VERSION ""

NS_ :

BS_:

BU_: VCM TCM OBDScanT2 ECM

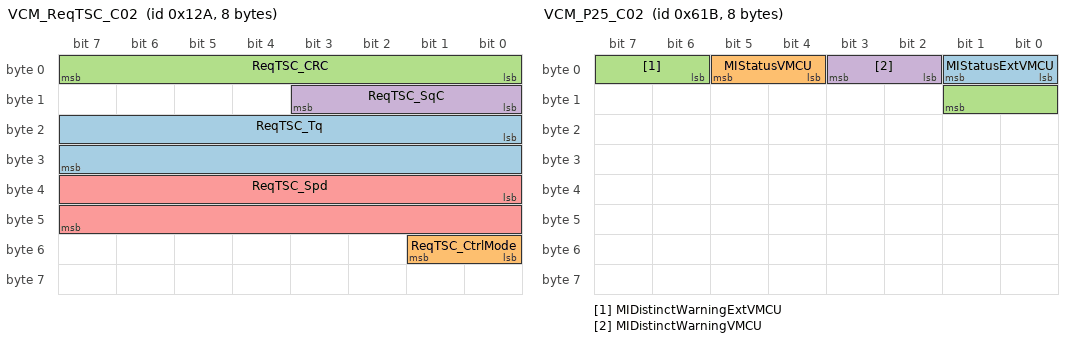
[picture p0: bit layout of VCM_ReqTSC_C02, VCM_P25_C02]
BO_ 298 VCM_ReqTSC_C02: 8 VCM
 SG_ ReqTSC_Tq : 16|16@1+ (1,-32128) [-32128|33407] "Nm"  TCM,ECM
 SG_ ReqTSC_CtrlMode : 48|2@1+ (1,0) [0|0] ""  ECM,TCM
 SG_ ReqTSC_CRC : 0|8@1+ (1,0) [0|255] ""  ECM,TCM
 SG_ ReqTSC_SqC : 8|4@1+ (1,0) [0|14] "NotApplicable"  TCM,ECM
 SG_ ReqTSC_Spd : 32|16@1+ (0.5,-16024) [-16024|16743.5] "rpm"  ECM,TCM

BO_ 568 VCM_P26_C02: 20 VCM
 SG_ EngSystPwrDwn_Rqst : 44|2@1+ (1,0) [0|0] ""  ECM
 SG_ TrnsmSystPwrDwn_SqC : 56|4@1+ (1,0) [0|14] "NotApplicable"  TCM
 SG_ EngSystPwrDwn_CRC : 32|8@1+ (1,0) [0|255] ""  ECM
 SG_ EngCrnk_Rqst : 28|2@1+ (1,0) [0|0] ""  ECM
 SG_ SecuredNeutralPosition_ISig_2 : 79|2@1+ (1,0) [0|0] ""  ECM
 SG_ TransmLowRangeSenseSwitch_ISig_2 : 73|2@1+ (1,0) [0|0] ""  ECM
 SG_ UpDownShiftRqst_CRC : 104|8@1+ (1,0) [0|255] ""  TCM
 SG_ TrnsmSystPwrDwn_Rqst : 60|2@1+ (1,0) [0|0] ""  TCM
 SG_ GearLeverPosition2_SqC : 128|4@1+ (1,0) [0|14] "NotApplicable"  TCM
 SG_ FrontAxleInBumperRange_ISig_2 : 64|2@1+ (1,0) [0|0] ""  TCM
 SG_ RollerBenchModeRequest_ISig_2 : 66|2@1+ (1,0) [0|0] ""  ECM
 SG_ EcnmyPwrSwt_Sts : 12|2@1+ (1,0) [0|0] ""  TCM
 SG_ RearAxleInBumperRange_ISig_2 : 68|2@1+ (1,0) [0|0] ""  TCM
 SG_ EngCrnk_SqC : 24|4@1+ (1,0) [0|14] "NotApplicable"  ECM
 SG_ EcnmyPwrSwt_CRC : 0|8@1+ (1,0) [0|255] ""  TCM
 SG_ EngCrnk_CRC : 16|8@1+ (1,0) [0|255] ""  ECM
 SG_ TractionControlDriverRqst_ISig_2 : 70|3@1+ (1,0) [0|0] ""  ECM
 SG_ EcnmyPwrSwt_SqC : 8|4@1+ (1,0) [0|14] "NotApplicable"  TCM
 SG_ DriveModeSwitchStat_CRC : 88|8@1+ (1,0) [0|255] ""  TCM
 SG_ TransmissionNeutralSwitch : 77|2@1+ (1,0) [0|0] ""  ECM
 SG_ ReverseGearEngaged_ISig_2 : 75|2@1+ (1,0) [0|0] ""  ECM
 SG_ GearLeverPosition2_Rqst : 132|4@1+ (1,0) [0|0] ""  TCM
 SG_ EngSystPwrDwn_SqC : 40|4@1+ (1,0) [0|14] "NotApplicable"  ECM
 SG_ UpDownShiftRqst_Rqst : 116|4@1+ (1,0) [0|0] ""  TCM
 SG_ LevelControlInformation_ISig_2 : 81|4@1+ (1,0) [0|0] ""  TCM
 SG_ TrnsmSystPwrDwn_CRC : 48|8@1+ (1,0) [0|255] ""  TCM
 SG_ DriveModeSwitchStat_SqC : 96|4@1+ (1,0) [0|14] "NotApplicable"  TCM
 SG_ GearLeverPosition2_CRC : 120|8@1+ (1,0) [0|255] ""  TCM
 SG_ DriveModeSwitchStat_Rqst : 100|2@1+ (1,0) [0|0] ""  TCM
 SG_ UpDownShiftRqst_SqC : 112|4@1+ (1,0) [0|14] "NotApplicable"  TCM

BO_ 1563 VCM_P25_C02: 8 VCM
 SG_ MIStatusExtVMCU : 0|2@1+ (1,0) [0|0] ""  ECM
 SG_ MIStatusVMCU : 4|2@1+ (1,0) [0|0] ""  ECM
 SG_ MIDistinctWarningExtVMCU : 6|4@1+ (1,0) [0|0] ""  ECM
 SG_ MIDistinctWarningVMCU : 2|2@1+ (1,0) [0|0] ""  ECM

BO_ 1310 VCM_P24_C02_FCM: 8 TCM
 SG_ VCM_P24_C02_FCS : 0|64@1+ (1,0) [0|0] ""  VCM

BO_ 1309 VCM_P24_C02: 284 VCM
 SG_ HillDataPkgTGW : 0|2272@1+ (1,0) [0|0] ""  TCM

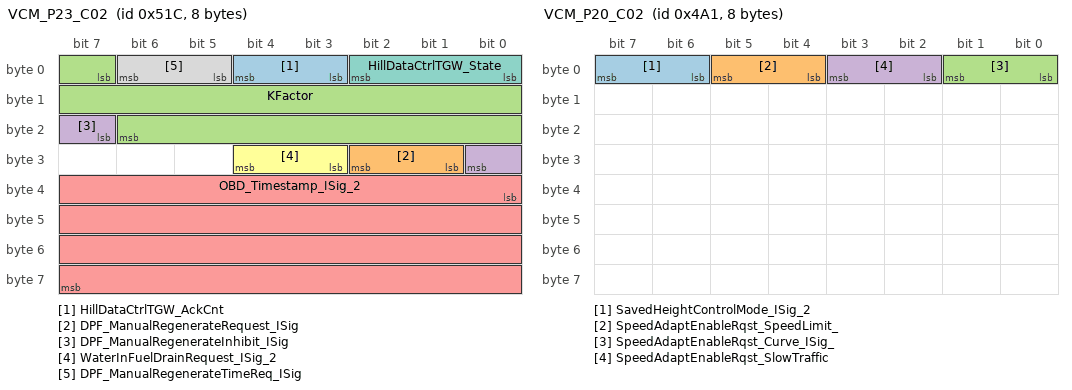
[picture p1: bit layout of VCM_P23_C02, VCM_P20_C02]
BO_ 1308 VCM_P23_C02: 8 VCM
 SG_ HillDataCtrlTGW_AckCnt : 3|2@1+ (1,0) [0|3] ""  TCM
 SG_ DPF_ManualRegenerateRequest_ISig : 25|2@1+ (1,0) [0|0] ""  ECM
 SG_ KFactor : 7|16@1+ (1,0) [0|65535] "NotApplicable"  TCM,ECM
 SG_ DPF_ManualRegenerateInhibit_ISig : 23|2@1+ (1,0) [0|0] ""  ECM
 SG_ OBD_Timestamp_ISig_2 : 32|32@1+ (1,0) [0|4294967295] "s"  ECM
 SG_ WaterInFuelDrainRequest_ISig_2 : 27|2@1+ (1,0) [0|0] ""  ECM
 SG_ HillDataCtrlTGW_State : 0|3@1+ (1,0) [0|0] ""  TCM
 SG_ DPF_ManualRegenerateTimeReq_ISig : 5|2@1+ (1,0) [0|0] ""  ECM

BO_ 1185 VCM_P20_C02: 8 VCM
 SG_ SavedHeightControlMode_ISig_2 : 6|2@1+ (1,0) [0|0] ""  TCM
 SG_ SpeedAdaptEnableRqst_SpeedLimit_ : 4|2@1+ (1,0) [0|0] ""  TCM
 SG_ SpeedAdaptEnableRqst_Curve_ISig_ : 0|2@1+ (1,0) [0|0] ""  TCM
 SG_ SpeedAdaptEnableRqst_SlowTraffic : 2|2@1+ (1,0) [0|0] ""  TCM

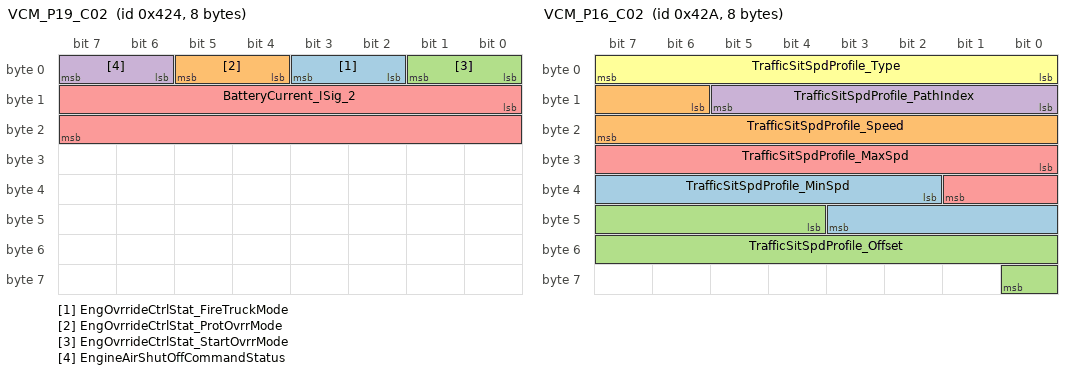
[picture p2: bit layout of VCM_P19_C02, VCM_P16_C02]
BO_ 1060 VCM_P19_C02: 8 VCM
 SG_ EngOvrrideCtrlStat_FireTruckMode : 2|2@1+ (1,0) [0|0] ""  ECM
 SG_ EngOvrrideCtrlStat_ProtOvrrMode : 4|2@1+ (1,0) [0|0] ""  ECM
 SG_ EngOvrrideCtrlStat_StartOvrrMode : 0|2@1+ (1,0) [0|0] ""  ECM
 SG_ EngineAirShutOffCommandStatus : 6|2@1+ (1,0) [0|0] ""  ECM
 SG_ BatteryCurrent_ISig_2 : 8|16@1+ (0.05,-1600) [-1600|1676.75] "A"  ECM

BO_ 932 VCM_P18_C02: 32 VCM
 SG_ VehGcvw : 64|8@1+ (1000,0) [0|255000] "kg"  TCM,ECM
 SG_ ReqdDrvgDir_CRC : 48|8@1+ (1,0) [0|255] ""  TCM
 SG_ SelfStartAssist_stat_ISig_2 : 96|2@1+ (1,0) [0|0] ""  ECM
 SG_ EcoRollEnableRequest_ISig_2 : 88|2@1+ (1,0) [0|0] ""  TCM
 SG_ SelectedEcoCruiseLevel : 101|3@1+ (1,0) [0|0] ""  ECM,TCM
 SG_ CCTrgtSpd_CRC : 216|8@1+ (1,0) [0|255] ""  ECM,TCM
 SG_ ReqdVehLongCtrlM_CRC : 152|8@1+ (1,0) [0|255] ""  TCM,ECM
 SG_ ReqdVehLongCtrlM_SqC : 160|4@1+ (1,0) [0|14] "NotApplicable"  ECM,TCM
 SG_ ACCiRollInhibit : 90|2@1+ (1,0) [0|0] ""  TCM
 SG_ ReqdDrvgMode : 92|4@1+ (1,0) [0|0] ""  TCM
 SG_ CCBTrgtSpd_CRC : 184|8@1+ (1,0) [0|255] ""  ECM,TCM
 SG_ ParkBrake_OBDState : 2|2@1+ (1,0) [0|0] ""  ECM
 SG_ AltParallelOperation : 4|2@1+ (1,0) [0|0] ""  ECM
 SG_ AltLR_cut_offSpeed : 16|5@1+ (1,0) [0|0] ""  ECM
 SG_ CCTrgtSpd_Rqst : 232|16@1+ (0.00390625,0) [0|255.99609375] "Km_per_h"  ECM,TCM
 SG_ MaintOilQuality : 106|3@1+ (1,0) [0|0] ""  ECM
 SG_ AirDryerCoolingFanSpeed_rqst : 136|16@1+ (1,0) [0|65535] "rpm"  ECM
 SG_ VIN_rqst_ISig_2 : 74|1@1+ (1,0) [0|0] ""  ECM,TCM
 SG_ ReqdEcoRoll : 72|2@1+ (1,0) [0|0] ""  TCM
 SG_ CCBTrgtSpd_Rqst : 200|16@1+ (0.00390625,0) [0|255.99609375] "Km_per_h"  TCM,ECM
 SG_ AltVoltageSetValue : 32|8@1+ (0.1,22) [22|47.5] "V"  ECM
 SG_ ACCiSeeDistanceGap : 80|8@1+ (1,-127) [-127|128] "m"  TCM
 SG_ ReqdVehLongCtrlM_Mode : 164|3@1+ (1,0) [0|0] ""  TCM,ECM
 SG_ CCBTrgtSpd_SqC : 192|4@1+ (1,0) [0|14] "NotApplicable"  ECM,TCM
 SG_ ACCoolingFanSpeedRequest : 120|16@1+ (1,0) [0|65535] "rpm"  ECM
 SG_ SpeedAdaptationLevelRqst_ISig_2 : 109|3@1+ (1,0) [0|0] ""  TCM
 SG_ ReqdGear : 75|5@1+ (1,-12) [-12|19] "NotApplicable"  TCM
 SG_ AltExitationCurrentLimit : 40|8@1+ (0.1,0) [0|25.5] "A"  ECM
 SG_ ReqdSGoMode_SqC : 176|4@1+ (1,0) [0|14] "NotApplicable"  ECM,TCM
 SG_ ReqdSGoMode_CRC : 168|8@1+ (1,0) [0|255] ""  ECM,TCM
 SG_ RSLAssistStatus : 98|3@1+ (1,0) [0|0] ""  TCM
 SG_ CCTrgtSpd_SqC : 224|4@1+ (1,0) [0|14] "NotApplicable"  ECM,TCM
 SG_ AcCoolantPumpEngagementRequest_I : 112|8@1+ (0.4,0) [0|102] "Percent"  ECM
 SG_ CruiseControlStates : 6|3@1+ (1,0) [0|0] ""  ECM,TCM
 SG_ AltDataSelectionWordRx : 12|4@1+ (1,0) [0|0] ""  ECM
 SG_ ClutchSwitch_ISig_2 : 0|2@1+ (1,0) [0|0] ""  ECM
 SG_ ReqdSGoMode_Mode : 180|4@1+ (1,0) [0|0] ""  ECM,TCM
 SG_ MaintOilReset : 104|2@1+ (1,0) [0|0] ""  ECM
 SG_ AltLR_RampTime : 21|5@1+ (1,0) [0|0] ""  ECM
 SG_ ReqdDrvgDir_Direction : 60|3@1+ (1,0) [0|0] ""  TCM
 SG_ CACCStatus_ISig_2 : 9|3@1+ (1,0) [0|0] ""  TCM
 SG_ ReqdDrvgDir_SqC : 56|4@1+ (1,0) [0|14] "NotApplicable"  TCM

BO_ 1066 VCM_P16_C02: 8 VCM
 SG_ TrafficSitSpdProfile_MinSpd : 34|10@1+ (0.25,0) [0|255.75] "Km_per_h"  TCM
 SG_ TrafficSitSpdProfile_Speed : 14|10@1+ (0.25,0) [0|255.75] "Km_per_h"  TCM
 SG_ TrafficSitSpdProfile_Offset : 44|13@1+ (1,0) [0|8191] "m"  TCM
 SG_ TrafficSitSpdProfile_PathIndex : 8|6@1+ (1,0) [0|0] ""  TCM
 SG_ TrafficSitSpdProfile_MaxSpd : 24|10@1+ (0.25,0) [0|255.75] "Km_per_h"  TCM
 SG_ TrafficSitSpdProfile_Type : 0|8@1+ (1,0) [0|0] ""  TCM

BO_ 300 VCM_P15_C02: 16 VCM
 SG_ XRSLBTrgtSpd_CRC : 0|8@1+ (1,0) [0|255] ""  TCM,ECM
 SG_ AcceleratorPedalPositionVendor : 88|8@1+ (0.4,0) [0|102] "Percent"  TCM
 SG_ AccPedal_Pos : 80|8@1+ (0.4,0) [0|102] "Percent"  ECM,TCM
 SG_ XRSLTrgtSpd_CRC : 32|8@1+ (1,0) [0|255] ""  ECM
 SG_ AccPedal_Qlty : 76|2@1+ (1,0) [0|0] ""  TCM,ECM
 SG_ XRSLBTrgtSpd_SqC : 8|4@1+ (1,0) [0|14] "NotApplicable"  TCM,ECM
 SG_ XRSLTrgtSpd_SqC : 40|4@1+ (1,0) [0|14] "NotApplicable"  ECM
 SG_ AccPedal_SqC : 72|4@1+ (1,0) [0|14] "NotApplicable"  ECM,TCM
 SG_ XRSLTrgtSpd_Rqst : 48|16@1+ (0.00390625,0) [0|255.99609375] "Km_per_h"  ECM
 SG_ XRSLBTrgtSpd_Rqst : 16|16@1+ (0.00390625,0) [0|255.99609375] "Km_per_h"  ECM,TCM
 SG_ AccPedal_CRC : 64|8@1+ (1,0) [0|255] ""  TCM,ECM

BO_ 1246 VCM_P10_C02: 16 VCM
 SG_ TagAxleLoad_ISig_2 : 0|16@1+ (0.5,0) [0|32767.5] "kg"  TCM
 SG_ SecondaryDriveAxleLoad_ISig_2 : 48|16@1+ (0.5,0) [0|32767.5] "kg"  ECM,TCM
 SG_ StarterMotorReset_rqst : 64|2@1+ (1,0) [0|0] ""  ECM
 SG_ PwtCCUnderSpeedRequest : 72|16@1+ (0.00390625,0) [0|255.99609375] "Km_per_h"  TCM
 SG_ FrontAxle1Load_ISig_2 : 88|16@1+ (0.5,0) [0|32767.5] "kg"  TCM
 SG_ FrontAxle2Load_ISig_2 : 104|16@1+ (0.5,0) [0|32767.5] "kg"  TCM
 SG_ PusherAxleLoad_ISig_2 : 16|16@1+ (0.5,0) [0|32767.5] "kg"  TCM
 SG_ DriveAxleLoad_ISig_2 : 32|16@1+ (0.5,0) [0|32767.5] "kg"  TCM

BO_ 746 VCM_P07_C02: 32 VCM
 SG_ Pto1ConsentRequest : 24|2@1+ (1,0) [0|0] ""  TCM
 SG_ CCBSetSpeed : 48|16@1+ (0.00390625,0) [0|255.99609375] "Km_per_h"  TCM
 SG_ SecondThrottle : 34|2@1+ (1,0) [0|0] ""  ECM
 SG_ CCBTargetSpeedRequest : 80|16@1+ (0.00390625,0) [0|255.99609375] "Km_per_h"  TCM,ECM
 SG_ TransferCaseOrSplitboxPTOMode_IS : 26|2@1+ (1,0) [0|0] ""  TCM
 SG_ PtosStatus_ISig_2 : 36|2@1+ (1,0) [0|0] ""  ECM
 SG_ ConstructionSwitch_stat : 4|2@1+ (1,0) [0|0] ""  TCM
 SG_ RegenInhibitVehicleHeight_ISig_2 : 16|2@1+ (1,0) [0|0] ""  ECM
 SG_ PtoRequest : 18|2@1+ (1,0) [0|0] ""  ECM
 SG_ Pto2Status_ISig_2 : 22|2@1+ (1,0) [0|0] ""  TCM
 SG_ TrailerConnected_ISig_2 : 38|2@1+ (1,0) [0|0] ""  ECM,TCM
 SG_ WarmUp_Request : 42|2@1+ (1,0) [0|0] ""  ECM
 SG_ ParkBrakeReleasePossible_stat_IS : 14|2@1+ (1,0) [0|0] ""  TCM
 SG_ AC_CompressorClutchCmd_ISig_2 : 0|2@1+ (1,0) [0|0] ""  ECM
 SG_ CCSetSpeed_ISig_2 : 64|16@1+ (0.00390625,0) [0|255.99609375] "Km_per_h"  TCM
 SG_ ESCReqEMS_CtrlTrimReq : 160|3@1+ (1,0) [0|0] ""  ECM,TCM
 SG_ ESCReqEMS_CtrlTrimValue : 152|8@1+ (10,0) [0|2550] ""  ECM,TCM
 SG_ Pto1Status_ISig_2 : 20|2@1+ (1,0) [0|0] ""  TCM
 SG_ ESCReqEMS_CtrlTrimStat : 163|3@1+ (1,0) [0|0] ""  ECM,TCM
 SG_ XRSLTargetSpeedRequest : 96|16@1+ (0.00390625,0) [0|255.99609375] "Km_per_h"  ECM
 SG_ CtaGcAlternativeGearStarter : 6|2@1+ (1,0) [0|0] ""  TCM
 SG_ XRSLBTargetSpeedRequest : 128|16@1+ (0.00390625,0) [0|255.99609375] "Km_per_h"  TCM,ECM
 SG_ Pto2ConsentRequest : 32|2@1+ (1,0) [0|0] ""  TCM
 SG_ EngPtoConsumesTorque : 12|2@1+ (1,0) [0|0] ""  TCM
 SG_ ESCReqEMS_CtrlTrimMode : 166|4@1+ (1,0) [0|0] ""  TCM,ECM
 SG_ TrailerABSStatus_ISig_2 : 40|2@1+ (1,0) [0|0] ""  ECM,TCM
 SG_ CtaGcInhibitGearEngaged : 8|2@1+ (1,0) [0|0] ""  TCM
 SG_ RearEndPositionStatus_ISig_2 : 28|3@1+ (1,0) [0|0] ""  TCM
 SG_ StoreIdleValue_ISig_2 : 146|2@1+ (1,0) [0|0] ""  ECM
 SG_ CtaGcReverseInhibit : 10|2@1+ (1,0) [0|0] ""  TCM
 SG_ CCTargetSpeedRequest : 112|16@1+ (0.00390625,0) [0|255.99609375] "Km_per_h"  TCM,ECM
 SG_ AirCompressorStatus_ISig_2 : 2|2@1+ (1,0) [0|0] ""  ECM

BO_ 391 VCM_P02_C02: 48 VCM
 SG_ ReqdLongDist_AllwdBndUppr : 224|16@1+ (0.01,0) [0|655.35] "m"  TCM
 SG_ ParkingBrake_stat_ISig_2 : 62|2@1+ (1,0) [0|0] ""  TCM,ECM
 SG_ ReqdLongSpd_CRC : 80|8@1+ (1,0) [0|255] ""  TCM,ECM
 SG_ RequestedUpshiftDownshiftSteps : 5|3@1+ (1,0) [0|0] ""  TCM
 SG_ LiftAxle1PositionStatus_ISig_2 : 23|3@1+ (1,0) [0|0] ""  TCM
 SG_ EngineSystemPowerDownRequest : 38|2@1+ (1,0) [0|0] ""  ECM
 SG_ LimpHomeSwitch_stat : 14|2@1+ (1,0) [0|0] ""  TCM
 SG_ ReqdLongSpd_SqC : 88|4@1+ (1,0) [0|14] "NotApplicable"  TCM,ECM
 SG_ ReqdLongDist_Distance : 192|16@1+ (0.01,0) [0|655.35] "m"  TCM
 SG_ EconomyPowerSwitch_stat : 16|2@1+ (1,0) [0|0] ""  TCM
 SG_ AcceleratorPedalPositionBackup : 72|8@1+ (0.4,0) [0|102] "Percent"  TCM,ECM
 SG_ UpShiftRequest : 8|2@1+ (1,0) [0|0] ""  ECM,TCM
 SG_ ACCForwardVehicleDistance : 40|8@1+ (1,0) [0|255] "m"  TCM
 SG_ EngineStopRequest : 36|2@1+ (1,0) [0|0] ""  ECM
 SG_ EngineOperationCtrl : 29|3@1+ (1,0) [0|0] ""  TCM,ECM
 SG_ DownShiftRequest : 10|2@1+ (1,0) [0|0] ""  ECM,TCM
 SG_ CM_DisengageDrivelineRequest : 21|2@1+ (1,0) [0|0] ""  TCM
 SG_ ReqdLongAccel_SqC : 152|4@1+ (1,0) [0|14] "NotApplicable"  TCM,ECM
 SG_ ReqdLongAccel_CRC : 144|8@1+ (1,0) [0|255] ""  ECM,TCM
 SG_ TransmSystemPowerDown_rqst : 32|2@1+ (1,0) [0|0] ""  TCM
 SG_ ReqdLongDist_CRC : 176|8@1+ (1,0) [0|255] ""  TCM
 SG_ ACC_Status_ISig_2 : 18|3@1+ (1,0) [0|0] ""  TCM
 SG_ ReqdLongSpd_AllwdBndUppr : 128|16@1+ (0.00390625,0) [0|255.99609375] "Km_per_h"  ECM,TCM
 SG_ XARDACU_AccelDemand : 240|16@1+ (0.00048828125,-15.687) [-15.687|16.31251171875] "m_per_s_squared"  ECM,TCM
 SG_ SteeringValvePositionSetPoint : 64|8@1+ (1,0) [0|255] "Percent"  ECM
 SG_ ParkBrakeActuationStatus_ISig_2 : 26|3@1+ (1,0) [0|0] ""  TCM
 SG_ GearLeverPosition_ISig_2 : 0|4@1+ (1,0) [0|0] ""  ECM,TCM
 SG_ EngineCrankRequest : 34|2@1+ (1,0) [0|0] ""  ECM
 SG_ RequestForHighestGearRatio : 12|2@1+ (1,0) [0|0] ""  TCM
 SG_ XARDACU_ControlMode : 258|2@1+ (1,0) [0|0] ""  ECM,TCM
 SG_ EnginePreheat_rqst : 58|2@1+ (1,0) [0|0] ""  ECM
 SG_ ReqdLongAccel_CtrlMode : 156|2@1+ (1,0) [0|0] ""  TCM,ECM
 SG_ ReqdLongDist_AllwdBndLowr : 208|16@1+ (0.01,0) [0|655.35] "m"  TCM
 SG_ ReqdLongSpd_Spd : 96|16@1+ (0.00390625,0) [0|255.99609375] "Km_per_h"  TCM,ECM
 SG_ ReqdLongSpd_AllwdBndLowr : 112|16@1+ (0.00390625,0) [0|255.99609375] "Km_per_h"  TCM,ECM
 SG_ ACCForwardVehicleSpeed : 48|8@1+ (1,0) [0|255] "Km_per_h"  TCM
 SG_ ReqdLongDist_SqC : 184|4@1+ (1,0) [0|14] "NotApplicable"  TCM
 SG_ ReqdLongAccel_Accel : 160|16@1+ (0.00048828125,-15.687) [-15.687|16.31251171875] "m_per_s_squared"  ECM,TCM

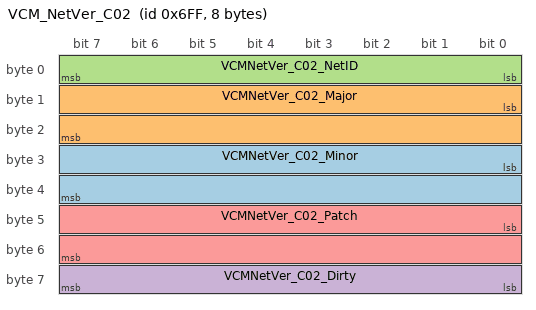
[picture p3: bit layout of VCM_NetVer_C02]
BO_ 1791 VCM_NetVer_C02: 8 VCM
 SG_ VCMNetVer_C02_Minor : 24|16@1+ (1,0) [0|65535] "Not Applicable" Vector__XXX
 SG_ VCMNetVer_C02_Major : 8|16@1+ (1,0) [0|65535] "Not Applicable" Vector__XXX
 SG_ VCMNetVer_C02_NetID : 0|8@1+ (1,0) [0|255] "NotApplicable" Vector__XXX
 SG_ VCMNetVer_C02_Dirty : 56|8@1+ (1,0) [0|255] "NotApplicable" Vector__XXX
 SG_ VCMNetVer_C02_Patch : 40|16@1+ (1,0) [0|65535] "Not Applicable" Vector__XXX

CM_ "COM_MATRIX_T3_2.3.0";
CM_ BU_ VCM "Vehicle Control Module";
CM_ BU_ TCM "Transmission Control Module";
CM_ BU_ ECM "Engine Control Module";
CM_ SG_ 746 ESCReqEMS_CtrlTrimValue "254 Error ; 255 Not available";
CM_ SG_ 391 XARDACU_AccelDemand "65024 - 65279 Error ; 65280 - 65535 Not available";
BA_DEF_ BO_  "GenMsgStartDelayTime" INT 0 0;
BA_DEF_ BO_  "GenMsgDelayTime" INT 0 0;
BA_DEF_ BO_  "GenMsgCycleTime" INT 0 0;
BA_DEF_ BO_  "GenMsgSendType" ENUM  "Cyclic","NotUsed","NotUsed","NotUsed","NotUsed","NotUsed","NotUsed","IfActive","NoMsgSendType","NotUsed";
BA_DEF_ SG_  "GenSigStartValue" INT 0 0;
BA_DEF_ SG_  "GenSigCycleTimeActive" INT 0 0;
BA_DEF_ SG_  "GenSigCycleTime" INT 0 0;
BA_DEF_ SG_  "GenSigSendType" ENUM  "Cyclic","OnWrite","OnWriteWithRepetition","OnChange","OnChangeWithRepetition","IfActive","IfActiveWithRepetition","NoSigSendType","NotUsed","NotUsed","NotUsed","NotUsed","NotUsed";
BA_DEF_  "Baudrate" INT 0 1000000;
BA_DEF_  "NmType" STRING ;
BA_DEF_  "Manufacturer" STRING ;
BA_DEF_  "VersionYear" INT 0 99;
BA_DEF_  "VersionNumber" INT 0 99;
BA_DEF_  "VersionMonth" INT 1 12;
BA_DEF_  "VersionDay" INT 1 31;
BA_DEF_ BO_  "VFrameFormat" ENUM  "StandardCAN","ExtendedCAN","reserved","J1939PG","reserved","reserved","reserved","reserved","reserved","reserved","reserved","reserved","reserved","reserved","StandardCAN_FD","ExtendedCAN_FD";
BA_DEF_ BU_  "TpOwnSystemEcuNumber" HEX 0 255;
BA_DEF_ SG_  "SigType" ENUM  "Default","Range","RangeSigned","ASCII","Discrete","Control","ReferencePGN","DTC","StringDelimiter","StringLength","StringLengthControl";
BA_DEF_ SG_  "SeToolVersion_SIGNAL" STRING ;
BA_DEF_ SG_  "SeToolUniqueID_SIGNAL" STRING ;
BA_DEF_ SG_  "SeToolOwnerSigGroup_SIGNAL" STRING ;
BA_DEF_ SG_  "SeToolOwnerSigGroupID_SIGNAL" STRING ;
BA_DEF_ SG_  "SeToolName_SIGNAL" STRING ;
BA_DEF_ SG_  "SeToolItemID_SIGNAL" STRING ;
BA_DEF_ SG_  "SeToolAncestorID_SIGNAL" STRING ;
BA_DEF_ SG_  "Platform_VMCU1_Sig" ENUM  "No","Yes";
BA_DEF_ BU_  "NmStationAddress" INT 0 255;
BA_DEF_  "NmAsrWaitBusSleepTime" INT 0 65535;
BA_DEF_  "NmAsrTimeoutTime" INT 0 65535;
BA_DEF_  "NmAsrRepeatMessageTime" INT 0 65535;
BA_DEF_ BU_  "NmAsrNodeIdentifier" HEX 0 253;
BA_DEF_ BU_  "NmAsrNode" ENUM  "No","Yes";
BA_DEF_  "NmAsrMessageCount" INT 1 256;
BA_DEF_ BO_  "NmAsrMessage" ENUM  "No","Yes";
BA_DEF_  "NmAsrCanMsgCycleTime" INT 0 65535;
BA_DEF_  "NmAsrBaseAddress" HEX 0 536870911;
BA_DEF_ SG_  "MmAnSignal" ENUM  "No","Yes";
BA_DEF_ BU_  "IsOBDrelevant" ENUM  "No","Yes";
BA_DEF_ SG_  "GenSigMaxLatency" INT 0 65535;
BA_DEF_ SG_  "GenSigILSupport" ENUM  "Yes","No";
BA_DEF_ BO_  "GenMsgILSupport" ENUM  "No","Yes";
BA_DEF_ SG_  "E2EProfile" STRING ;
BA_DEF_  "E2EP05WindowSize" INT 0 65535;
BA_DEF_  "E2EP05ProfileName" STRING ;
BA_DEF_  "E2EP05MinOkStateValid" INT 0 65535;
BA_DEF_  "E2EP05MinOkStateInvalid" INT 0 65535;
BA_DEF_  "E2EP05MinOkStateInit" INT 0 65535;
BA_DEF_  "E2EP05MaxErrorStateValid" INT 0 65535;
BA_DEF_  "E2EP05MaxErrorStateInvalid" INT 0 65535;
BA_DEF_  "E2EP05MaxErrorStateInit" INT 0 65535;
BA_DEF_  "E2EP05MaxDeltaCounter" INT 0 65535;
BA_DEF_  "E2EP01WindowSize" INT 0 65535;
BA_DEF_  "E2EP01SyncCounterInit" INT 0 65535;
BA_DEF_  "E2EP01ProfileName" STRING ;
BA_DEF_  "E2EP01MinOkStateValid" INT 0 65535;
BA_DEF_  "E2EP01MinOkStateInvalid" INT 0 65535;
BA_DEF_  "E2EP01MinOkStateInit" INT 0 65535;
BA_DEF_  "E2EP01MaxNoNewOrRepeatedData" INT 0 65535;
BA_DEF_  "E2EP01MaxErrorStateValid" INT 0 65535;
BA_DEF_  "E2EP01MaxErrorStateInvalid" INT 0 65535;
BA_DEF_  "E2EP01MaxErrorStateInit" INT 0 65535;
BA_DEF_  "E2EP01MaxDeltaCounter" INT 0 65535;
BA_DEF_  "E2EP01DataIdMode" ENUM  "all16Bit","alternating8Bit","lower12Bit","lower8Bit";
BA_DEF_  "E2EP01CounterOffset" INT 0 65535;
BA_DEF_ SG_  "E2EDataLength" INT 0 65535;
BA_DEF_ SG_  "E2EDataId" INT 0 65535;
BA_DEF_ BU_  "DiagnosticClientAddress" HEX 0 255;
BA_DEF_ BO_  "DiagUUDTResponse" ENUM  "No","Yes";
BA_DEF_ BO_  "DiagState" ENUM  "No","Yes";
BA_DEF_ BU_  "DiagRole" ENUM  "None","OBDTester","ExternalTester","InternalTester";
BA_DEF_ BO_  "DiagResponse" ENUM  "No","Yes";
BA_DEF_ BO_  "DiagRequest" ENUM  "No","Yes";
BA_DEF_ BO_  "DiagConnection" HEX 0 65535;
BA_DEF_  "DBName" STRING ;
BA_DEF_ BO_  "CanTpFcFrameId" HEX 0 2147483647;
BA_DEF_ BO_  "CanTpBs" INT 0 255;
BA_DEF_ BO_  "CANFD_BRS" ENUM  "0","1";
BA_DEF_  "BusType" STRING ;
BA_DEF_  "BaudrateCANFD" INT 0 5000000;
BA_DEF_ SG_  "SystemSignalLongSymbol" STRING ;
BA_DEF_REL_ BU_SG_REL_  "GenSigTimeoutTime" INT 0 65535;
BA_DEF_REL_ BU_SG_REL_  "GenSigFirstTimeoutTime" INT 0 65535;
BA_DEF_DEF_  "GenMsgStartDelayTime" 0;
BA_DEF_DEF_  "GenMsgDelayTime" 0;
BA_DEF_DEF_  "GenMsgCycleTime" 0;
BA_DEF_DEF_  "GenMsgSendType" "Cyclic";
BA_DEF_DEF_  "GenSigStartValue" 0;
BA_DEF_DEF_  "GenSigCycleTimeActive" 0;
BA_DEF_DEF_  "GenSigCycleTime" 0;
BA_DEF_DEF_  "GenSigSendType" "Cyclic";
BA_DEF_DEF_  "Baudrate" 500000;
BA_DEF_DEF_  "NmType" "";
BA_DEF_DEF_  "Manufacturer" "VOLVO_AB";
BA_DEF_DEF_  "VersionYear" 0;
BA_DEF_DEF_  "VersionNumber" 0;
BA_DEF_DEF_  "VersionMonth" 1;
BA_DEF_DEF_  "VersionDay" 1;
BA_DEF_DEF_  "VFrameFormat" "ExtendedCAN";
BA_DEF_DEF_  "TpOwnSystemEcuNumber" 0;
BA_DEF_DEF_  "SigType" "Default";
BA_DEF_DEF_  "SeToolVersion_SIGNAL" "";
BA_DEF_DEF_  "SeToolUniqueID_SIGNAL" "";
BA_DEF_DEF_  "SeToolOwnerSigGroup_SIGNAL" "";
BA_DEF_DEF_  "SeToolOwnerSigGroupID_SIGNAL" "";
BA_DEF_DEF_  "SeToolName_SIGNAL" "";
BA_DEF_DEF_  "SeToolItemID_SIGNAL" "";
BA_DEF_DEF_  "SeToolAncestorID_SIGNAL" "";
BA_DEF_DEF_  "Platform_VMCU1_Sig" "No";
BA_DEF_DEF_  "NmStationAddress" 254;
BA_DEF_DEF_  "NmAsrWaitBusSleepTime" 750;
BA_DEF_DEF_  "NmAsrTimeoutTime" 5000;
BA_DEF_DEF_  "NmAsrRepeatMessageTime" 300;
BA_DEF_DEF_  "NmAsrNodeIdentifier" 0;
BA_DEF_DEF_  "NmAsrNode" "Yes";
BA_DEF_DEF_  "NmAsrMessageCount" 256;
BA_DEF_DEF_  "NmAsrMessage" "No";
BA_DEF_DEF_  "NmAsrCanMsgCycleTime" 200;
BA_DEF_DEF_  "NmAsrBaseAddress" 486506496;
BA_DEF_DEF_  "MmAnSignal" "No";
BA_DEF_DEF_  "IsOBDrelevant" "No";
BA_DEF_DEF_  "GenSigMaxLatency" 0;
BA_DEF_DEF_  "GenSigILSupport" "Yes";
BA_DEF_DEF_  "GenMsgILSupport" "Yes";
BA_DEF_DEF_  "E2EProfile" "none";
BA_DEF_DEF_  "E2EP05WindowSize" 5;
BA_DEF_DEF_  "E2EP05ProfileName" "PROFILE_05";
BA_DEF_DEF_  "E2EP05MinOkStateValid" 1;
BA_DEF_DEF_  "E2EP05MinOkStateInvalid" 3;
BA_DEF_DEF_  "E2EP05MinOkStateInit" 1;
BA_DEF_DEF_  "E2EP05MaxErrorStateValid" 3;
BA_DEF_DEF_  "E2EP05MaxErrorStateInvalid" 1;
BA_DEF_DEF_  "E2EP05MaxErrorStateInit" 2;
BA_DEF_DEF_  "E2EP05MaxDeltaCounter" 3;
BA_DEF_DEF_  "E2EP01WindowSize" 5;
BA_DEF_DEF_  "E2EP01SyncCounterInit" 1;
BA_DEF_DEF_  "E2EP01ProfileName" "PROFILE_01";
BA_DEF_DEF_  "E2EP01MinOkStateValid" 1;
BA_DEF_DEF_  "E2EP01MinOkStateInvalid" 3;
BA_DEF_DEF_  "E2EP01MinOkStateInit" 1;
BA_DEF_DEF_  "E2EP01MaxNoNewOrRepeatedData" 5;
BA_DEF_DEF_  "E2EP01MaxErrorStateValid" 3;
BA_DEF_DEF_  "E2EP01MaxErrorStateInvalid" 1;
BA_DEF_DEF_  "E2EP01MaxErrorStateInit" 2;
BA_DEF_DEF_  "E2EP01MaxDeltaCounter" 3;
BA_DEF_DEF_  "E2EP01DataIdMode" "all16Bit";
BA_DEF_DEF_  "E2EP01CounterOffset" 8;
BA_DEF_DEF_  "E2EDataLength" 0;
BA_DEF_DEF_  "E2EDataId" 0;
BA_DEF_DEF_  "DiagnosticClientAddress" 0;
BA_DEF_DEF_  "DiagUUDTResponse" "No";
BA_DEF_DEF_  "DiagState" "No";
BA_DEF_DEF_  "DiagRole" "None";
BA_DEF_DEF_  "DiagResponse" "No";
BA_DEF_DEF_  "DiagRequest" "No";
BA_DEF_DEF_  "DiagConnection" 0;
BA_DEF_DEF_  "DBName" "";
BA_DEF_DEF_  "CanTpFcFrameId" 2147483647;
BA_DEF_DEF_  "CanTpBs" 255;
BA_DEF_DEF_  "CANFD_BRS" "0";
BA_DEF_DEF_  "BusType" "";
BA_DEF_DEF_  "BaudrateCANFD" 0;
BA_DEF_DEF_REL_ "GenSigTimeoutTime" 0;
BA_DEF_DEF_REL_ "GenSigFirstTimeoutTime" 0;
BA_DEF_DEF_  "SystemSignalLongSymbol" "";
BA_ "NmType" "NmAsr";
BA_ "BusType" "CAN FD";
BA_ "BaudrateCANFD" 1000000;
BA_ "VersionDay" 27;
BA_ "VersionMonth" 2;
BA_ "VersionNumber" 1;
BA_ "VersionYear" 23;
BA_ "DBName" "CAN02";
BA_ "DiagRole" BU_ VCM 3;
BA_ "DiagnosticClientAddress" BU_ VCM 244;
BA_ "IsOBDrelevant" BU_ VCM 1;
BA_ "TpOwnSystemEcuNumber" BU_ VCM 36;
BA_ "NmAsrNodeIdentifier" BU_ VCM 36;
BA_ "TpOwnSystemEcuNumber" BU_ TCM 24;
BA_ "NmAsrNodeIdentifier" BU_ TCM 24;
BA_ "NmAsrNode" BU_ OBDScanT2 0;
BA_ "IsOBDrelevant" BU_ ECM 1;
BA_ "TpOwnSystemEcuNumber" BU_ ECM 16;
BA_ "NmAsrNodeIdentifier" BU_ ECM 16;
BA_ "CANFD_BRS" BO_ 298 1;
BA_ "GenMsgCycleTime" BO_ 298 10;
BA_ "VFrameFormat" BO_ 298 14;
BA_ "CANFD_BRS" BO_ 568 1;
BA_ "GenMsgCycleTime" BO_ 568 20;
BA_ "GenMsgStartDelayTime" BO_ 568 15;
BA_ "VFrameFormat" BO_ 568 14;
BA_ "CANFD_BRS" BO_ 1563 1;
BA_ "GenMsgCycleTime" BO_ 1563 1000;
BA_ "GenMsgStartDelayTime" BO_ 1563 50;
BA_ "VFrameFormat" BO_ 1563 14;
BA_ "CANFD_BRS" BO_ 1310 1;
BA_ "GenMsgILSupport" BO_ 1310 0;
BA_ "GenMsgSendType" BO_ 1310 8;
BA_ "VFrameFormat" BO_ 1310 14;
BA_ "CANFD_BRS" BO_ 1309 1;
BA_ "CanTpFcFrameId" BO_ 1309 1310;
BA_ "GenMsgSendType" BO_ 1309 8;
BA_ "GenMsgDelayTime" BO_ 1309 500;
BA_ "GenMsgStartDelayTime" BO_ 1309 50;
BA_ "VFrameFormat" BO_ 1309 14;
BA_ "CANFD_BRS" BO_ 1308 1;
BA_ "GenMsgCycleTime" BO_ 1308 500;
BA_ "GenMsgStartDelayTime" BO_ 1308 205;
BA_ "VFrameFormat" BO_ 1308 14;
BA_ "CANFD_BRS" BO_ 1185 1;
BA_ "GenMsgCycleTime" BO_ 1185 200;
BA_ "GenMsgStartDelayTime" BO_ 1185 25;
BA_ "VFrameFormat" BO_ 1185 14;
BA_ "CANFD_BRS" BO_ 1060 1;
BA_ "GenMsgCycleTime" BO_ 1060 150;
BA_ "GenMsgStartDelayTime" BO_ 1060 50;
BA_ "VFrameFormat" BO_ 1060 14;
BA_ "CANFD_BRS" BO_ 932 1;
BA_ "GenMsgCycleTime" BO_ 932 100;
BA_ "GenMsgStartDelayTime" BO_ 932 50;
BA_ "VFrameFormat" BO_ 932 14;
BA_ "CANFD_BRS" BO_ 1066 1;
BA_ "GenMsgSendType" BO_ 1066 8;
BA_ "GenMsgDelayTime" BO_ 1066 20;
BA_ "VFrameFormat" BO_ 1066 14;
BA_ "CANFD_BRS" BO_ 300 1;
BA_ "GenMsgCycleTime" BO_ 300 10;
BA_ "VFrameFormat" BO_ 300 14;
BA_ "CANFD_BRS" BO_ 1246 1;
BA_ "GenMsgCycleTime" BO_ 1246 250;
BA_ "GenMsgStartDelayTime" BO_ 1246 105;
BA_ "VFrameFormat" BO_ 1246 14;
BA_ "CANFD_BRS" BO_ 746 1;
BA_ "GenMsgCycleTime" BO_ 746 50;
BA_ "GenMsgStartDelayTime" BO_ 746 25;
BA_ "VFrameFormat" BO_ 746 14;
BA_ "CANFD_BRS" BO_ 391 1;
BA_ "GenMsgCycleTime" BO_ 391 20;
BA_ "GenMsgStartDelayTime" BO_ 391 5;
BA_ "VFrameFormat" BO_ 391 14;
BA_ "VFrameFormat" BO_ 1791 0;
BA_ "GenMsgCycleTime" BO_ 1791 1000;
BA_ "GenSigCycleTime" SG_ 298 ReqTSC_Tq 100;
BA_ "GenSigCycleTimeActive" SG_ 298 ReqTSC_Tq 100;
BA_ "GenSigStartValue" SG_ 298 ReqTSC_Tq 65535;
BA_ "GenSigCycleTime" SG_ 298 ReqTSC_CtrlMode 100;
BA_ "GenSigCycleTimeActive" SG_ 298 ReqTSC_CtrlMode 100;
BA_ "GenSigCycleTime" SG_ 298 ReqTSC_CRC 100;
BA_ "GenSigCycleTimeActive" SG_ 298 ReqTSC_CRC 100;
BA_ "GenSigStartValue" SG_ 298 ReqTSC_CRC 255;
BA_ "E2EDataId" SG_ 298 ReqTSC_CRC 156;
BA_ "E2EDataLength" SG_ 298 ReqTSC_CRC 48;
BA_ "E2EProfile" SG_ 298 ReqTSC_CRC "P01";
BA_ "GenSigCycleTime" SG_ 298 ReqTSC_SqC 100;
BA_ "GenSigCycleTimeActive" SG_ 298 ReqTSC_SqC 100;
BA_ "GenSigStartValue" SG_ 298 ReqTSC_SqC 14;
BA_ "GenSigCycleTime" SG_ 298 ReqTSC_Spd 100;
BA_ "GenSigCycleTimeActive" SG_ 298 ReqTSC_Spd 100;
BA_ "GenSigStartValue" SG_ 298 ReqTSC_Spd 65535;
BA_ "GenSigCycleTime" SG_ 568 EngSystPwrDwn_Rqst 100;
BA_ "GenSigCycleTimeActive" SG_ 568 EngSystPwrDwn_Rqst 100;
BA_ "GenSigStartValue" SG_ 568 EngSystPwrDwn_Rqst 3;
BA_ "GenSigMaxLatency" SG_ 568 EngSystPwrDwn_Rqst 20;
BA_ "GenSigCycleTime" SG_ 568 TrnsmSystPwrDwn_SqC 100;
BA_ "GenSigCycleTimeActive" SG_ 568 TrnsmSystPwrDwn_SqC 100;
BA_ "GenSigStartValue" SG_ 568 TrnsmSystPwrDwn_SqC 14;
BA_ "GenSigMaxLatency" SG_ 568 TrnsmSystPwrDwn_SqC 20;
BA_ "GenSigCycleTime" SG_ 568 EngSystPwrDwn_CRC 100;
BA_ "GenSigCycleTimeActive" SG_ 568 EngSystPwrDwn_CRC 100;
BA_ "GenSigStartValue" SG_ 568 EngSystPwrDwn_CRC 255;
BA_ "GenSigMaxLatency" SG_ 568 EngSystPwrDwn_CRC 20;
BA_ "E2EDataId" SG_ 568 EngSystPwrDwn_CRC 173;
BA_ "E2EDataLength" SG_ 568 EngSystPwrDwn_CRC 16;
BA_ "E2EProfile" SG_ 568 EngSystPwrDwn_CRC "P01";
BA_ "GenSigCycleTime" SG_ 568 EngCrnk_Rqst 100;
BA_ "GenSigCycleTimeActive" SG_ 568 EngCrnk_Rqst 100;
BA_ "GenSigStartValue" SG_ 568 EngCrnk_Rqst 3;
BA_ "GenSigMaxLatency" SG_ 568 EngCrnk_Rqst 20;
BA_ "GenSigCycleTime" SG_ 568 SecuredNeutralPosition_ISig_2 100;
BA_ "GenSigCycleTimeActive" SG_ 568 SecuredNeutralPosition_ISig_2 100;
BA_ "GenSigStartValue" SG_ 568 SecuredNeutralPosition_ISig_2 3;
BA_ "GenSigMaxLatency" SG_ 568 SecuredNeutralPosition_ISig_2 20;
BA_ "GenSigCycleTime" SG_ 568 TransmLowRangeSenseSwitch_ISig_2 100;
BA_ "GenSigCycleTimeActive" SG_ 568 TransmLowRangeSenseSwitch_ISig_2 100;
BA_ "GenSigStartValue" SG_ 568 TransmLowRangeSenseSwitch_ISig_2 3;
BA_ "GenSigMaxLatency" SG_ 568 TransmLowRangeSenseSwitch_ISig_2 20;
BA_ "GenSigCycleTime" SG_ 568 UpDownShiftRqst_CRC 100;
BA_ "GenSigCycleTimeActive" SG_ 568 UpDownShiftRqst_CRC 100;
BA_ "E2EDataId" SG_ 568 UpDownShiftRqst_CRC 14;
BA_ "E2EDataLength" SG_ 568 UpDownShiftRqst_CRC 16;
BA_ "E2EProfile" SG_ 568 UpDownShiftRqst_CRC "P01";
BA_ "GenSigCycleTime" SG_ 568 TrnsmSystPwrDwn_Rqst 100;
BA_ "GenSigCycleTimeActive" SG_ 568 TrnsmSystPwrDwn_Rqst 100;
BA_ "GenSigStartValue" SG_ 568 TrnsmSystPwrDwn_Rqst 3;
BA_ "GenSigMaxLatency" SG_ 568 TrnsmSystPwrDwn_Rqst 20;
BA_ "GenSigCycleTime" SG_ 568 GearLeverPosition2_SqC 100;
BA_ "GenSigCycleTimeActive" SG_ 568 GearLeverPosition2_SqC 100;
BA_ "GenSigCycleTime" SG_ 568 FrontAxleInBumperRange_ISig_2 100;
BA_ "GenSigCycleTimeActive" SG_ 568 FrontAxleInBumperRange_ISig_2 100;
BA_ "GenSigStartValue" SG_ 568 FrontAxleInBumperRange_ISig_2 3;
BA_ "GenSigMaxLatency" SG_ 568 FrontAxleInBumperRange_ISig_2 50;
BA_ "GenSigCycleTime" SG_ 568 RollerBenchModeRequest_ISig_2 100;
BA_ "GenSigCycleTimeActive" SG_ 568 RollerBenchModeRequest_ISig_2 100;
BA_ "GenSigStartValue" SG_ 568 RollerBenchModeRequest_ISig_2 3;
BA_ "GenSigMaxLatency" SG_ 568 RollerBenchModeRequest_ISig_2 50;
BA_ "GenSigCycleTime" SG_ 568 EcnmyPwrSwt_Sts 100;
BA_ "GenSigCycleTimeActive" SG_ 568 EcnmyPwrSwt_Sts 100;
BA_ "GenSigStartValue" SG_ 568 EcnmyPwrSwt_Sts 3;
BA_ "GenSigMaxLatency" SG_ 568 EcnmyPwrSwt_Sts 20;
BA_ "GenSigCycleTime" SG_ 568 RearAxleInBumperRange_ISig_2 100;
BA_ "GenSigCycleTimeActive" SG_ 568 RearAxleInBumperRange_ISig_2 100;
BA_ "GenSigStartValue" SG_ 568 RearAxleInBumperRange_ISig_2 3;
BA_ "GenSigMaxLatency" SG_ 568 RearAxleInBumperRange_ISig_2 50;
BA_ "GenSigCycleTime" SG_ 568 EngCrnk_SqC 100;
BA_ "GenSigCycleTimeActive" SG_ 568 EngCrnk_SqC 100;
BA_ "GenSigStartValue" SG_ 568 EngCrnk_SqC 14;
BA_ "GenSigMaxLatency" SG_ 568 EngCrnk_SqC 20;
BA_ "GenSigCycleTime" SG_ 568 EcnmyPwrSwt_CRC 100;
BA_ "GenSigCycleTimeActive" SG_ 568 EcnmyPwrSwt_CRC 100;
BA_ "GenSigStartValue" SG_ 568 EcnmyPwrSwt_CRC 255;
BA_ "GenSigMaxLatency" SG_ 568 EcnmyPwrSwt_CRC 20;
BA_ "E2EDataId" SG_ 568 EcnmyPwrSwt_CRC 171;
BA_ "E2EDataLength" SG_ 568 EcnmyPwrSwt_CRC 16;
BA_ "E2EProfile" SG_ 568 EcnmyPwrSwt_CRC "P01";
BA_ "GenSigCycleTime" SG_ 568 EngCrnk_CRC 100;
BA_ "GenSigCycleTimeActive" SG_ 568 EngCrnk_CRC 100;
BA_ "GenSigStartValue" SG_ 568 EngCrnk_CRC 255;
BA_ "GenSigMaxLatency" SG_ 568 EngCrnk_CRC 20;
BA_ "E2EDataId" SG_ 568 EngCrnk_CRC 174;
BA_ "E2EDataLength" SG_ 568 EngCrnk_CRC 16;
BA_ "E2EProfile" SG_ 568 EngCrnk_CRC "P01";
BA_ "GenSigCycleTime" SG_ 568 TractionControlDriverRqst_ISig_2 100;
BA_ "GenSigCycleTimeActive" SG_ 568 TractionControlDriverRqst_ISig_2 100;
BA_ "GenSigStartValue" SG_ 568 TractionControlDriverRqst_ISig_2 7;
BA_ "GenSigMaxLatency" SG_ 568 TractionControlDriverRqst_ISig_2 50;
BA_ "GenSigCycleTime" SG_ 568 EcnmyPwrSwt_SqC 100;
BA_ "GenSigCycleTimeActive" SG_ 568 EcnmyPwrSwt_SqC 100;
BA_ "GenSigStartValue" SG_ 568 EcnmyPwrSwt_SqC 14;
BA_ "GenSigMaxLatency" SG_ 568 EcnmyPwrSwt_SqC 20;
BA_ "GenSigCycleTime" SG_ 568 DriveModeSwitchStat_CRC 100;
BA_ "GenSigCycleTimeActive" SG_ 568 DriveModeSwitchStat_CRC 100;
BA_ "E2EDataId" SG_ 568 DriveModeSwitchStat_CRC 11;
BA_ "E2EDataLength" SG_ 568 DriveModeSwitchStat_CRC 16;
BA_ "E2EProfile" SG_ 568 DriveModeSwitchStat_CRC "P01";
BA_ "GenSigCycleTime" SG_ 568 TransmissionNeutralSwitch 100;
BA_ "GenSigCycleTimeActive" SG_ 568 TransmissionNeutralSwitch 100;
BA_ "GenSigStartValue" SG_ 568 TransmissionNeutralSwitch 3;
BA_ "GenSigMaxLatency" SG_ 568 TransmissionNeutralSwitch 20;
BA_ "GenSigCycleTime" SG_ 568 ReverseGearEngaged_ISig_2 100;
BA_ "GenSigCycleTimeActive" SG_ 568 ReverseGearEngaged_ISig_2 100;
BA_ "GenSigStartValue" SG_ 568 ReverseGearEngaged_ISig_2 3;
BA_ "GenSigMaxLatency" SG_ 568 ReverseGearEngaged_ISig_2 20;
BA_ "GenSigCycleTime" SG_ 568 GearLeverPosition2_Rqst 100;
BA_ "GenSigCycleTimeActive" SG_ 568 GearLeverPosition2_Rqst 100;
BA_ "GenSigStartValue" SG_ 568 GearLeverPosition2_Rqst 15;
BA_ "GenSigCycleTime" SG_ 568 EngSystPwrDwn_SqC 100;
BA_ "GenSigCycleTimeActive" SG_ 568 EngSystPwrDwn_SqC 100;
BA_ "GenSigStartValue" SG_ 568 EngSystPwrDwn_SqC 14;
BA_ "GenSigMaxLatency" SG_ 568 EngSystPwrDwn_SqC 20;
BA_ "GenSigCycleTime" SG_ 568 UpDownShiftRqst_Rqst 100;
BA_ "GenSigCycleTimeActive" SG_ 568 UpDownShiftRqst_Rqst 100;
BA_ "GenSigStartValue" SG_ 568 UpDownShiftRqst_Rqst 15;
BA_ "GenSigCycleTime" SG_ 568 LevelControlInformation_ISig_2 100;
BA_ "GenSigCycleTimeActive" SG_ 568 LevelControlInformation_ISig_2 100;
BA_ "GenSigStartValue" SG_ 568 LevelControlInformation_ISig_2 15;
BA_ "GenSigMaxLatency" SG_ 568 LevelControlInformation_ISig_2 20;
BA_ "GenSigCycleTime" SG_ 568 TrnsmSystPwrDwn_CRC 100;
BA_ "GenSigCycleTimeActive" SG_ 568 TrnsmSystPwrDwn_CRC 100;
BA_ "GenSigStartValue" SG_ 568 TrnsmSystPwrDwn_CRC 255;
BA_ "GenSigMaxLatency" SG_ 568 TrnsmSystPwrDwn_CRC 20;
BA_ "E2EDataId" SG_ 568 TrnsmSystPwrDwn_CRC 172;
BA_ "E2EDataLength" SG_ 568 TrnsmSystPwrDwn_CRC 16;
BA_ "E2EProfile" SG_ 568 TrnsmSystPwrDwn_CRC "P01";
BA_ "GenSigCycleTime" SG_ 568 DriveModeSwitchStat_SqC 100;
BA_ "GenSigCycleTimeActive" SG_ 568 DriveModeSwitchStat_SqC 100;
BA_ "GenSigCycleTime" SG_ 568 GearLeverPosition2_CRC 100;
BA_ "GenSigCycleTimeActive" SG_ 568 GearLeverPosition2_CRC 100;
BA_ "E2EDataId" SG_ 568 GearLeverPosition2_CRC 13;
BA_ "E2EDataLength" SG_ 568 GearLeverPosition2_CRC 16;
BA_ "E2EProfile" SG_ 568 GearLeverPosition2_CRC "P01";
BA_ "GenSigCycleTime" SG_ 568 DriveModeSwitchStat_Rqst 100;
BA_ "GenSigCycleTimeActive" SG_ 568 DriveModeSwitchStat_Rqst 100;
BA_ "GenSigStartValue" SG_ 568 DriveModeSwitchStat_Rqst 3;
BA_ "GenSigCycleTime" SG_ 568 UpDownShiftRqst_SqC 100;
BA_ "GenSigCycleTimeActive" SG_ 568 UpDownShiftRqst_SqC 100;
BA_ "GenSigCycleTime" SG_ 1563 MIStatusExtVMCU 100;
BA_ "GenSigCycleTimeActive" SG_ 1563 MIStatusExtVMCU 100;
BA_ "GenSigStartValue" SG_ 1563 MIStatusExtVMCU 3;
BA_ "GenSigMaxLatency" SG_ 1563 MIStatusExtVMCU 1000;
BA_ "GenSigCycleTime" SG_ 1563 MIStatusVMCU 100;
BA_ "GenSigCycleTimeActive" SG_ 1563 MIStatusVMCU 100;
BA_ "GenSigStartValue" SG_ 1563 MIStatusVMCU 3;
BA_ "GenSigMaxLatency" SG_ 1563 MIStatusVMCU 1000;
BA_ "GenSigCycleTime" SG_ 1563 MIDistinctWarningExtVMCU 100;
BA_ "GenSigCycleTimeActive" SG_ 1563 MIDistinctWarningExtVMCU 100;
BA_ "GenSigStartValue" SG_ 1563 MIDistinctWarningExtVMCU 15;
BA_ "GenSigMaxLatency" SG_ 1563 MIDistinctWarningExtVMCU 1000;
BA_ "GenSigCycleTime" SG_ 1563 MIDistinctWarningVMCU 100;
BA_ "GenSigCycleTimeActive" SG_ 1563 MIDistinctWarningVMCU 100;
BA_ "GenSigStartValue" SG_ 1563 MIDistinctWarningVMCU 3;
BA_ "GenSigMaxLatency" SG_ 1563 MIDistinctWarningVMCU 1000;
BA_ "GenSigSendType" SG_ 1310 VCM_P24_C02_FCS 7;
BA_ "GenSigSendType" SG_ 1309 HillDataPkgTGW 1;
BA_ "GenSigMaxLatency" SG_ 1309 HillDataPkgTGW 500;
BA_ "GenSigCycleTime" SG_ 1308 HillDataCtrlTGW_AckCnt 100;
BA_ "GenSigCycleTimeActive" SG_ 1308 HillDataCtrlTGW_AckCnt 100;
BA_ "GenSigStartValue" SG_ 1308 HillDataCtrlTGW_AckCnt 3;
BA_ "GenSigMaxLatency" SG_ 1308 HillDataCtrlTGW_AckCnt 500;
BA_ "GenSigCycleTime" SG_ 1308 DPF_ManualRegenerateRequest_ISig 100;
BA_ "GenSigCycleTimeActive" SG_ 1308 DPF_ManualRegenerateRequest_ISig 100;
BA_ "GenSigStartValue" SG_ 1308 DPF_ManualRegenerateRequest_ISig 3;
BA_ "GenSigMaxLatency" SG_ 1308 DPF_ManualRegenerateRequest_ISig 500;
BA_ "SystemSignalLongSymbol" SG_ 1308 DPF_ManualRegenerateRequest_ISig "DPF_ManualRegenerateRequest_ISig_2";
BA_ "GenSigCycleTime" SG_ 1308 KFactor 100;
BA_ "GenSigCycleTimeActive" SG_ 1308 KFactor 100;
BA_ "GenSigStartValue" SG_ 1308 KFactor 65535;
BA_ "GenSigMaxLatency" SG_ 1308 KFactor 500;
BA_ "GenSigCycleTime" SG_ 1308 DPF_ManualRegenerateInhibit_ISig 100;
BA_ "GenSigCycleTimeActive" SG_ 1308 DPF_ManualRegenerateInhibit_ISig 100;
BA_ "GenSigStartValue" SG_ 1308 DPF_ManualRegenerateInhibit_ISig 3;
BA_ "GenSigMaxLatency" SG_ 1308 DPF_ManualRegenerateInhibit_ISig 500;
BA_ "SystemSignalLongSymbol" SG_ 1308 DPF_ManualRegenerateInhibit_ISig "DPF_ManualRegenerateInhibit_ISig_2";
BA_ "GenSigCycleTime" SG_ 1308 OBD_Timestamp_ISig_2 100;
BA_ "GenSigCycleTimeActive" SG_ 1308 OBD_Timestamp_ISig_2 100;
BA_ "GenSigStartValue" SG_ 1308 OBD_Timestamp_ISig_2 4294967295;
BA_ "GenSigMaxLatency" SG_ 1308 OBD_Timestamp_ISig_2 500;
BA_ "GenSigCycleTime" SG_ 1308 WaterInFuelDrainRequest_ISig_2 100;
BA_ "GenSigCycleTimeActive" SG_ 1308 WaterInFuelDrainRequest_ISig_2 100;
BA_ "GenSigStartValue" SG_ 1308 WaterInFuelDrainRequest_ISig_2 3;
BA_ "GenSigMaxLatency" SG_ 1308 WaterInFuelDrainRequest_ISig_2 200;
BA_ "GenSigCycleTime" SG_ 1308 HillDataCtrlTGW_State 100;
BA_ "GenSigCycleTimeActive" SG_ 1308 HillDataCtrlTGW_State 100;
BA_ "GenSigStartValue" SG_ 1308 HillDataCtrlTGW_State 7;
BA_ "GenSigMaxLatency" SG_ 1308 HillDataCtrlTGW_State 500;
BA_ "GenSigCycleTime" SG_ 1308 DPF_ManualRegenerateTimeReq_ISig 100;
BA_ "GenSigCycleTimeActive" SG_ 1308 DPF_ManualRegenerateTimeReq_ISig 100;
BA_ "GenSigStartValue" SG_ 1308 DPF_ManualRegenerateTimeReq_ISig 3;
BA_ "GenSigMaxLatency" SG_ 1308 DPF_ManualRegenerateTimeReq_ISig 500;
BA_ "SystemSignalLongSymbol" SG_ 1308 DPF_ManualRegenerateTimeReq_ISig "DPF_ManualRegenerateTimeReq_ISig_2";
BA_ "GenSigCycleTime" SG_ 1185 SavedHeightControlMode_ISig_2 100;
BA_ "GenSigCycleTimeActive" SG_ 1185 SavedHeightControlMode_ISig_2 100;
BA_ "GenSigStartValue" SG_ 1185 SavedHeightControlMode_ISig_2 3;
BA_ "GenSigMaxLatency" SG_ 1185 SavedHeightControlMode_ISig_2 200;
BA_ "GenSigCycleTime" SG_ 1185 SpeedAdaptEnableRqst_SpeedLimit_ 100;
BA_ "GenSigCycleTimeActive" SG_ 1185 SpeedAdaptEnableRqst_SpeedLimit_ 100;
BA_ "GenSigStartValue" SG_ 1185 SpeedAdaptEnableRqst_SpeedLimit_ 3;
BA_ "GenSigMaxLatency" SG_ 1185 SpeedAdaptEnableRqst_SpeedLimit_ 200;
BA_ "SystemSignalLongSymbol" SG_ 1185 SpeedAdaptEnableRqst_SpeedLimit_ "SpeedAdaptEnableRqst_SpeedLimit_ISig_2";
BA_ "GenSigCycleTime" SG_ 1185 SpeedAdaptEnableRqst_Curve_ISig_ 100;
BA_ "GenSigCycleTimeActive" SG_ 1185 SpeedAdaptEnableRqst_Curve_ISig_ 100;
BA_ "GenSigStartValue" SG_ 1185 SpeedAdaptEnableRqst_Curve_ISig_ 3;
BA_ "GenSigMaxLatency" SG_ 1185 SpeedAdaptEnableRqst_Curve_ISig_ 200;
BA_ "SystemSignalLongSymbol" SG_ 1185 SpeedAdaptEnableRqst_Curve_ISig_ "SpeedAdaptEnableRqst_Curve_ISig_2";
BA_ "GenSigCycleTime" SG_ 1185 SpeedAdaptEnableRqst_SlowTraffic 100;
BA_ "GenSigCycleTimeActive" SG_ 1185 SpeedAdaptEnableRqst_SlowTraffic 100;
BA_ "GenSigStartValue" SG_ 1185 SpeedAdaptEnableRqst_SlowTraffic 3;
BA_ "GenSigMaxLatency" SG_ 1185 SpeedAdaptEnableRqst_SlowTraffic 200;
BA_ "SystemSignalLongSymbol" SG_ 1185 SpeedAdaptEnableRqst_SlowTraffic "SpeedAdaptEnableRqst_SlowTraffic_ISig_2";
BA_ "GenSigCycleTime" SG_ 1060 EngOvrrideCtrlStat_FireTruckMode 100;
BA_ "GenSigCycleTimeActive" SG_ 1060 EngOvrrideCtrlStat_FireTruckMode 100;
BA_ "GenSigStartValue" SG_ 1060 EngOvrrideCtrlStat_FireTruckMode 3;
BA_ "GenSigMaxLatency" SG_ 1060 EngOvrrideCtrlStat_FireTruckMode 150;
BA_ "GenSigCycleTime" SG_ 1060 EngOvrrideCtrlStat_ProtOvrrMode 100;
BA_ "GenSigCycleTimeActive" SG_ 1060 EngOvrrideCtrlStat_ProtOvrrMode 100;
BA_ "GenSigStartValue" SG_ 1060 EngOvrrideCtrlStat_ProtOvrrMode 3;
BA_ "GenSigMaxLatency" SG_ 1060 EngOvrrideCtrlStat_ProtOvrrMode 150;
BA_ "GenSigCycleTime" SG_ 1060 EngOvrrideCtrlStat_StartOvrrMode 100;
BA_ "GenSigCycleTimeActive" SG_ 1060 EngOvrrideCtrlStat_StartOvrrMode 100;
BA_ "GenSigStartValue" SG_ 1060 EngOvrrideCtrlStat_StartOvrrMode 3;
BA_ "GenSigMaxLatency" SG_ 1060 EngOvrrideCtrlStat_StartOvrrMode 150;
BA_ "GenSigCycleTime" SG_ 1060 EngineAirShutOffCommandStatus 100;
BA_ "GenSigCycleTimeActive" SG_ 1060 EngineAirShutOffCommandStatus 100;
BA_ "GenSigStartValue" SG_ 1060 EngineAirShutOffCommandStatus 3;
BA_ "GenSigMaxLatency" SG_ 1060 EngineAirShutOffCommandStatus 150;
BA_ "GenSigCycleTime" SG_ 1060 BatteryCurrent_ISig_2 100;
BA_ "GenSigCycleTimeActive" SG_ 1060 BatteryCurrent_ISig_2 100;
BA_ "GenSigStartValue" SG_ 1060 BatteryCurrent_ISig_2 65535;
BA_ "GenSigCycleTime" SG_ 932 VehGcvw 100;
BA_ "GenSigCycleTimeActive" SG_ 932 VehGcvw 100;
BA_ "GenSigStartValue" SG_ 932 VehGcvw 255;
BA_ "GenSigCycleTime" SG_ 932 ReqdDrvgDir_CRC 100;
BA_ "GenSigCycleTimeActive" SG_ 932 ReqdDrvgDir_CRC 100;
BA_ "GenSigStartValue" SG_ 932 ReqdDrvgDir_CRC 255;
BA_ "E2EDataId" SG_ 932 ReqdDrvgDir_CRC 152;
BA_ "E2EDataLength" SG_ 932 ReqdDrvgDir_CRC 16;
BA_ "E2EProfile" SG_ 932 ReqdDrvgDir_CRC "P01";
BA_ "GenSigCycleTime" SG_ 932 SelfStartAssist_stat_ISig_2 100;
BA_ "GenSigCycleTimeActive" SG_ 932 SelfStartAssist_stat_ISig_2 100;
BA_ "GenSigStartValue" SG_ 932 SelfStartAssist_stat_ISig_2 3;
BA_ "GenSigMaxLatency" SG_ 932 SelfStartAssist_stat_ISig_2 250;
BA_ "GenSigCycleTime" SG_ 932 EcoRollEnableRequest_ISig_2 100;
BA_ "GenSigCycleTimeActive" SG_ 932 EcoRollEnableRequest_ISig_2 100;
BA_ "GenSigStartValue" SG_ 932 EcoRollEnableRequest_ISig_2 3;
BA_ "GenSigMaxLatency" SG_ 932 EcoRollEnableRequest_ISig_2 200;
BA_ "GenSigCycleTime" SG_ 932 SelectedEcoCruiseLevel 100;
BA_ "GenSigCycleTimeActive" SG_ 932 SelectedEcoCruiseLevel 100;
BA_ "GenSigStartValue" SG_ 932 SelectedEcoCruiseLevel 7;
BA_ "GenSigMaxLatency" SG_ 932 SelectedEcoCruiseLevel 200;
BA_ "GenSigCycleTime" SG_ 932 CCTrgtSpd_CRC 100;
BA_ "GenSigCycleTimeActive" SG_ 932 CCTrgtSpd_CRC 100;
BA_ "GenSigStartValue" SG_ 932 CCTrgtSpd_CRC 255;
BA_ "GenSigMaxLatency" SG_ 932 CCTrgtSpd_CRC 100;
BA_ "E2EDataId" SG_ 932 CCTrgtSpd_CRC 167;
BA_ "E2EDataLength" SG_ 932 CCTrgtSpd_CRC 32;
BA_ "E2EProfile" SG_ 932 CCTrgtSpd_CRC "P01";
BA_ "GenSigCycleTime" SG_ 932 ReqdVehLongCtrlM_CRC 100;
BA_ "GenSigCycleTimeActive" SG_ 932 ReqdVehLongCtrlM_CRC 100;
BA_ "GenSigStartValue" SG_ 932 ReqdVehLongCtrlM_CRC 255;
BA_ "E2EDataId" SG_ 932 ReqdVehLongCtrlM_CRC 151;
BA_ "E2EDataLength" SG_ 932 ReqdVehLongCtrlM_CRC 16;
BA_ "E2EProfile" SG_ 932 ReqdVehLongCtrlM_CRC "P01";
BA_ "GenSigCycleTime" SG_ 932 ReqdVehLongCtrlM_SqC 100;
BA_ "GenSigCycleTimeActive" SG_ 932 ReqdVehLongCtrlM_SqC 100;
BA_ "GenSigStartValue" SG_ 932 ReqdVehLongCtrlM_SqC 14;
BA_ "GenSigCycleTime" SG_ 932 ACCiRollInhibit 100;
BA_ "GenSigCycleTimeActive" SG_ 932 ACCiRollInhibit 100;
BA_ "GenSigStartValue" SG_ 932 ACCiRollInhibit 3;
BA_ "GenSigMaxLatency" SG_ 932 ACCiRollInhibit 40;
BA_ "GenSigCycleTime" SG_ 932 ReqdDrvgMode 100;
BA_ "GenSigCycleTimeActive" SG_ 932 ReqdDrvgMode 100;
BA_ "GenSigStartValue" SG_ 932 ReqdDrvgMode 15;
BA_ "GenSigCycleTime" SG_ 932 CCBTrgtSpd_CRC 100;
BA_ "GenSigCycleTimeActive" SG_ 932 CCBTrgtSpd_CRC 100;
BA_ "GenSigStartValue" SG_ 932 CCBTrgtSpd_CRC 255;
BA_ "GenSigMaxLatency" SG_ 932 CCBTrgtSpd_CRC 100;
BA_ "E2EDataId" SG_ 932 CCBTrgtSpd_CRC 168;
BA_ "E2EDataLength" SG_ 932 CCBTrgtSpd_CRC 32;
BA_ "E2EProfile" SG_ 932 CCBTrgtSpd_CRC "P01";
BA_ "GenSigCycleTime" SG_ 932 ParkBrake_OBDState 100;
BA_ "GenSigCycleTimeActive" SG_ 932 ParkBrake_OBDState 100;
BA_ "GenSigStartValue" SG_ 932 ParkBrake_OBDState 3;
BA_ "GenSigMaxLatency" SG_ 932 ParkBrake_OBDState 100;
BA_ "GenSigCycleTime" SG_ 932 AltParallelOperation 100;
BA_ "GenSigCycleTimeActive" SG_ 932 AltParallelOperation 100;
BA_ "GenSigStartValue" SG_ 932 AltParallelOperation 3;
BA_ "GenSigMaxLatency" SG_ 932 AltParallelOperation 100;
BA_ "GenSigCycleTime" SG_ 932 AltLR_cut_offSpeed 100;
BA_ "GenSigCycleTimeActive" SG_ 932 AltLR_cut_offSpeed 100;
BA_ "GenSigStartValue" SG_ 932 AltLR_cut_offSpeed 31;
BA_ "GenSigMaxLatency" SG_ 932 AltLR_cut_offSpeed 100;
BA_ "GenSigCycleTime" SG_ 932 CCTrgtSpd_Rqst 100;
BA_ "GenSigCycleTimeActive" SG_ 932 CCTrgtSpd_Rqst 100;
BA_ "GenSigStartValue" SG_ 932 CCTrgtSpd_Rqst 65535;
BA_ "GenSigMaxLatency" SG_ 932 CCTrgtSpd_Rqst 100;
BA_ "GenSigCycleTime" SG_ 932 MaintOilQuality 100;
BA_ "GenSigCycleTimeActive" SG_ 932 MaintOilQuality 100;
BA_ "GenSigStartValue" SG_ 932 MaintOilQuality 7;
BA_ "GenSigMaxLatency" SG_ 932 MaintOilQuality 100;
BA_ "GenSigCycleTime" SG_ 932 AirDryerCoolingFanSpeed_rqst 100;
BA_ "GenSigCycleTimeActive" SG_ 932 AirDryerCoolingFanSpeed_rqst 100;
BA_ "GenSigStartValue" SG_ 932 AirDryerCoolingFanSpeed_rqst 65535;
BA_ "GenSigMaxLatency" SG_ 932 AirDryerCoolingFanSpeed_rqst 100;
BA_ "GenSigCycleTime" SG_ 932 VIN_rqst_ISig_2 100;
BA_ "GenSigCycleTimeActive" SG_ 932 VIN_rqst_ISig_2 100;
BA_ "GenSigMaxLatency" SG_ 932 VIN_rqst_ISig_2 100;
BA_ "GenSigCycleTime" SG_ 932 ReqdEcoRoll 100;
BA_ "GenSigCycleTimeActive" SG_ 932 ReqdEcoRoll 100;
BA_ "GenSigStartValue" SG_ 932 ReqdEcoRoll 3;
BA_ "GenSigCycleTime" SG_ 932 CCBTrgtSpd_Rqst 100;
BA_ "GenSigCycleTimeActive" SG_ 932 CCBTrgtSpd_Rqst 100;
BA_ "GenSigStartValue" SG_ 932 CCBTrgtSpd_Rqst 65535;
BA_ "GenSigMaxLatency" SG_ 932 CCBTrgtSpd_Rqst 100;
BA_ "GenSigCycleTime" SG_ 932 AltVoltageSetValue 100;
BA_ "GenSigCycleTimeActive" SG_ 932 AltVoltageSetValue 100;
BA_ "GenSigStartValue" SG_ 932 AltVoltageSetValue 255;
BA_ "GenSigMaxLatency" SG_ 932 AltVoltageSetValue 100;
BA_ "GenSigCycleTime" SG_ 932 ACCiSeeDistanceGap 100;
BA_ "GenSigCycleTimeActive" SG_ 932 ACCiSeeDistanceGap 100;
BA_ "GenSigStartValue" SG_ 932 ACCiSeeDistanceGap 255;
BA_ "GenSigMaxLatency" SG_ 932 ACCiSeeDistanceGap 100;
BA_ "GenSigCycleTime" SG_ 932 ReqdVehLongCtrlM_Mode 100;
BA_ "GenSigCycleTimeActive" SG_ 932 ReqdVehLongCtrlM_Mode 100;
BA_ "GenSigStartValue" SG_ 932 ReqdVehLongCtrlM_Mode 7;
BA_ "GenSigCycleTime" SG_ 932 CCBTrgtSpd_SqC 100;
BA_ "GenSigCycleTimeActive" SG_ 932 CCBTrgtSpd_SqC 100;
BA_ "GenSigStartValue" SG_ 932 CCBTrgtSpd_SqC 14;
BA_ "GenSigMaxLatency" SG_ 932 CCBTrgtSpd_SqC 100;
BA_ "GenSigCycleTime" SG_ 932 ACCoolingFanSpeedRequest 100;
BA_ "GenSigCycleTimeActive" SG_ 932 ACCoolingFanSpeedRequest 100;
BA_ "GenSigStartValue" SG_ 932 ACCoolingFanSpeedRequest 65535;
BA_ "GenSigMaxLatency" SG_ 932 ACCoolingFanSpeedRequest 100;
BA_ "GenSigCycleTime" SG_ 932 SpeedAdaptationLevelRqst_ISig_2 100;
BA_ "GenSigCycleTimeActive" SG_ 932 SpeedAdaptationLevelRqst_ISig_2 100;
BA_ "GenSigStartValue" SG_ 932 SpeedAdaptationLevelRqst_ISig_2 7;
BA_ "GenSigMaxLatency" SG_ 932 SpeedAdaptationLevelRqst_ISig_2 200;
BA_ "GenSigCycleTime" SG_ 932 ReqdGear 100;
BA_ "GenSigCycleTimeActive" SG_ 932 ReqdGear 100;
BA_ "GenSigStartValue" SG_ 932 ReqdGear 31;
BA_ "GenSigCycleTime" SG_ 932 AltExitationCurrentLimit 100;
BA_ "GenSigCycleTimeActive" SG_ 932 AltExitationCurrentLimit 100;
BA_ "GenSigStartValue" SG_ 932 AltExitationCurrentLimit 255;
BA_ "GenSigMaxLatency" SG_ 932 AltExitationCurrentLimit 100;
BA_ "GenSigCycleTime" SG_ 932 ReqdSGoMode_SqC 100;
BA_ "GenSigCycleTimeActive" SG_ 932 ReqdSGoMode_SqC 100;
BA_ "GenSigStartValue" SG_ 932 ReqdSGoMode_SqC 14;
BA_ "GenSigCycleTime" SG_ 932 ReqdSGoMode_CRC 100;
BA_ "GenSigCycleTimeActive" SG_ 932 ReqdSGoMode_CRC 100;
BA_ "GenSigStartValue" SG_ 932 ReqdSGoMode_CRC 255;
BA_ "E2EDataId" SG_ 932 ReqdSGoMode_CRC 155;
BA_ "E2EDataLength" SG_ 932 ReqdSGoMode_CRC 16;
BA_ "E2EProfile" SG_ 932 ReqdSGoMode_CRC "P01";
BA_ "GenSigCycleTime" SG_ 932 RSLAssistStatus 100;
BA_ "GenSigCycleTimeActive" SG_ 932 RSLAssistStatus 100;
BA_ "GenSigStartValue" SG_ 932 RSLAssistStatus 7;
BA_ "GenSigMaxLatency" SG_ 932 RSLAssistStatus 250;
BA_ "GenSigCycleTime" SG_ 932 CCTrgtSpd_SqC 100;
BA_ "GenSigCycleTimeActive" SG_ 932 CCTrgtSpd_SqC 100;
BA_ "GenSigStartValue" SG_ 932 CCTrgtSpd_SqC 14;
BA_ "GenSigMaxLatency" SG_ 932 CCTrgtSpd_SqC 100;
BA_ "GenSigCycleTime" SG_ 932 AcCoolantPumpEngagementRequest_I 100;
BA_ "GenSigCycleTimeActive" SG_ 932 AcCoolantPumpEngagementRequest_I 100;
BA_ "GenSigStartValue" SG_ 932 AcCoolantPumpEngagementRequest_I 255;
BA_ "GenSigMaxLatency" SG_ 932 AcCoolantPumpEngagementRequest_I 100;
BA_ "SystemSignalLongSymbol" SG_ 932 AcCoolantPumpEngagementRequest_I "AcCoolantPumpEngagementRequest_ISig_2";
BA_ "GenSigCycleTime" SG_ 932 CruiseControlStates 100;
BA_ "GenSigCycleTimeActive" SG_ 932 CruiseControlStates 100;
BA_ "GenSigStartValue" SG_ 932 CruiseControlStates 7;
BA_ "GenSigMaxLatency" SG_ 932 CruiseControlStates 100;
BA_ "GenSigCycleTime" SG_ 932 AltDataSelectionWordRx 100;
BA_ "GenSigCycleTimeActive" SG_ 932 AltDataSelectionWordRx 100;
BA_ "GenSigStartValue" SG_ 932 AltDataSelectionWordRx 15;
BA_ "GenSigMaxLatency" SG_ 932 AltDataSelectionWordRx 100;
BA_ "GenSigCycleTime" SG_ 932 ClutchSwitch_ISig_2 100;
BA_ "GenSigCycleTimeActive" SG_ 932 ClutchSwitch_ISig_2 100;
BA_ "GenSigStartValue" SG_ 932 ClutchSwitch_ISig_2 3;
BA_ "GenSigMaxLatency" SG_ 932 ClutchSwitch_ISig_2 100;
BA_ "GenSigCycleTime" SG_ 932 ReqdSGoMode_Mode 100;
BA_ "GenSigCycleTimeActive" SG_ 932 ReqdSGoMode_Mode 100;
BA_ "GenSigStartValue" SG_ 932 ReqdSGoMode_Mode 15;
BA_ "GenSigCycleTime" SG_ 932 MaintOilReset 100;
BA_ "GenSigCycleTimeActive" SG_ 932 MaintOilReset 100;
BA_ "GenSigStartValue" SG_ 932 MaintOilReset 3;
BA_ "GenSigMaxLatency" SG_ 932 MaintOilReset 100;
BA_ "GenSigCycleTime" SG_ 932 AltLR_RampTime 100;
BA_ "GenSigCycleTimeActive" SG_ 932 AltLR_RampTime 100;
BA_ "GenSigStartValue" SG_ 932 AltLR_RampTime 31;
BA_ "GenSigMaxLatency" SG_ 932 AltLR_RampTime 100;
BA_ "GenSigCycleTime" SG_ 932 ReqdDrvgDir_Direction 100;
BA_ "GenSigCycleTimeActive" SG_ 932 ReqdDrvgDir_Direction 100;
BA_ "GenSigStartValue" SG_ 932 ReqdDrvgDir_Direction 7;
BA_ "GenSigCycleTime" SG_ 932 CACCStatus_ISig_2 100;
BA_ "GenSigCycleTimeActive" SG_ 932 CACCStatus_ISig_2 100;
BA_ "GenSigStartValue" SG_ 932 CACCStatus_ISig_2 7;
BA_ "GenSigMaxLatency" SG_ 932 CACCStatus_ISig_2 100;
BA_ "GenSigCycleTime" SG_ 932 ReqdDrvgDir_SqC 100;
BA_ "GenSigCycleTimeActive" SG_ 932 ReqdDrvgDir_SqC 100;
BA_ "GenSigStartValue" SG_ 932 ReqdDrvgDir_SqC 14;
BA_ "GenSigSendType" SG_ 1066 TrafficSitSpdProfile_MinSpd 1;
BA_ "GenSigStartValue" SG_ 1066 TrafficSitSpdProfile_MinSpd 1023;
BA_ "GenSigSendType" SG_ 1066 TrafficSitSpdProfile_Speed 1;
BA_ "GenSigStartValue" SG_ 1066 TrafficSitSpdProfile_Speed 1023;
BA_ "GenSigSendType" SG_ 1066 TrafficSitSpdProfile_Offset 1;
BA_ "GenSigStartValue" SG_ 1066 TrafficSitSpdProfile_Offset 8191;
BA_ "GenSigSendType" SG_ 1066 TrafficSitSpdProfile_PathIndex 1;
BA_ "GenSigStartValue" SG_ 1066 TrafficSitSpdProfile_PathIndex 63;
BA_ "GenSigSendType" SG_ 1066 TrafficSitSpdProfile_MaxSpd 1;
BA_ "GenSigStartValue" SG_ 1066 TrafficSitSpdProfile_MaxSpd 1023;
BA_ "GenSigSendType" SG_ 1066 TrafficSitSpdProfile_Type 1;
BA_ "GenSigStartValue" SG_ 1066 TrafficSitSpdProfile_Type 255;
BA_ "GenSigCycleTime" SG_ 300 XRSLBTrgtSpd_CRC 100;
BA_ "GenSigCycleTimeActive" SG_ 300 XRSLBTrgtSpd_CRC 100;
BA_ "GenSigStartValue" SG_ 300 XRSLBTrgtSpd_CRC 255;
BA_ "GenSigMaxLatency" SG_ 300 XRSLBTrgtSpd_CRC 45;
BA_ "E2EDataId" SG_ 300 XRSLBTrgtSpd_CRC 170;
BA_ "E2EDataLength" SG_ 300 XRSLBTrgtSpd_CRC 32;
BA_ "E2EProfile" SG_ 300 XRSLBTrgtSpd_CRC "P01";
BA_ "GenSigCycleTime" SG_ 300 AcceleratorPedalPositionVendor 100;
BA_ "GenSigCycleTimeActive" SG_ 300 AcceleratorPedalPositionVendor 100;
BA_ "GenSigStartValue" SG_ 300 AcceleratorPedalPositionVendor 255;
BA_ "GenSigMaxLatency" SG_ 300 AcceleratorPedalPositionVendor 10;
BA_ "GenSigCycleTime" SG_ 300 AccPedal_Pos 100;
BA_ "GenSigCycleTimeActive" SG_ 300 AccPedal_Pos 100;
BA_ "GenSigStartValue" SG_ 300 AccPedal_Pos 255;
BA_ "GenSigMaxLatency" SG_ 300 AccPedal_Pos 10;
BA_ "GenSigCycleTime" SG_ 300 XRSLTrgtSpd_CRC 100;
BA_ "GenSigCycleTimeActive" SG_ 300 XRSLTrgtSpd_CRC 100;
BA_ "GenSigStartValue" SG_ 300 XRSLTrgtSpd_CRC 255;
BA_ "GenSigMaxLatency" SG_ 300 XRSLTrgtSpd_CRC 45;
BA_ "E2EDataId" SG_ 300 XRSLTrgtSpd_CRC 169;
BA_ "E2EDataLength" SG_ 300 XRSLTrgtSpd_CRC 32;
BA_ "E2EProfile" SG_ 300 XRSLTrgtSpd_CRC "P01";
BA_ "GenSigCycleTime" SG_ 300 AccPedal_Qlty 100;
BA_ "GenSigCycleTimeActive" SG_ 300 AccPedal_Qlty 100;
BA_ "GenSigStartValue" SG_ 300 AccPedal_Qlty 3;
BA_ "GenSigMaxLatency" SG_ 300 AccPedal_Qlty 10;
BA_ "GenSigCycleTime" SG_ 300 XRSLBTrgtSpd_SqC 100;
BA_ "GenSigCycleTimeActive" SG_ 300 XRSLBTrgtSpd_SqC 100;
BA_ "GenSigStartValue" SG_ 300 XRSLBTrgtSpd_SqC 14;
BA_ "GenSigMaxLatency" SG_ 300 XRSLBTrgtSpd_SqC 45;
BA_ "GenSigCycleTime" SG_ 300 XRSLTrgtSpd_SqC 100;
BA_ "GenSigCycleTimeActive" SG_ 300 XRSLTrgtSpd_SqC 100;
BA_ "GenSigStartValue" SG_ 300 XRSLTrgtSpd_SqC 14;
BA_ "GenSigMaxLatency" SG_ 300 XRSLTrgtSpd_SqC 45;
BA_ "GenSigCycleTime" SG_ 300 AccPedal_SqC 100;
BA_ "GenSigCycleTimeActive" SG_ 300 AccPedal_SqC 100;
BA_ "GenSigStartValue" SG_ 300 AccPedal_SqC 14;
BA_ "GenSigMaxLatency" SG_ 300 AccPedal_SqC 10;
BA_ "GenSigCycleTime" SG_ 300 XRSLTrgtSpd_Rqst 100;
BA_ "GenSigCycleTimeActive" SG_ 300 XRSLTrgtSpd_Rqst 100;
BA_ "GenSigStartValue" SG_ 300 XRSLTrgtSpd_Rqst 65535;
BA_ "GenSigMaxLatency" SG_ 300 XRSLTrgtSpd_Rqst 45;
BA_ "GenSigCycleTime" SG_ 300 XRSLBTrgtSpd_Rqst 100;
BA_ "GenSigCycleTimeActive" SG_ 300 XRSLBTrgtSpd_Rqst 100;
BA_ "GenSigStartValue" SG_ 300 XRSLBTrgtSpd_Rqst 65535;
BA_ "GenSigMaxLatency" SG_ 300 XRSLBTrgtSpd_Rqst 45;
BA_ "GenSigCycleTime" SG_ 300 AccPedal_CRC 100;
BA_ "GenSigCycleTimeActive" SG_ 300 AccPedal_CRC 100;
BA_ "GenSigStartValue" SG_ 300 AccPedal_CRC 255;
BA_ "GenSigMaxLatency" SG_ 300 AccPedal_CRC 10;
BA_ "E2EDataId" SG_ 300 AccPedal_CRC 166;
BA_ "E2EDataLength" SG_ 300 AccPedal_CRC 24;
BA_ "E2EProfile" SG_ 300 AccPedal_CRC "P01";
BA_ "GenSigCycleTime" SG_ 1246 TagAxleLoad_ISig_2 100;
BA_ "GenSigCycleTimeActive" SG_ 1246 TagAxleLoad_ISig_2 100;
BA_ "GenSigStartValue" SG_ 1246 TagAxleLoad_ISig_2 65535;
BA_ "GenSigMaxLatency" SG_ 1246 TagAxleLoad_ISig_2 250;
BA_ "GenSigCycleTime" SG_ 1246 SecondaryDriveAxleLoad_ISig_2 100;
BA_ "GenSigCycleTimeActive" SG_ 1246 SecondaryDriveAxleLoad_ISig_2 100;
BA_ "GenSigStartValue" SG_ 1246 SecondaryDriveAxleLoad_ISig_2 65535;
BA_ "GenSigMaxLatency" SG_ 1246 SecondaryDriveAxleLoad_ISig_2 250;
BA_ "GenSigCycleTime" SG_ 1246 StarterMotorReset_rqst 100;
BA_ "GenSigCycleTimeActive" SG_ 1246 StarterMotorReset_rqst 100;
BA_ "GenSigStartValue" SG_ 1246 StarterMotorReset_rqst 3;
BA_ "GenSigMaxLatency" SG_ 1246 StarterMotorReset_rqst 250;
BA_ "GenSigCycleTime" SG_ 1246 PwtCCUnderSpeedRequest 100;
BA_ "GenSigCycleTimeActive" SG_ 1246 PwtCCUnderSpeedRequest 100;
BA_ "GenSigStartValue" SG_ 1246 PwtCCUnderSpeedRequest 65535;
BA_ "GenSigMaxLatency" SG_ 1246 PwtCCUnderSpeedRequest 250;
BA_ "GenSigCycleTime" SG_ 1246 FrontAxle1Load_ISig_2 100;
BA_ "GenSigCycleTimeActive" SG_ 1246 FrontAxle1Load_ISig_2 100;
BA_ "GenSigStartValue" SG_ 1246 FrontAxle1Load_ISig_2 65535;
BA_ "GenSigCycleTime" SG_ 1246 FrontAxle2Load_ISig_2 100;
BA_ "GenSigCycleTimeActive" SG_ 1246 FrontAxle2Load_ISig_2 100;
BA_ "GenSigStartValue" SG_ 1246 FrontAxle2Load_ISig_2 65535;
BA_ "GenSigCycleTime" SG_ 1246 PusherAxleLoad_ISig_2 100;
BA_ "GenSigCycleTimeActive" SG_ 1246 PusherAxleLoad_ISig_2 100;
BA_ "GenSigStartValue" SG_ 1246 PusherAxleLoad_ISig_2 65535;
BA_ "GenSigMaxLatency" SG_ 1246 PusherAxleLoad_ISig_2 250;
BA_ "GenSigCycleTime" SG_ 1246 DriveAxleLoad_ISig_2 100;
BA_ "GenSigCycleTimeActive" SG_ 1246 DriveAxleLoad_ISig_2 100;
BA_ "GenSigStartValue" SG_ 1246 DriveAxleLoad_ISig_2 65535;
BA_ "GenSigMaxLatency" SG_ 1246 DriveAxleLoad_ISig_2 250;
BA_ "GenSigCycleTime" SG_ 746 Pto1ConsentRequest 100;
BA_ "GenSigCycleTimeActive" SG_ 746 Pto1ConsentRequest 100;
BA_ "GenSigStartValue" SG_ 746 Pto1ConsentRequest 3;
BA_ "GenSigMaxLatency" SG_ 746 Pto1ConsentRequest 75;
BA_ "GenSigCycleTime" SG_ 746 CCBSetSpeed 100;
BA_ "GenSigCycleTimeActive" SG_ 746 CCBSetSpeed 100;
BA_ "GenSigStartValue" SG_ 746 CCBSetSpeed 65535;
BA_ "GenSigMaxLatency" SG_ 746 CCBSetSpeed 30;
BA_ "GenSigCycleTime" SG_ 746 SecondThrottle 100;
BA_ "GenSigCycleTimeActive" SG_ 746 SecondThrottle 100;
BA_ "GenSigStartValue" SG_ 746 SecondThrottle 3;
BA_ "GenSigMaxLatency" SG_ 746 SecondThrottle 50;
BA_ "GenSigCycleTime" SG_ 746 CCBTargetSpeedRequest 100;
BA_ "GenSigCycleTimeActive" SG_ 746 CCBTargetSpeedRequest 100;
BA_ "GenSigStartValue" SG_ 746 CCBTargetSpeedRequest 65535;
BA_ "GenSigMaxLatency" SG_ 746 CCBTargetSpeedRequest 50;
BA_ "GenSigCycleTime" SG_ 746 TransferCaseOrSplitboxPTOMode_IS 100;
BA_ "GenSigCycleTimeActive" SG_ 746 TransferCaseOrSplitboxPTOMode_IS 100;
BA_ "GenSigStartValue" SG_ 746 TransferCaseOrSplitboxPTOMode_IS 3;
BA_ "GenSigMaxLatency" SG_ 746 TransferCaseOrSplitboxPTOMode_IS 75;
BA_ "SystemSignalLongSymbol" SG_ 746 TransferCaseOrSplitboxPTOMode_IS "TransferCaseOrSplitboxPTOMode_ISig_2";
BA_ "GenSigCycleTime" SG_ 746 PtosStatus_ISig_2 100;
BA_ "GenSigCycleTimeActive" SG_ 746 PtosStatus_ISig_2 100;
BA_ "GenSigStartValue" SG_ 746 PtosStatus_ISig_2 3;
BA_ "GenSigMaxLatency" SG_ 746 PtosStatus_ISig_2 75;
BA_ "GenSigCycleTime" SG_ 746 ConstructionSwitch_stat 100;
BA_ "GenSigCycleTimeActive" SG_ 746 ConstructionSwitch_stat 100;
BA_ "GenSigStartValue" SG_ 746 ConstructionSwitch_stat 3;
BA_ "GenSigMaxLatency" SG_ 746 ConstructionSwitch_stat 50;
BA_ "GenSigCycleTime" SG_ 746 RegenInhibitVehicleHeight_ISig_2 100;
BA_ "GenSigCycleTimeActive" SG_ 746 RegenInhibitVehicleHeight_ISig_2 100;
BA_ "GenSigStartValue" SG_ 746 RegenInhibitVehicleHeight_ISig_2 3;
BA_ "GenSigMaxLatency" SG_ 746 RegenInhibitVehicleHeight_ISig_2 50;
BA_ "GenSigCycleTime" SG_ 746 PtoRequest 100;
BA_ "GenSigCycleTimeActive" SG_ 746 PtoRequest 100;
BA_ "GenSigStartValue" SG_ 746 PtoRequest 3;
BA_ "GenSigMaxLatency" SG_ 746 PtoRequest 75;
BA_ "GenSigCycleTime" SG_ 746 Pto2Status_ISig_2 100;
BA_ "GenSigCycleTimeActive" SG_ 746 Pto2Status_ISig_2 100;
BA_ "GenSigStartValue" SG_ 746 Pto2Status_ISig_2 3;
BA_ "GenSigMaxLatency" SG_ 746 Pto2Status_ISig_2 75;
BA_ "GenSigCycleTime" SG_ 746 TrailerConnected_ISig_2 100;
BA_ "GenSigCycleTimeActive" SG_ 746 TrailerConnected_ISig_2 100;
BA_ "GenSigStartValue" SG_ 746 TrailerConnected_ISig_2 3;
BA_ "GenSigMaxLatency" SG_ 746 TrailerConnected_ISig_2 50;
BA_ "GenSigCycleTime" SG_ 746 WarmUp_Request 100;
BA_ "GenSigCycleTimeActive" SG_ 746 WarmUp_Request 100;
BA_ "GenSigStartValue" SG_ 746 WarmUp_Request 3;
BA_ "GenSigMaxLatency" SG_ 746 WarmUp_Request 50;
BA_ "GenSigCycleTime" SG_ 746 ParkBrakeReleasePossible_stat_IS 100;
BA_ "GenSigCycleTimeActive" SG_ 746 ParkBrakeReleasePossible_stat_IS 100;
BA_ "GenSigStartValue" SG_ 746 ParkBrakeReleasePossible_stat_IS 3;
BA_ "GenSigMaxLatency" SG_ 746 ParkBrakeReleasePossible_stat_IS 50;
BA_ "SystemSignalLongSymbol" SG_ 746 ParkBrakeReleasePossible_stat_IS "ParkBrakeReleasePossible_stat_ISig_2";
BA_ "GenSigCycleTime" SG_ 746 AC_CompressorClutchCmd_ISig_2 100;
BA_ "GenSigCycleTimeActive" SG_ 746 AC_CompressorClutchCmd_ISig_2 100;
BA_ "GenSigStartValue" SG_ 746 AC_CompressorClutchCmd_ISig_2 3;
BA_ "GenSigMaxLatency" SG_ 746 AC_CompressorClutchCmd_ISig_2 50;
BA_ "GenSigCycleTime" SG_ 746 CCSetSpeed_ISig_2 100;
BA_ "GenSigCycleTimeActive" SG_ 746 CCSetSpeed_ISig_2 100;
BA_ "GenSigStartValue" SG_ 746 CCSetSpeed_ISig_2 65535;
BA_ "GenSigMaxLatency" SG_ 746 CCSetSpeed_ISig_2 35;
BA_ "GenSigCycleTime" SG_ 746 ESCReqEMS_CtrlTrimReq 100;
BA_ "GenSigCycleTimeActive" SG_ 746 ESCReqEMS_CtrlTrimReq 100;
BA_ "GenSigStartValue" SG_ 746 ESCReqEMS_CtrlTrimReq 7;
BA_ "GenSigMaxLatency" SG_ 746 ESCReqEMS_CtrlTrimReq 50;
BA_ "SeToolAncestorID_SIGNAL" SG_ 746 ESCReqEMS_CtrlTrimReq "x0000001D042A710B";
BA_ "SeToolItemID_SIGNAL" SG_ 746 ESCReqEMS_CtrlTrimReq "x0000001D042A710B";
BA_ "SeToolName_SIGNAL" SG_ 746 ESCReqEMS_CtrlTrimReq "CtrlTrimReq";
BA_ "SeToolOwnerSigGroupID_SIGNAL" SG_ 746 ESCReqEMS_CtrlTrimReq "x0000001D043D5DDC";
BA_ "SeToolOwnerSigGroup_SIGNAL" SG_ 746 ESCReqEMS_CtrlTrimReq "ESCReqEMS";
BA_ "SeToolVersion_SIGNAL" SG_ 746 ESCReqEMS_CtrlTrimReq "1";
BA_ "GenSigCycleTime" SG_ 746 ESCReqEMS_CtrlTrimValue 100;
BA_ "GenSigCycleTimeActive" SG_ 746 ESCReqEMS_CtrlTrimValue 100;
BA_ "GenSigStartValue" SG_ 746 ESCReqEMS_CtrlTrimValue 255;
BA_ "GenSigMaxLatency" SG_ 746 ESCReqEMS_CtrlTrimValue 50;
BA_ "SeToolAncestorID_SIGNAL" SG_ 746 ESCReqEMS_CtrlTrimValue "x0000001D042A7114";
BA_ "SeToolItemID_SIGNAL" SG_ 746 ESCReqEMS_CtrlTrimValue "x0000001D042A7114";
BA_ "SeToolName_SIGNAL" SG_ 746 ESCReqEMS_CtrlTrimValue "CtrlTrimValue";
BA_ "SeToolOwnerSigGroupID_SIGNAL" SG_ 746 ESCReqEMS_CtrlTrimValue "x0000001D043D5DDC";
BA_ "SeToolOwnerSigGroup_SIGNAL" SG_ 746 ESCReqEMS_CtrlTrimValue "ESCReqEMS";
BA_ "SeToolVersion_SIGNAL" SG_ 746 ESCReqEMS_CtrlTrimValue "1";
BA_ "GenSigCycleTime" SG_ 746 Pto1Status_ISig_2 100;
BA_ "GenSigCycleTimeActive" SG_ 746 Pto1Status_ISig_2 100;
BA_ "GenSigStartValue" SG_ 746 Pto1Status_ISig_2 3;
BA_ "GenSigMaxLatency" SG_ 746 Pto1Status_ISig_2 75;
BA_ "GenSigCycleTime" SG_ 746 ESCReqEMS_CtrlTrimStat 100;
BA_ "GenSigCycleTimeActive" SG_ 746 ESCReqEMS_CtrlTrimStat 100;
BA_ "GenSigStartValue" SG_ 746 ESCReqEMS_CtrlTrimStat 7;
BA_ "GenSigMaxLatency" SG_ 746 ESCReqEMS_CtrlTrimStat 50;
BA_ "SeToolAncestorID_SIGNAL" SG_ 746 ESCReqEMS_CtrlTrimStat "x0000001D042A710D";
BA_ "SeToolItemID_SIGNAL" SG_ 746 ESCReqEMS_CtrlTrimStat "x0000001D042A710D";
BA_ "SeToolName_SIGNAL" SG_ 746 ESCReqEMS_CtrlTrimStat "CtrlTrimStat";
BA_ "SeToolOwnerSigGroupID_SIGNAL" SG_ 746 ESCReqEMS_CtrlTrimStat "x0000001D043D5DDC";
BA_ "SeToolOwnerSigGroup_SIGNAL" SG_ 746 ESCReqEMS_CtrlTrimStat "ESCReqEMS";
BA_ "SeToolVersion_SIGNAL" SG_ 746 ESCReqEMS_CtrlTrimStat "1";
BA_ "GenSigCycleTime" SG_ 746 XRSLTargetSpeedRequest 100;
BA_ "GenSigCycleTimeActive" SG_ 746 XRSLTargetSpeedRequest 100;
BA_ "GenSigStartValue" SG_ 746 XRSLTargetSpeedRequest 65535;
BA_ "GenSigMaxLatency" SG_ 746 XRSLTargetSpeedRequest 50;
BA_ "GenSigCycleTime" SG_ 746 CtaGcAlternativeGearStarter 100;
BA_ "GenSigCycleTimeActive" SG_ 746 CtaGcAlternativeGearStarter 100;
BA_ "GenSigStartValue" SG_ 746 CtaGcAlternativeGearStarter 3;
BA_ "GenSigMaxLatency" SG_ 746 CtaGcAlternativeGearStarter 50;
BA_ "GenSigCycleTime" SG_ 746 XRSLBTargetSpeedRequest 100;
BA_ "GenSigCycleTimeActive" SG_ 746 XRSLBTargetSpeedRequest 100;
BA_ "GenSigStartValue" SG_ 746 XRSLBTargetSpeedRequest 65535;
BA_ "GenSigMaxLatency" SG_ 746 XRSLBTargetSpeedRequest 150;
BA_ "GenSigCycleTime" SG_ 746 Pto2ConsentRequest 100;
BA_ "GenSigCycleTimeActive" SG_ 746 Pto2ConsentRequest 100;
BA_ "GenSigStartValue" SG_ 746 Pto2ConsentRequest 3;
BA_ "GenSigMaxLatency" SG_ 746 Pto2ConsentRequest 75;
BA_ "GenSigCycleTime" SG_ 746 EngPtoConsumesTorque 100;
BA_ "GenSigCycleTimeActive" SG_ 746 EngPtoConsumesTorque 100;
BA_ "GenSigStartValue" SG_ 746 EngPtoConsumesTorque 3;
BA_ "GenSigMaxLatency" SG_ 746 EngPtoConsumesTorque 50;
BA_ "GenSigCycleTime" SG_ 746 ESCReqEMS_CtrlTrimMode 100;
BA_ "GenSigCycleTimeActive" SG_ 746 ESCReqEMS_CtrlTrimMode 100;
BA_ "GenSigStartValue" SG_ 746 ESCReqEMS_CtrlTrimMode 15;
BA_ "GenSigMaxLatency" SG_ 746 ESCReqEMS_CtrlTrimMode 50;
BA_ "SeToolAncestorID_SIGNAL" SG_ 746 ESCReqEMS_CtrlTrimMode "x0000001D042A710F";
BA_ "SeToolItemID_SIGNAL" SG_ 746 ESCReqEMS_CtrlTrimMode "x0000001D042A710F";
BA_ "SeToolName_SIGNAL" SG_ 746 ESCReqEMS_CtrlTrimMode "CtrlTrimMode";
BA_ "SeToolOwnerSigGroupID_SIGNAL" SG_ 746 ESCReqEMS_CtrlTrimMode "x0000001D043D5DDC";
BA_ "SeToolOwnerSigGroup_SIGNAL" SG_ 746 ESCReqEMS_CtrlTrimMode "ESCReqEMS";
BA_ "SeToolVersion_SIGNAL" SG_ 746 ESCReqEMS_CtrlTrimMode "1";
BA_ "GenSigCycleTime" SG_ 746 TrailerABSStatus_ISig_2 100;
BA_ "GenSigCycleTimeActive" SG_ 746 TrailerABSStatus_ISig_2 100;
BA_ "GenSigStartValue" SG_ 746 TrailerABSStatus_ISig_2 3;
BA_ "GenSigMaxLatency" SG_ 746 TrailerABSStatus_ISig_2 50;
BA_ "GenSigCycleTime" SG_ 746 CtaGcInhibitGearEngaged 100;
BA_ "GenSigCycleTimeActive" SG_ 746 CtaGcInhibitGearEngaged 100;
BA_ "GenSigStartValue" SG_ 746 CtaGcInhibitGearEngaged 3;
BA_ "GenSigMaxLatency" SG_ 746 CtaGcInhibitGearEngaged 50;
BA_ "GenSigCycleTime" SG_ 746 RearEndPositionStatus_ISig_2 100;
BA_ "GenSigCycleTimeActive" SG_ 746 RearEndPositionStatus_ISig_2 100;
BA_ "GenSigStartValue" SG_ 746 RearEndPositionStatus_ISig_2 7;
BA_ "GenSigMaxLatency" SG_ 746 RearEndPositionStatus_ISig_2 50;
BA_ "GenSigCycleTime" SG_ 746 StoreIdleValue_ISig_2 100;
BA_ "GenSigCycleTimeActive" SG_ 746 StoreIdleValue_ISig_2 100;
BA_ "GenSigStartValue" SG_ 746 StoreIdleValue_ISig_2 3;
BA_ "GenSigCycleTime" SG_ 746 CtaGcReverseInhibit 100;
BA_ "GenSigCycleTimeActive" SG_ 746 CtaGcReverseInhibit 100;
BA_ "GenSigStartValue" SG_ 746 CtaGcReverseInhibit 3;
BA_ "GenSigMaxLatency" SG_ 746 CtaGcReverseInhibit 50;
BA_ "GenSigCycleTime" SG_ 746 CCTargetSpeedRequest 100;
BA_ "GenSigCycleTimeActive" SG_ 746 CCTargetSpeedRequest 100;
BA_ "GenSigStartValue" SG_ 746 CCTargetSpeedRequest 65535;
BA_ "GenSigMaxLatency" SG_ 746 CCTargetSpeedRequest 50;
BA_ "GenSigCycleTime" SG_ 746 AirCompressorStatus_ISig_2 100;
BA_ "GenSigCycleTimeActive" SG_ 746 AirCompressorStatus_ISig_2 100;
BA_ "GenSigStartValue" SG_ 746 AirCompressorStatus_ISig_2 3;
BA_ "GenSigMaxLatency" SG_ 746 AirCompressorStatus_ISig_2 50;
BA_ "GenSigCycleTime" SG_ 391 ReqdLongDist_AllwdBndUppr 100;
BA_ "GenSigCycleTimeActive" SG_ 391 ReqdLongDist_AllwdBndUppr 100;
BA_ "GenSigStartValue" SG_ 391 ReqdLongDist_AllwdBndUppr 65535;
BA_ "GenSigCycleTime" SG_ 391 ParkingBrake_stat_ISig_2 100;
BA_ "GenSigCycleTimeActive" SG_ 391 ParkingBrake_stat_ISig_2 100;
BA_ "GenSigStartValue" SG_ 391 ParkingBrake_stat_ISig_2 3;
BA_ "GenSigMaxLatency" SG_ 391 ParkingBrake_stat_ISig_2 25;
BA_ "GenSigCycleTime" SG_ 391 ReqdLongSpd_CRC 100;
BA_ "GenSigCycleTimeActive" SG_ 391 ReqdLongSpd_CRC 100;
BA_ "GenSigStartValue" SG_ 391 ReqdLongSpd_CRC 255;
BA_ "E2EDataId" SG_ 391 ReqdLongSpd_CRC 153;
BA_ "E2EDataLength" SG_ 391 ReqdLongSpd_CRC 64;
BA_ "E2EProfile" SG_ 391 ReqdLongSpd_CRC "P01";
BA_ "GenSigCycleTime" SG_ 391 RequestedUpshiftDownshiftSteps 100;
BA_ "GenSigCycleTimeActive" SG_ 391 RequestedUpshiftDownshiftSteps 100;
BA_ "GenSigStartValue" SG_ 391 RequestedUpshiftDownshiftSteps 7;
BA_ "GenSigMaxLatency" SG_ 391 RequestedUpshiftDownshiftSteps 20;
BA_ "GenSigCycleTime" SG_ 391 LiftAxle1PositionStatus_ISig_2 100;
BA_ "GenSigCycleTimeActive" SG_ 391 LiftAxle1PositionStatus_ISig_2 100;
BA_ "GenSigStartValue" SG_ 391 LiftAxle1PositionStatus_ISig_2 7;
BA_ "GenSigMaxLatency" SG_ 391 LiftAxle1PositionStatus_ISig_2 25;
BA_ "GenSigCycleTime" SG_ 391 EngineSystemPowerDownRequest 100;
BA_ "GenSigCycleTimeActive" SG_ 391 EngineSystemPowerDownRequest 100;
BA_ "GenSigStartValue" SG_ 391 EngineSystemPowerDownRequest 3;
BA_ "GenSigMaxLatency" SG_ 391 EngineSystemPowerDownRequest 20;
BA_ "GenSigCycleTime" SG_ 391 LimpHomeSwitch_stat 100;
BA_ "GenSigCycleTimeActive" SG_ 391 LimpHomeSwitch_stat 100;
BA_ "GenSigStartValue" SG_ 391 LimpHomeSwitch_stat 3;
BA_ "GenSigMaxLatency" SG_ 391 LimpHomeSwitch_stat 20;
BA_ "GenSigCycleTime" SG_ 391 ReqdLongSpd_SqC 100;
BA_ "GenSigCycleTimeActive" SG_ 391 ReqdLongSpd_SqC 100;
BA_ "GenSigStartValue" SG_ 391 ReqdLongSpd_SqC 14;
BA_ "GenSigCycleTime" SG_ 391 ReqdLongDist_Distance 100;
BA_ "GenSigCycleTimeActive" SG_ 391 ReqdLongDist_Distance 100;
BA_ "GenSigStartValue" SG_ 391 ReqdLongDist_Distance 65535;
BA_ "GenSigCycleTime" SG_ 391 EconomyPowerSwitch_stat 100;
BA_ "GenSigCycleTimeActive" SG_ 391 EconomyPowerSwitch_stat 100;
BA_ "GenSigStartValue" SG_ 391 EconomyPowerSwitch_stat 3;
BA_ "GenSigMaxLatency" SG_ 391 EconomyPowerSwitch_stat 20;
BA_ "GenSigCycleTime" SG_ 391 AcceleratorPedalPositionBackup 100;
BA_ "GenSigCycleTimeActive" SG_ 391 AcceleratorPedalPositionBackup 100;
BA_ "GenSigStartValue" SG_ 391 AcceleratorPedalPositionBackup 255;
BA_ "GenSigCycleTime" SG_ 391 UpShiftRequest 100;
BA_ "GenSigCycleTimeActive" SG_ 391 UpShiftRequest 100;
BA_ "GenSigStartValue" SG_ 391 UpShiftRequest 3;
BA_ "GenSigMaxLatency" SG_ 391 UpShiftRequest 20;
BA_ "GenSigCycleTime" SG_ 391 ACCForwardVehicleDistance 100;
BA_ "GenSigCycleTimeActive" SG_ 391 ACCForwardVehicleDistance 100;
BA_ "GenSigStartValue" SG_ 391 ACCForwardVehicleDistance 255;
BA_ "GenSigMaxLatency" SG_ 391 ACCForwardVehicleDistance 20;
BA_ "GenSigCycleTime" SG_ 391 EngineStopRequest 100;
BA_ "GenSigCycleTimeActive" SG_ 391 EngineStopRequest 100;
BA_ "GenSigStartValue" SG_ 391 EngineStopRequest 3;
BA_ "GenSigMaxLatency" SG_ 391 EngineStopRequest 20;
BA_ "GenSigCycleTime" SG_ 391 EngineOperationCtrl 100;
BA_ "GenSigCycleTimeActive" SG_ 391 EngineOperationCtrl 100;
BA_ "GenSigStartValue" SG_ 391 EngineOperationCtrl 7;
BA_ "GenSigCycleTime" SG_ 391 DownShiftRequest 100;
BA_ "GenSigCycleTimeActive" SG_ 391 DownShiftRequest 100;
BA_ "GenSigStartValue" SG_ 391 DownShiftRequest 3;
BA_ "GenSigMaxLatency" SG_ 391 DownShiftRequest 20;
BA_ "GenSigCycleTime" SG_ 391 CM_DisengageDrivelineRequest 100;
BA_ "GenSigCycleTimeActive" SG_ 391 CM_DisengageDrivelineRequest 100;
BA_ "GenSigStartValue" SG_ 391 CM_DisengageDrivelineRequest 3;
BA_ "GenSigMaxLatency" SG_ 391 CM_DisengageDrivelineRequest 20;
BA_ "GenSigCycleTime" SG_ 391 ReqdLongAccel_SqC 100;
BA_ "GenSigCycleTimeActive" SG_ 391 ReqdLongAccel_SqC 100;
BA_ "GenSigStartValue" SG_ 391 ReqdLongAccel_SqC 14;
BA_ "GenSigCycleTime" SG_ 391 ReqdLongAccel_CRC 100;
BA_ "GenSigCycleTimeActive" SG_ 391 ReqdLongAccel_CRC 100;
BA_ "GenSigStartValue" SG_ 391 ReqdLongAccel_CRC 255;
BA_ "E2EDataId" SG_ 391 ReqdLongAccel_CRC 150;
BA_ "E2EDataLength" SG_ 391 ReqdLongAccel_CRC 32;
BA_ "E2EProfile" SG_ 391 ReqdLongAccel_CRC "P01";
BA_ "GenSigCycleTime" SG_ 391 TransmSystemPowerDown_rqst 100;
BA_ "GenSigCycleTimeActive" SG_ 391 TransmSystemPowerDown_rqst 100;
BA_ "GenSigStartValue" SG_ 391 TransmSystemPowerDown_rqst 3;
BA_ "GenSigMaxLatency" SG_ 391 TransmSystemPowerDown_rqst 20;
BA_ "GenSigCycleTime" SG_ 391 ReqdLongDist_CRC 100;
BA_ "GenSigCycleTimeActive" SG_ 391 ReqdLongDist_CRC 100;
BA_ "GenSigStartValue" SG_ 391 ReqdLongDist_CRC 255;
BA_ "E2EDataId" SG_ 391 ReqdLongDist_CRC 154;
BA_ "E2EDataLength" SG_ 391 ReqdLongDist_CRC 64;
BA_ "E2EProfile" SG_ 391 ReqdLongDist_CRC "P01";
BA_ "GenSigCycleTime" SG_ 391 ACC_Status_ISig_2 100;
BA_ "GenSigCycleTimeActive" SG_ 391 ACC_Status_ISig_2 100;
BA_ "GenSigStartValue" SG_ 391 ACC_Status_ISig_2 7;
BA_ "GenSigMaxLatency" SG_ 391 ACC_Status_ISig_2 20;
BA_ "GenSigCycleTime" SG_ 391 ReqdLongSpd_AllwdBndUppr 100;
BA_ "GenSigCycleTimeActive" SG_ 391 ReqdLongSpd_AllwdBndUppr 100;
BA_ "GenSigStartValue" SG_ 391 ReqdLongSpd_AllwdBndUppr 65535;
BA_ "GenSigCycleTime" SG_ 391 XARDACU_AccelDemand 100;
BA_ "GenSigCycleTimeActive" SG_ 391 XARDACU_AccelDemand 100;
BA_ "GenSigStartValue" SG_ 391 XARDACU_AccelDemand 65535;
BA_ "GenSigMaxLatency" SG_ 391 XARDACU_AccelDemand 40;
BA_ "SeToolAncestorID_SIGNAL" SG_ 391 XARDACU_AccelDemand "x0000001D04254042";
BA_ "SeToolItemID_SIGNAL" SG_ 391 XARDACU_AccelDemand "x0000001D04254042";
BA_ "SeToolName_SIGNAL" SG_ 391 XARDACU_AccelDemand "AccelDemand";
BA_ "SeToolOwnerSigGroupID_SIGNAL" SG_ 391 XARDACU_AccelDemand "x0000001D043FB722";
BA_ "SeToolOwnerSigGroup_SIGNAL" SG_ 391 XARDACU_AccelDemand "XARDACU";
BA_ "SeToolVersion_SIGNAL" SG_ 391 XARDACU_AccelDemand "1";
BA_ "GenSigCycleTime" SG_ 391 SteeringValvePositionSetPoint 100;
BA_ "GenSigCycleTimeActive" SG_ 391 SteeringValvePositionSetPoint 100;
BA_ "GenSigStartValue" SG_ 391 SteeringValvePositionSetPoint 255;
BA_ "GenSigMaxLatency" SG_ 391 SteeringValvePositionSetPoint 20;
BA_ "GenSigCycleTime" SG_ 391 ParkBrakeActuationStatus_ISig_2 100;
BA_ "GenSigCycleTimeActive" SG_ 391 ParkBrakeActuationStatus_ISig_2 100;
BA_ "GenSigStartValue" SG_ 391 ParkBrakeActuationStatus_ISig_2 7;
BA_ "GenSigCycleTime" SG_ 391 GearLeverPosition_ISig_2 100;
BA_ "GenSigCycleTimeActive" SG_ 391 GearLeverPosition_ISig_2 100;
BA_ "GenSigStartValue" SG_ 391 GearLeverPosition_ISig_2 15;
BA_ "GenSigMaxLatency" SG_ 391 GearLeverPosition_ISig_2 20;
BA_ "GenSigCycleTime" SG_ 391 EngineCrankRequest 100;
BA_ "GenSigCycleTimeActive" SG_ 391 EngineCrankRequest 100;
BA_ "GenSigStartValue" SG_ 391 EngineCrankRequest 3;
BA_ "GenSigMaxLatency" SG_ 391 EngineCrankRequest 20;
BA_ "GenSigCycleTime" SG_ 391 RequestForHighestGearRatio 100;
BA_ "GenSigCycleTimeActive" SG_ 391 RequestForHighestGearRatio 100;
BA_ "GenSigStartValue" SG_ 391 RequestForHighestGearRatio 3;
BA_ "GenSigMaxLatency" SG_ 391 RequestForHighestGearRatio 20;
BA_ "GenSigCycleTime" SG_ 391 XARDACU_ControlMode 100;
BA_ "GenSigCycleTimeActive" SG_ 391 XARDACU_ControlMode 100;
BA_ "GenSigStartValue" SG_ 391 XARDACU_ControlMode 3;
BA_ "GenSigMaxLatency" SG_ 391 XARDACU_ControlMode 40;
BA_ "SeToolAncestorID_SIGNAL" SG_ 391 XARDACU_ControlMode "x0000001D0425403E";
BA_ "SeToolItemID_SIGNAL" SG_ 391 XARDACU_ControlMode "x0000001D0425403E";
BA_ "SeToolName_SIGNAL" SG_ 391 XARDACU_ControlMode "ControlMode";
BA_ "SeToolOwnerSigGroupID_SIGNAL" SG_ 391 XARDACU_ControlMode "x0000001D043FB722";
BA_ "SeToolOwnerSigGroup_SIGNAL" SG_ 391 XARDACU_ControlMode "XARDACU";
BA_ "SeToolVersion_SIGNAL" SG_ 391 XARDACU_ControlMode "1";
BA_ "GenSigCycleTime" SG_ 391 EnginePreheat_rqst 100;
BA_ "GenSigCycleTimeActive" SG_ 391 EnginePreheat_rqst 100;
BA_ "GenSigStartValue" SG_ 391 EnginePreheat_rqst 3;
BA_ "GenSigMaxLatency" SG_ 391 EnginePreheat_rqst 20;
BA_ "GenSigCycleTime" SG_ 391 ReqdLongAccel_CtrlMode 100;
BA_ "GenSigCycleTimeActive" SG_ 391 ReqdLongAccel_CtrlMode 100;
BA_ "GenSigStartValue" SG_ 391 ReqdLongAccel_CtrlMode 3;
BA_ "GenSigCycleTime" SG_ 391 ReqdLongDist_AllwdBndLowr 100;
BA_ "GenSigCycleTimeActive" SG_ 391 ReqdLongDist_AllwdBndLowr 100;
BA_ "GenSigStartValue" SG_ 391 ReqdLongDist_AllwdBndLowr 65535;
BA_ "GenSigCycleTime" SG_ 391 ReqdLongSpd_Spd 100;
BA_ "GenSigCycleTimeActive" SG_ 391 ReqdLongSpd_Spd 100;
BA_ "GenSigStartValue" SG_ 391 ReqdLongSpd_Spd 65535;
BA_ "GenSigCycleTime" SG_ 391 ReqdLongSpd_AllwdBndLowr 100;
BA_ "GenSigCycleTimeActive" SG_ 391 ReqdLongSpd_AllwdBndLowr 100;
BA_ "GenSigStartValue" SG_ 391 ReqdLongSpd_AllwdBndLowr 65535;
BA_ "GenSigCycleTime" SG_ 391 ACCForwardVehicleSpeed 100;
BA_ "GenSigCycleTimeActive" SG_ 391 ACCForwardVehicleSpeed 100;
BA_ "GenSigStartValue" SG_ 391 ACCForwardVehicleSpeed 255;
BA_ "GenSigMaxLatency" SG_ 391 ACCForwardVehicleSpeed 20;
BA_ "GenSigCycleTime" SG_ 391 ReqdLongDist_SqC 100;
BA_ "GenSigCycleTimeActive" SG_ 391 ReqdLongDist_SqC 100;
BA_ "GenSigStartValue" SG_ 391 ReqdLongDist_SqC 14;
BA_ "GenSigCycleTime" SG_ 391 ReqdLongAccel_Accel 100;
BA_ "GenSigCycleTimeActive" SG_ 391 ReqdLongAccel_Accel 100;
BA_ "GenSigStartValue" SG_ 391 ReqdLongAccel_Accel 65535;
BA_ "GenSigCycleTime" SG_ 1791 VCMNetVer_C02_Minor 100;
BA_ "GenSigCycleTimeActive" SG_ 1791 VCMNetVer_C02_Minor 100;
BA_ "GenSigStartValue" SG_ 1791 VCMNetVer_C02_Minor 3;
BA_ "GenSigCycleTime" SG_ 1791 VCMNetVer_C02_Major 100;
BA_ "GenSigCycleTimeActive" SG_ 1791 VCMNetVer_C02_Major 100;
BA_ "GenSigStartValue" SG_ 1791 VCMNetVer_C02_Major 2;
BA_ "GenSigCycleTime" SG_ 1791 VCMNetVer_C02_NetID 100;
BA_ "GenSigCycleTimeActive" SG_ 1791 VCMNetVer_C02_NetID 100;
BA_ "GenSigStartValue" SG_ 1791 VCMNetVer_C02_NetID 2;
BA_ "GenSigCycleTime" SG_ 1791 VCMNetVer_C02_Dirty 100;
BA_ "GenSigCycleTimeActive" SG_ 1791 VCMNetVer_C02_Dirty 100;
BA_ "GenSigCycleTime" SG_ 1791 VCMNetVer_C02_Patch 100;
BA_ "GenSigCycleTimeActive" SG_ 1791 VCMNetVer_C02_Patch 100;
BA_REL_ "GenSigFirstTimeoutTime" BU_SG_REL_ TCM SG_ 298 ReqTSC_Tq 3000;
BA_REL_ "GenSigTimeoutTime" BU_SG_REL_ TCM SG_ 298 ReqTSC_Tq 60;
BA_REL_ "GenSigFirstTimeoutTime" BU_SG_REL_ ECM SG_ 298 ReqTSC_Tq 3000;
BA_REL_ "GenSigTimeoutTime" BU_SG_REL_ ECM SG_ 298 ReqTSC_Tq 60;
BA_REL_ "GenSigFirstTimeoutTime" BU_SG_REL_ ECM SG_ 298 ReqTSC_CtrlMode 3000;
BA_REL_ "GenSigTimeoutTime" BU_SG_REL_ ECM SG_ 298 ReqTSC_CtrlMode 60;
BA_REL_ "GenSigFirstTimeoutTime" BU_SG_REL_ TCM SG_ 298 ReqTSC_CtrlMode 3000;
BA_REL_ "GenSigTimeoutTime" BU_SG_REL_ TCM SG_ 298 ReqTSC_CtrlMode 60;
BA_REL_ "GenSigFirstTimeoutTime" BU_SG_REL_ ECM SG_ 298 ReqTSC_CRC 3000;
BA_REL_ "GenSigTimeoutTime" BU_SG_REL_ ECM SG_ 298 ReqTSC_CRC 60;
BA_REL_ "GenSigFirstTimeoutTime" BU_SG_REL_ TCM SG_ 298 ReqTSC_CRC 3000;
BA_REL_ "GenSigTimeoutTime" BU_SG_REL_ TCM SG_ 298 ReqTSC_CRC 60;
BA_REL_ "GenSigFirstTimeoutTime" BU_SG_REL_ TCM SG_ 298 ReqTSC_SqC 3000;
BA_REL_ "GenSigTimeoutTime" BU_SG_REL_ TCM SG_ 298 ReqTSC_SqC 60;
BA_REL_ "GenSigFirstTimeoutTime" BU_SG_REL_ ECM SG_ 298 ReqTSC_SqC 3000;
BA_REL_ "GenSigTimeoutTime" BU_SG_REL_ ECM SG_ 298 ReqTSC_SqC 60;
BA_REL_ "GenSigFirstTimeoutTime" BU_SG_REL_ ECM SG_ 298 ReqTSC_Spd 3000;
BA_REL_ "GenSigTimeoutTime" BU_SG_REL_ ECM SG_ 298 ReqTSC_Spd 60;
BA_REL_ "GenSigFirstTimeoutTime" BU_SG_REL_ TCM SG_ 298 ReqTSC_Spd 3000;
BA_REL_ "GenSigTimeoutTime" BU_SG_REL_ TCM SG_ 298 ReqTSC_Spd 60;
BA_REL_ "GenSigFirstTimeoutTime" BU_SG_REL_ ECM SG_ 568 EngSystPwrDwn_Rqst 3000;
BA_REL_ "GenSigTimeoutTime" BU_SG_REL_ ECM SG_ 568 EngSystPwrDwn_Rqst 120;
BA_REL_ "GenSigFirstTimeoutTime" BU_SG_REL_ TCM SG_ 568 TrnsmSystPwrDwn_SqC 3000;
BA_REL_ "GenSigTimeoutTime" BU_SG_REL_ TCM SG_ 568 TrnsmSystPwrDwn_SqC 120;
BA_REL_ "GenSigFirstTimeoutTime" BU_SG_REL_ ECM SG_ 568 EngSystPwrDwn_CRC 3000;
BA_REL_ "GenSigTimeoutTime" BU_SG_REL_ ECM SG_ 568 EngSystPwrDwn_CRC 120;
BA_REL_ "GenSigFirstTimeoutTime" BU_SG_REL_ ECM SG_ 568 EngCrnk_Rqst 3000;
BA_REL_ "GenSigTimeoutTime" BU_SG_REL_ ECM SG_ 568 EngCrnk_Rqst 120;
BA_REL_ "GenSigFirstTimeoutTime" BU_SG_REL_ ECM SG_ 568 SecuredNeutralPosition_ISig_2 3000;
BA_REL_ "GenSigTimeoutTime" BU_SG_REL_ ECM SG_ 568 SecuredNeutralPosition_ISig_2 120;
BA_REL_ "GenSigFirstTimeoutTime" BU_SG_REL_ ECM SG_ 568 TransmLowRangeSenseSwitch_ISig_2 3000;
BA_REL_ "GenSigTimeoutTime" BU_SG_REL_ ECM SG_ 568 TransmLowRangeSenseSwitch_ISig_2 120;
BA_REL_ "GenSigFirstTimeoutTime" BU_SG_REL_ TCM SG_ 568 UpDownShiftRqst_CRC 3000;
BA_REL_ "GenSigTimeoutTime" BU_SG_REL_ TCM SG_ 568 UpDownShiftRqst_CRC 120;
BA_REL_ "GenSigFirstTimeoutTime" BU_SG_REL_ TCM SG_ 568 TrnsmSystPwrDwn_Rqst 3000;
BA_REL_ "GenSigTimeoutTime" BU_SG_REL_ TCM SG_ 568 TrnsmSystPwrDwn_Rqst 120;
BA_REL_ "GenSigFirstTimeoutTime" BU_SG_REL_ TCM SG_ 568 GearLeverPosition2_SqC 3000;
BA_REL_ "GenSigTimeoutTime" BU_SG_REL_ TCM SG_ 568 GearLeverPosition2_SqC 120;
BA_REL_ "GenSigFirstTimeoutTime" BU_SG_REL_ TCM SG_ 568 FrontAxleInBumperRange_ISig_2 3000;
BA_REL_ "GenSigTimeoutTime" BU_SG_REL_ TCM SG_ 568 FrontAxleInBumperRange_ISig_2 120;
BA_REL_ "GenSigFirstTimeoutTime" BU_SG_REL_ ECM SG_ 568 RollerBenchModeRequest_ISig_2 3000;
BA_REL_ "GenSigTimeoutTime" BU_SG_REL_ ECM SG_ 568 RollerBenchModeRequest_ISig_2 120;
BA_REL_ "GenSigFirstTimeoutTime" BU_SG_REL_ TCM SG_ 568 EcnmyPwrSwt_Sts 3000;
BA_REL_ "GenSigTimeoutTime" BU_SG_REL_ TCM SG_ 568 EcnmyPwrSwt_Sts 120;
BA_REL_ "GenSigFirstTimeoutTime" BU_SG_REL_ TCM SG_ 568 RearAxleInBumperRange_ISig_2 3000;
BA_REL_ "GenSigTimeoutTime" BU_SG_REL_ TCM SG_ 568 RearAxleInBumperRange_ISig_2 120;
BA_REL_ "GenSigFirstTimeoutTime" BU_SG_REL_ ECM SG_ 568 EngCrnk_SqC 3000;
BA_REL_ "GenSigTimeoutTime" BU_SG_REL_ ECM SG_ 568 EngCrnk_SqC 120;
BA_REL_ "GenSigFirstTimeoutTime" BU_SG_REL_ TCM SG_ 568 EcnmyPwrSwt_CRC 3000;
BA_REL_ "GenSigTimeoutTime" BU_SG_REL_ TCM SG_ 568 EcnmyPwrSwt_CRC 120;
BA_REL_ "GenSigFirstTimeoutTime" BU_SG_REL_ ECM SG_ 568 EngCrnk_CRC 3000;
BA_REL_ "GenSigTimeoutTime" BU_SG_REL_ ECM SG_ 568 EngCrnk_CRC 120;
BA_REL_ "GenSigFirstTimeoutTime" BU_SG_REL_ ECM SG_ 568 TractionControlDriverRqst_ISig_2 3000;
BA_REL_ "GenSigTimeoutTime" BU_SG_REL_ ECM SG_ 568 TractionControlDriverRqst_ISig_2 120;
BA_REL_ "GenSigFirstTimeoutTime" BU_SG_REL_ TCM SG_ 568 EcnmyPwrSwt_SqC 3000;
BA_REL_ "GenSigTimeoutTime" BU_SG_REL_ TCM SG_ 568 EcnmyPwrSwt_SqC 120;
BA_REL_ "GenSigFirstTimeoutTime" BU_SG_REL_ TCM SG_ 568 DriveModeSwitchStat_CRC 3000;
BA_REL_ "GenSigTimeoutTime" BU_SG_REL_ TCM SG_ 568 DriveModeSwitchStat_CRC 120;
BA_REL_ "GenSigFirstTimeoutTime" BU_SG_REL_ ECM SG_ 568 TransmissionNeutralSwitch 3000;
BA_REL_ "GenSigTimeoutTime" BU_SG_REL_ ECM SG_ 568 TransmissionNeutralSwitch 120;
BA_REL_ "GenSigFirstTimeoutTime" BU_SG_REL_ ECM SG_ 568 ReverseGearEngaged_ISig_2 3000;
BA_REL_ "GenSigTimeoutTime" BU_SG_REL_ ECM SG_ 568 ReverseGearEngaged_ISig_2 120;
BA_REL_ "GenSigFirstTimeoutTime" BU_SG_REL_ TCM SG_ 568 GearLeverPosition2_Rqst 3000;
BA_REL_ "GenSigTimeoutTime" BU_SG_REL_ TCM SG_ 568 GearLeverPosition2_Rqst 120;
BA_REL_ "GenSigFirstTimeoutTime" BU_SG_REL_ ECM SG_ 568 EngSystPwrDwn_SqC 3000;
BA_REL_ "GenSigTimeoutTime" BU_SG_REL_ ECM SG_ 568 EngSystPwrDwn_SqC 120;
BA_REL_ "GenSigFirstTimeoutTime" BU_SG_REL_ TCM SG_ 568 UpDownShiftRqst_Rqst 3000;
BA_REL_ "GenSigTimeoutTime" BU_SG_REL_ TCM SG_ 568 UpDownShiftRqst_Rqst 120;
BA_REL_ "GenSigFirstTimeoutTime" BU_SG_REL_ TCM SG_ 568 LevelControlInformation_ISig_2 3000;
BA_REL_ "GenSigTimeoutTime" BU_SG_REL_ TCM SG_ 568 LevelControlInformation_ISig_2 120;
BA_REL_ "GenSigFirstTimeoutTime" BU_SG_REL_ TCM SG_ 568 TrnsmSystPwrDwn_CRC 3000;
BA_REL_ "GenSigTimeoutTime" BU_SG_REL_ TCM SG_ 568 TrnsmSystPwrDwn_CRC 120;
BA_REL_ "GenSigFirstTimeoutTime" BU_SG_REL_ TCM SG_ 568 DriveModeSwitchStat_SqC 3000;
BA_REL_ "GenSigTimeoutTime" BU_SG_REL_ TCM SG_ 568 DriveModeSwitchStat_SqC 120;
BA_REL_ "GenSigFirstTimeoutTime" BU_SG_REL_ TCM SG_ 568 GearLeverPosition2_CRC 3000;
BA_REL_ "GenSigTimeoutTime" BU_SG_REL_ TCM SG_ 568 GearLeverPosition2_CRC 120;
BA_REL_ "GenSigFirstTimeoutTime" BU_SG_REL_ TCM SG_ 568 DriveModeSwitchStat_Rqst 3000;
BA_REL_ "GenSigTimeoutTime" BU_SG_REL_ TCM SG_ 568 DriveModeSwitchStat_Rqst 120;
BA_REL_ "GenSigFirstTimeoutTime" BU_SG_REL_ TCM SG_ 568 UpDownShiftRqst_SqC 3000;
BA_REL_ "GenSigTimeoutTime" BU_SG_REL_ TCM SG_ 568 UpDownShiftRqst_SqC 120;
BA_REL_ "GenSigFirstTimeoutTime" BU_SG_REL_ ECM SG_ 1563 MIStatusExtVMCU 24000;
BA_REL_ "GenSigTimeoutTime" BU_SG_REL_ ECM SG_ 1563 MIStatusExtVMCU 6000;
BA_REL_ "GenSigFirstTimeoutTime" BU_SG_REL_ ECM SG_ 1563 MIStatusVMCU 24000;
BA_REL_ "GenSigTimeoutTime" BU_SG_REL_ ECM SG_ 1563 MIStatusVMCU 6000;
BA_REL_ "GenSigFirstTimeoutTime" BU_SG_REL_ ECM SG_ 1563 MIDistinctWarningExtVMCU 24000;
BA_REL_ "GenSigTimeoutTime" BU_SG_REL_ ECM SG_ 1563 MIDistinctWarningExtVMCU 6000;
BA_REL_ "GenSigFirstTimeoutTime" BU_SG_REL_ ECM SG_ 1563 MIDistinctWarningVMCU 24000;
BA_REL_ "GenSigTimeoutTime" BU_SG_REL_ ECM SG_ 1563 MIDistinctWarningVMCU 6000;
BA_REL_ "GenSigFirstTimeoutTime" BU_SG_REL_ TCM SG_ 1309 HillDataPkgTGW 12000;
BA_REL_ "GenSigTimeoutTime" BU_SG_REL_ TCM SG_ 1309 HillDataPkgTGW 3000;
BA_REL_ "GenSigFirstTimeoutTime" BU_SG_REL_ TCM SG_ 1308 HillDataCtrlTGW_AckCnt 12000;
BA_REL_ "GenSigTimeoutTime" BU_SG_REL_ TCM SG_ 1308 HillDataCtrlTGW_AckCnt 3000;
BA_REL_ "GenSigFirstTimeoutTime" BU_SG_REL_ ECM SG_ 1308 DPF_ManualRegenerateRequest_ISig 12000;
BA_REL_ "GenSigTimeoutTime" BU_SG_REL_ ECM SG_ 1308 DPF_ManualRegenerateRequest_ISig 3000;
BA_REL_ "GenSigFirstTimeoutTime" BU_SG_REL_ TCM SG_ 1308 KFactor 12000;
BA_REL_ "GenSigTimeoutTime" BU_SG_REL_ TCM SG_ 1308 KFactor 3000;
BA_REL_ "GenSigFirstTimeoutTime" BU_SG_REL_ ECM SG_ 1308 KFactor 12000;
BA_REL_ "GenSigTimeoutTime" BU_SG_REL_ ECM SG_ 1308 KFactor 3000;
BA_REL_ "GenSigFirstTimeoutTime" BU_SG_REL_ ECM SG_ 1308 DPF_ManualRegenerateInhibit_ISig 12000;
BA_REL_ "GenSigTimeoutTime" BU_SG_REL_ ECM SG_ 1308 DPF_ManualRegenerateInhibit_ISig 3000;
BA_REL_ "GenSigFirstTimeoutTime" BU_SG_REL_ ECM SG_ 1308 OBD_Timestamp_ISig_2 12000;
BA_REL_ "GenSigTimeoutTime" BU_SG_REL_ ECM SG_ 1308 OBD_Timestamp_ISig_2 3000;
BA_REL_ "GenSigFirstTimeoutTime" BU_SG_REL_ ECM SG_ 1308 WaterInFuelDrainRequest_ISig_2 12000;
BA_REL_ "GenSigTimeoutTime" BU_SG_REL_ ECM SG_ 1308 WaterInFuelDrainRequest_ISig_2 3000;
BA_REL_ "GenSigFirstTimeoutTime" BU_SG_REL_ TCM SG_ 1308 HillDataCtrlTGW_State 12000;
BA_REL_ "GenSigTimeoutTime" BU_SG_REL_ TCM SG_ 1308 HillDataCtrlTGW_State 3000;
BA_REL_ "GenSigFirstTimeoutTime" BU_SG_REL_ ECM SG_ 1308 DPF_ManualRegenerateTimeReq_ISig 12000;
BA_REL_ "GenSigTimeoutTime" BU_SG_REL_ ECM SG_ 1308 DPF_ManualRegenerateTimeReq_ISig 3000;
BA_REL_ "GenSigFirstTimeoutTime" BU_SG_REL_ TCM SG_ 1185 SavedHeightControlMode_ISig_2 4800;
BA_REL_ "GenSigTimeoutTime" BU_SG_REL_ TCM SG_ 1185 SavedHeightControlMode_ISig_2 1200;
BA_REL_ "GenSigFirstTimeoutTime" BU_SG_REL_ TCM SG_ 1185 SpeedAdaptEnableRqst_SpeedLimit_ 4800;
BA_REL_ "GenSigTimeoutTime" BU_SG_REL_ TCM SG_ 1185 SpeedAdaptEnableRqst_SpeedLimit_ 1200;
BA_REL_ "GenSigFirstTimeoutTime" BU_SG_REL_ TCM SG_ 1185 SpeedAdaptEnableRqst_Curve_ISig_ 4800;
BA_REL_ "GenSigTimeoutTime" BU_SG_REL_ TCM SG_ 1185 SpeedAdaptEnableRqst_Curve_ISig_ 1200;
BA_REL_ "GenSigFirstTimeoutTime" BU_SG_REL_ TCM SG_ 1185 SpeedAdaptEnableRqst_SlowTraffic 4800;
BA_REL_ "GenSigTimeoutTime" BU_SG_REL_ TCM SG_ 1185 SpeedAdaptEnableRqst_SlowTraffic 1200;
BA_REL_ "GenSigFirstTimeoutTime" BU_SG_REL_ ECM SG_ 1060 EngOvrrideCtrlStat_FireTruckMode 3600;
BA_REL_ "GenSigTimeoutTime" BU_SG_REL_ ECM SG_ 1060 EngOvrrideCtrlStat_FireTruckMode 900;
BA_REL_ "GenSigFirstTimeoutTime" BU_SG_REL_ ECM SG_ 1060 EngOvrrideCtrlStat_ProtOvrrMode 3600;
BA_REL_ "GenSigTimeoutTime" BU_SG_REL_ ECM SG_ 1060 EngOvrrideCtrlStat_ProtOvrrMode 900;
BA_REL_ "GenSigFirstTimeoutTime" BU_SG_REL_ ECM SG_ 1060 EngOvrrideCtrlStat_StartOvrrMode 3600;
BA_REL_ "GenSigTimeoutTime" BU_SG_REL_ ECM SG_ 1060 EngOvrrideCtrlStat_StartOvrrMode 900;
BA_REL_ "GenSigFirstTimeoutTime" BU_SG_REL_ ECM SG_ 1060 EngineAirShutOffCommandStatus 3600;
BA_REL_ "GenSigTimeoutTime" BU_SG_REL_ ECM SG_ 1060 EngineAirShutOffCommandStatus 900;
BA_REL_ "GenSigFirstTimeoutTime" BU_SG_REL_ ECM SG_ 1060 BatteryCurrent_ISig_2 3600;
BA_REL_ "GenSigTimeoutTime" BU_SG_REL_ ECM SG_ 1060 BatteryCurrent_ISig_2 900;
BA_REL_ "GenSigFirstTimeoutTime" BU_SG_REL_ TCM SG_ 932 VehGcvw 3000;
BA_REL_ "GenSigTimeoutTime" BU_SG_REL_ TCM SG_ 932 VehGcvw 600;
BA_REL_ "GenSigFirstTimeoutTime" BU_SG_REL_ ECM SG_ 932 VehGcvw 3000;
BA_REL_ "GenSigTimeoutTime" BU_SG_REL_ ECM SG_ 932 VehGcvw 600;
BA_REL_ "GenSigFirstTimeoutTime" BU_SG_REL_ TCM SG_ 932 ReqdDrvgDir_CRC 3000;
BA_REL_ "GenSigTimeoutTime" BU_SG_REL_ TCM SG_ 932 ReqdDrvgDir_CRC 600;
BA_REL_ "GenSigFirstTimeoutTime" BU_SG_REL_ ECM SG_ 932 SelfStartAssist_stat_ISig_2 3000;
BA_REL_ "GenSigTimeoutTime" BU_SG_REL_ ECM SG_ 932 SelfStartAssist_stat_ISig_2 600;
BA_REL_ "GenSigFirstTimeoutTime" BU_SG_REL_ TCM SG_ 932 EcoRollEnableRequest_ISig_2 3000;
BA_REL_ "GenSigTimeoutTime" BU_SG_REL_ TCM SG_ 932 EcoRollEnableRequest_ISig_2 600;
BA_REL_ "GenSigFirstTimeoutTime" BU_SG_REL_ ECM SG_ 932 SelectedEcoCruiseLevel 3000;
BA_REL_ "GenSigTimeoutTime" BU_SG_REL_ ECM SG_ 932 SelectedEcoCruiseLevel 600;
BA_REL_ "GenSigFirstTimeoutTime" BU_SG_REL_ TCM SG_ 932 SelectedEcoCruiseLevel 3000;
BA_REL_ "GenSigTimeoutTime" BU_SG_REL_ TCM SG_ 932 SelectedEcoCruiseLevel 600;
BA_REL_ "GenSigFirstTimeoutTime" BU_SG_REL_ ECM SG_ 932 CCTrgtSpd_CRC 3000;
BA_REL_ "GenSigTimeoutTime" BU_SG_REL_ ECM SG_ 932 CCTrgtSpd_CRC 600;
BA_REL_ "GenSigFirstTimeoutTime" BU_SG_REL_ TCM SG_ 932 CCTrgtSpd_CRC 3000;
BA_REL_ "GenSigTimeoutTime" BU_SG_REL_ TCM SG_ 932 CCTrgtSpd_CRC 600;
BA_REL_ "GenSigFirstTimeoutTime" BU_SG_REL_ TCM SG_ 932 ReqdVehLongCtrlM_CRC 3000;
BA_REL_ "GenSigTimeoutTime" BU_SG_REL_ TCM SG_ 932 ReqdVehLongCtrlM_CRC 600;
BA_REL_ "GenSigFirstTimeoutTime" BU_SG_REL_ ECM SG_ 932 ReqdVehLongCtrlM_CRC 3000;
BA_REL_ "GenSigTimeoutTime" BU_SG_REL_ ECM SG_ 932 ReqdVehLongCtrlM_CRC 600;
BA_REL_ "GenSigFirstTimeoutTime" BU_SG_REL_ ECM SG_ 932 ReqdVehLongCtrlM_SqC 3000;
BA_REL_ "GenSigTimeoutTime" BU_SG_REL_ ECM SG_ 932 ReqdVehLongCtrlM_SqC 600;
BA_REL_ "GenSigFirstTimeoutTime" BU_SG_REL_ TCM SG_ 932 ReqdVehLongCtrlM_SqC 3000;
BA_REL_ "GenSigTimeoutTime" BU_SG_REL_ TCM SG_ 932 ReqdVehLongCtrlM_SqC 600;
BA_REL_ "GenSigFirstTimeoutTime" BU_SG_REL_ TCM SG_ 932 ACCiRollInhibit 3000;
BA_REL_ "GenSigTimeoutTime" BU_SG_REL_ TCM SG_ 932 ACCiRollInhibit 600;
BA_REL_ "GenSigFirstTimeoutTime" BU_SG_REL_ TCM SG_ 932 ReqdDrvgMode 3000;
BA_REL_ "GenSigTimeoutTime" BU_SG_REL_ TCM SG_ 932 ReqdDrvgMode 600;
BA_REL_ "GenSigFirstTimeoutTime" BU_SG_REL_ ECM SG_ 932 CCBTrgtSpd_CRC 3000;
BA_REL_ "GenSigTimeoutTime" BU_SG_REL_ ECM SG_ 932 CCBTrgtSpd_CRC 600;
BA_REL_ "GenSigFirstTimeoutTime" BU_SG_REL_ TCM SG_ 932 CCBTrgtSpd_CRC 3000;
BA_REL_ "GenSigTimeoutTime" BU_SG_REL_ TCM SG_ 932 CCBTrgtSpd_CRC 600;
BA_REL_ "GenSigFirstTimeoutTime" BU_SG_REL_ ECM SG_ 932 ParkBrake_OBDState 3000;
BA_REL_ "GenSigTimeoutTime" BU_SG_REL_ ECM SG_ 932 ParkBrake_OBDState 600;
BA_REL_ "GenSigFirstTimeoutTime" BU_SG_REL_ ECM SG_ 932 AltParallelOperation 3000;
BA_REL_ "GenSigTimeoutTime" BU_SG_REL_ ECM SG_ 932 AltParallelOperation 600;
BA_REL_ "GenSigFirstTimeoutTime" BU_SG_REL_ ECM SG_ 932 AltLR_cut_offSpeed 3000;
BA_REL_ "GenSigTimeoutTime" BU_SG_REL_ ECM SG_ 932 AltLR_cut_offSpeed 600;
BA_REL_ "GenSigFirstTimeoutTime" BU_SG_REL_ ECM SG_ 932 CCTrgtSpd_Rqst 3000;
BA_REL_ "GenSigTimeoutTime" BU_SG_REL_ ECM SG_ 932 CCTrgtSpd_Rqst 600;
BA_REL_ "GenSigFirstTimeoutTime" BU_SG_REL_ TCM SG_ 932 CCTrgtSpd_Rqst 3000;
BA_REL_ "GenSigTimeoutTime" BU_SG_REL_ TCM SG_ 932 CCTrgtSpd_Rqst 600;
BA_REL_ "GenSigFirstTimeoutTime" BU_SG_REL_ ECM SG_ 932 MaintOilQuality 3000;
BA_REL_ "GenSigTimeoutTime" BU_SG_REL_ ECM SG_ 932 MaintOilQuality 600;
BA_REL_ "GenSigFirstTimeoutTime" BU_SG_REL_ ECM SG_ 932 AirDryerCoolingFanSpeed_rqst 3000;
BA_REL_ "GenSigTimeoutTime" BU_SG_REL_ ECM SG_ 932 AirDryerCoolingFanSpeed_rqst 600;
BA_REL_ "GenSigFirstTimeoutTime" BU_SG_REL_ ECM SG_ 932 VIN_rqst_ISig_2 3000;
BA_REL_ "GenSigTimeoutTime" BU_SG_REL_ ECM SG_ 932 VIN_rqst_ISig_2 600;
BA_REL_ "GenSigFirstTimeoutTime" BU_SG_REL_ TCM SG_ 932 VIN_rqst_ISig_2 3000;
BA_REL_ "GenSigTimeoutTime" BU_SG_REL_ TCM SG_ 932 VIN_rqst_ISig_2 600;
BA_REL_ "GenSigFirstTimeoutTime" BU_SG_REL_ TCM SG_ 932 ReqdEcoRoll 3000;
BA_REL_ "GenSigTimeoutTime" BU_SG_REL_ TCM SG_ 932 ReqdEcoRoll 600;
BA_REL_ "GenSigFirstTimeoutTime" BU_SG_REL_ TCM SG_ 932 CCBTrgtSpd_Rqst 3000;
BA_REL_ "GenSigTimeoutTime" BU_SG_REL_ TCM SG_ 932 CCBTrgtSpd_Rqst 600;
BA_REL_ "GenSigFirstTimeoutTime" BU_SG_REL_ ECM SG_ 932 CCBTrgtSpd_Rqst 3000;
BA_REL_ "GenSigTimeoutTime" BU_SG_REL_ ECM SG_ 932 CCBTrgtSpd_Rqst 600;
BA_REL_ "GenSigFirstTimeoutTime" BU_SG_REL_ ECM SG_ 932 AltVoltageSetValue 3000;
BA_REL_ "GenSigTimeoutTime" BU_SG_REL_ ECM SG_ 932 AltVoltageSetValue 600;
BA_REL_ "GenSigFirstTimeoutTime" BU_SG_REL_ TCM SG_ 932 ACCiSeeDistanceGap 3000;
BA_REL_ "GenSigTimeoutTime" BU_SG_REL_ TCM SG_ 932 ACCiSeeDistanceGap 600;
BA_REL_ "GenSigFirstTimeoutTime" BU_SG_REL_ TCM SG_ 932 ReqdVehLongCtrlM_Mode 3000;
BA_REL_ "GenSigTimeoutTime" BU_SG_REL_ TCM SG_ 932 ReqdVehLongCtrlM_Mode 600;
BA_REL_ "GenSigFirstTimeoutTime" BU_SG_REL_ ECM SG_ 932 ReqdVehLongCtrlM_Mode 3000;
BA_REL_ "GenSigTimeoutTime" BU_SG_REL_ ECM SG_ 932 ReqdVehLongCtrlM_Mode 600;
BA_REL_ "GenSigFirstTimeoutTime" BU_SG_REL_ ECM SG_ 932 CCBTrgtSpd_SqC 3000;
BA_REL_ "GenSigTimeoutTime" BU_SG_REL_ ECM SG_ 932 CCBTrgtSpd_SqC 600;
BA_REL_ "GenSigFirstTimeoutTime" BU_SG_REL_ TCM SG_ 932 CCBTrgtSpd_SqC 3000;
BA_REL_ "GenSigTimeoutTime" BU_SG_REL_ TCM SG_ 932 CCBTrgtSpd_SqC 600;
BA_REL_ "GenSigFirstTimeoutTime" BU_SG_REL_ ECM SG_ 932 ACCoolingFanSpeedRequest 3000;
BA_REL_ "GenSigTimeoutTime" BU_SG_REL_ ECM SG_ 932 ACCoolingFanSpeedRequest 600;
BA_REL_ "GenSigFirstTimeoutTime" BU_SG_REL_ TCM SG_ 932 SpeedAdaptationLevelRqst_ISig_2 3000;
BA_REL_ "GenSigTimeoutTime" BU_SG_REL_ TCM SG_ 932 SpeedAdaptationLevelRqst_ISig_2 600;
BA_REL_ "GenSigFirstTimeoutTime" BU_SG_REL_ TCM SG_ 932 ReqdGear 3000;
BA_REL_ "GenSigTimeoutTime" BU_SG_REL_ TCM SG_ 932 ReqdGear 600;
BA_REL_ "GenSigFirstTimeoutTime" BU_SG_REL_ ECM SG_ 932 AltExitationCurrentLimit 3000;
BA_REL_ "GenSigTimeoutTime" BU_SG_REL_ ECM SG_ 932 AltExitationCurrentLimit 600;
BA_REL_ "GenSigFirstTimeoutTime" BU_SG_REL_ ECM SG_ 932 ReqdSGoMode_SqC 3000;
BA_REL_ "GenSigTimeoutTime" BU_SG_REL_ ECM SG_ 932 ReqdSGoMode_SqC 600;
BA_REL_ "GenSigFirstTimeoutTime" BU_SG_REL_ TCM SG_ 932 ReqdSGoMode_SqC 3000;
BA_REL_ "GenSigTimeoutTime" BU_SG_REL_ TCM SG_ 932 ReqdSGoMode_SqC 600;
BA_REL_ "GenSigFirstTimeoutTime" BU_SG_REL_ ECM SG_ 932 ReqdSGoMode_CRC 3000;
BA_REL_ "GenSigTimeoutTime" BU_SG_REL_ ECM SG_ 932 ReqdSGoMode_CRC 600;
BA_REL_ "GenSigFirstTimeoutTime" BU_SG_REL_ TCM SG_ 932 ReqdSGoMode_CRC 3000;
BA_REL_ "GenSigTimeoutTime" BU_SG_REL_ TCM SG_ 932 ReqdSGoMode_CRC 600;
BA_REL_ "GenSigFirstTimeoutTime" BU_SG_REL_ TCM SG_ 932 RSLAssistStatus 3000;
BA_REL_ "GenSigTimeoutTime" BU_SG_REL_ TCM SG_ 932 RSLAssistStatus 600;
BA_REL_ "GenSigFirstTimeoutTime" BU_SG_REL_ ECM SG_ 932 CCTrgtSpd_SqC 3000;
BA_REL_ "GenSigTimeoutTime" BU_SG_REL_ ECM SG_ 932 CCTrgtSpd_SqC 600;
BA_REL_ "GenSigFirstTimeoutTime" BU_SG_REL_ TCM SG_ 932 CCTrgtSpd_SqC 3000;
BA_REL_ "GenSigTimeoutTime" BU_SG_REL_ TCM SG_ 932 CCTrgtSpd_SqC 600;
BA_REL_ "GenSigFirstTimeoutTime" BU_SG_REL_ ECM SG_ 932 AcCoolantPumpEngagementRequest_I 3000;
BA_REL_ "GenSigTimeoutTime" BU_SG_REL_ ECM SG_ 932 AcCoolantPumpEngagementRequest_I 600;
BA_REL_ "GenSigFirstTimeoutTime" BU_SG_REL_ ECM SG_ 932 CruiseControlStates 3000;
BA_REL_ "GenSigTimeoutTime" BU_SG_REL_ ECM SG_ 932 CruiseControlStates 600;
BA_REL_ "GenSigFirstTimeoutTime" BU_SG_REL_ TCM SG_ 932 CruiseControlStates 3000;
BA_REL_ "GenSigTimeoutTime" BU_SG_REL_ TCM SG_ 932 CruiseControlStates 600;
BA_REL_ "GenSigFirstTimeoutTime" BU_SG_REL_ ECM SG_ 932 AltDataSelectionWordRx 3000;
BA_REL_ "GenSigTimeoutTime" BU_SG_REL_ ECM SG_ 932 AltDataSelectionWordRx 600;
BA_REL_ "GenSigFirstTimeoutTime" BU_SG_REL_ ECM SG_ 932 ClutchSwitch_ISig_2 3000;
BA_REL_ "GenSigTimeoutTime" BU_SG_REL_ ECM SG_ 932 ClutchSwitch_ISig_2 600;
BA_REL_ "GenSigFirstTimeoutTime" BU_SG_REL_ ECM SG_ 932 ReqdSGoMode_Mode 3000;
BA_REL_ "GenSigTimeoutTime" BU_SG_REL_ ECM SG_ 932 ReqdSGoMode_Mode 600;
BA_REL_ "GenSigFirstTimeoutTime" BU_SG_REL_ TCM SG_ 932 ReqdSGoMode_Mode 3000;
BA_REL_ "GenSigTimeoutTime" BU_SG_REL_ TCM SG_ 932 ReqdSGoMode_Mode 600;
BA_REL_ "GenSigFirstTimeoutTime" BU_SG_REL_ ECM SG_ 932 MaintOilReset 3000;
BA_REL_ "GenSigTimeoutTime" BU_SG_REL_ ECM SG_ 932 MaintOilReset 600;
BA_REL_ "GenSigFirstTimeoutTime" BU_SG_REL_ ECM SG_ 932 AltLR_RampTime 3000;
BA_REL_ "GenSigTimeoutTime" BU_SG_REL_ ECM SG_ 932 AltLR_RampTime 600;
BA_REL_ "GenSigFirstTimeoutTime" BU_SG_REL_ TCM SG_ 932 ReqdDrvgDir_Direction 3000;
BA_REL_ "GenSigTimeoutTime" BU_SG_REL_ TCM SG_ 932 ReqdDrvgDir_Direction 600;
BA_REL_ "GenSigFirstTimeoutTime" BU_SG_REL_ TCM SG_ 932 CACCStatus_ISig_2 3000;
BA_REL_ "GenSigTimeoutTime" BU_SG_REL_ TCM SG_ 932 CACCStatus_ISig_2 600;
BA_REL_ "GenSigFirstTimeoutTime" BU_SG_REL_ TCM SG_ 932 ReqdDrvgDir_SqC 3000;
BA_REL_ "GenSigTimeoutTime" BU_SG_REL_ TCM SG_ 932 ReqdDrvgDir_SqC 600;
BA_REL_ "GenSigFirstTimeoutTime" BU_SG_REL_ TCM SG_ 300 XRSLBTrgtSpd_CRC 3000;
BA_REL_ "GenSigTimeoutTime" BU_SG_REL_ TCM SG_ 300 XRSLBTrgtSpd_CRC 60;
BA_REL_ "GenSigFirstTimeoutTime" BU_SG_REL_ ECM SG_ 300 XRSLBTrgtSpd_CRC 3000;
BA_REL_ "GenSigTimeoutTime" BU_SG_REL_ ECM SG_ 300 XRSLBTrgtSpd_CRC 60;
BA_REL_ "GenSigFirstTimeoutTime" BU_SG_REL_ TCM SG_ 300 AcceleratorPedalPositionVendor 3000;
BA_REL_ "GenSigTimeoutTime" BU_SG_REL_ TCM SG_ 300 AcceleratorPedalPositionVendor 60;
BA_REL_ "GenSigFirstTimeoutTime" BU_SG_REL_ ECM SG_ 300 AccPedal_Pos 3000;
BA_REL_ "GenSigTimeoutTime" BU_SG_REL_ ECM SG_ 300 AccPedal_Pos 60;
BA_REL_ "GenSigFirstTimeoutTime" BU_SG_REL_ TCM SG_ 300 AccPedal_Pos 3000;
BA_REL_ "GenSigTimeoutTime" BU_SG_REL_ TCM SG_ 300 AccPedal_Pos 60;
BA_REL_ "GenSigFirstTimeoutTime" BU_SG_REL_ ECM SG_ 300 XRSLTrgtSpd_CRC 3000;
BA_REL_ "GenSigTimeoutTime" BU_SG_REL_ ECM SG_ 300 XRSLTrgtSpd_CRC 60;
BA_REL_ "GenSigFirstTimeoutTime" BU_SG_REL_ TCM SG_ 300 AccPedal_Qlty 3000;
BA_REL_ "GenSigTimeoutTime" BU_SG_REL_ TCM SG_ 300 AccPedal_Qlty 60;
BA_REL_ "GenSigFirstTimeoutTime" BU_SG_REL_ ECM SG_ 300 AccPedal_Qlty 3000;
BA_REL_ "GenSigTimeoutTime" BU_SG_REL_ ECM SG_ 300 AccPedal_Qlty 60;
BA_REL_ "GenSigFirstTimeoutTime" BU_SG_REL_ TCM SG_ 300 XRSLBTrgtSpd_SqC 3000;
BA_REL_ "GenSigTimeoutTime" BU_SG_REL_ TCM SG_ 300 XRSLBTrgtSpd_SqC 60;
BA_REL_ "GenSigFirstTimeoutTime" BU_SG_REL_ ECM SG_ 300 XRSLBTrgtSpd_SqC 3000;
BA_REL_ "GenSigTimeoutTime" BU_SG_REL_ ECM SG_ 300 XRSLBTrgtSpd_SqC 60;
BA_REL_ "GenSigFirstTimeoutTime" BU_SG_REL_ ECM SG_ 300 XRSLTrgtSpd_SqC 3000;
BA_REL_ "GenSigTimeoutTime" BU_SG_REL_ ECM SG_ 300 XRSLTrgtSpd_SqC 60;
BA_REL_ "GenSigFirstTimeoutTime" BU_SG_REL_ ECM SG_ 300 AccPedal_SqC 3000;
BA_REL_ "GenSigTimeoutTime" BU_SG_REL_ ECM SG_ 300 AccPedal_SqC 60;
BA_REL_ "GenSigFirstTimeoutTime" BU_SG_REL_ TCM SG_ 300 AccPedal_SqC 3000;
BA_REL_ "GenSigTimeoutTime" BU_SG_REL_ TCM SG_ 300 AccPedal_SqC 60;
BA_REL_ "GenSigFirstTimeoutTime" BU_SG_REL_ ECM SG_ 300 XRSLTrgtSpd_Rqst 3000;
BA_REL_ "GenSigTimeoutTime" BU_SG_REL_ ECM SG_ 300 XRSLTrgtSpd_Rqst 60;
BA_REL_ "GenSigFirstTimeoutTime" BU_SG_REL_ ECM SG_ 300 XRSLBTrgtSpd_Rqst 3000;
BA_REL_ "GenSigTimeoutTime" BU_SG_REL_ ECM SG_ 300 XRSLBTrgtSpd_Rqst 60;
BA_REL_ "GenSigFirstTimeoutTime" BU_SG_REL_ TCM SG_ 300 XRSLBTrgtSpd_Rqst 3000;
BA_REL_ "GenSigTimeoutTime" BU_SG_REL_ TCM SG_ 300 XRSLBTrgtSpd_Rqst 60;
BA_REL_ "GenSigFirstTimeoutTime" BU_SG_REL_ TCM SG_ 300 AccPedal_CRC 3000;
BA_REL_ "GenSigTimeoutTime" BU_SG_REL_ TCM SG_ 300 AccPedal_CRC 60;
BA_REL_ "GenSigFirstTimeoutTime" BU_SG_REL_ ECM SG_ 300 AccPedal_CRC 3000;
BA_REL_ "GenSigTimeoutTime" BU_SG_REL_ ECM SG_ 300 AccPedal_CRC 60;
BA_REL_ "GenSigFirstTimeoutTime" BU_SG_REL_ TCM SG_ 1246 TagAxleLoad_ISig_2 6000;
BA_REL_ "GenSigTimeoutTime" BU_SG_REL_ TCM SG_ 1246 TagAxleLoad_ISig_2 1500;
BA_REL_ "GenSigFirstTimeoutTime" BU_SG_REL_ ECM SG_ 1246 SecondaryDriveAxleLoad_ISig_2 6000;
BA_REL_ "GenSigTimeoutTime" BU_SG_REL_ ECM SG_ 1246 SecondaryDriveAxleLoad_ISig_2 1500;
BA_REL_ "GenSigFirstTimeoutTime" BU_SG_REL_ TCM SG_ 1246 SecondaryDriveAxleLoad_ISig_2 6000;
BA_REL_ "GenSigTimeoutTime" BU_SG_REL_ TCM SG_ 1246 SecondaryDriveAxleLoad_ISig_2 1500;
BA_REL_ "GenSigFirstTimeoutTime" BU_SG_REL_ ECM SG_ 1246 StarterMotorReset_rqst 6000;
BA_REL_ "GenSigTimeoutTime" BU_SG_REL_ ECM SG_ 1246 StarterMotorReset_rqst 1500;
BA_REL_ "GenSigFirstTimeoutTime" BU_SG_REL_ TCM SG_ 1246 PwtCCUnderSpeedRequest 6000;
BA_REL_ "GenSigTimeoutTime" BU_SG_REL_ TCM SG_ 1246 PwtCCUnderSpeedRequest 1500;
BA_REL_ "GenSigFirstTimeoutTime" BU_SG_REL_ TCM SG_ 1246 FrontAxle1Load_ISig_2 6000;
BA_REL_ "GenSigTimeoutTime" BU_SG_REL_ TCM SG_ 1246 FrontAxle1Load_ISig_2 1500;
BA_REL_ "GenSigFirstTimeoutTime" BU_SG_REL_ TCM SG_ 1246 FrontAxle2Load_ISig_2 6000;
BA_REL_ "GenSigTimeoutTime" BU_SG_REL_ TCM SG_ 1246 FrontAxle2Load_ISig_2 1500;
BA_REL_ "GenSigFirstTimeoutTime" BU_SG_REL_ TCM SG_ 1246 PusherAxleLoad_ISig_2 6000;
BA_REL_ "GenSigTimeoutTime" BU_SG_REL_ TCM SG_ 1246 PusherAxleLoad_ISig_2 1500;
BA_REL_ "GenSigFirstTimeoutTime" BU_SG_REL_ TCM SG_ 1246 DriveAxleLoad_ISig_2 6000;
BA_REL_ "GenSigTimeoutTime" BU_SG_REL_ TCM SG_ 1246 DriveAxleLoad_ISig_2 1500;
BA_REL_ "GenSigFirstTimeoutTime" BU_SG_REL_ TCM SG_ 746 Pto1ConsentRequest 3000;
BA_REL_ "GenSigTimeoutTime" BU_SG_REL_ TCM SG_ 746 Pto1ConsentRequest 300;
BA_REL_ "GenSigFirstTimeoutTime" BU_SG_REL_ TCM SG_ 746 CCBSetSpeed 3000;
BA_REL_ "GenSigTimeoutTime" BU_SG_REL_ TCM SG_ 746 CCBSetSpeed 300;
BA_REL_ "GenSigFirstTimeoutTime" BU_SG_REL_ ECM SG_ 746 SecondThrottle 3000;
BA_REL_ "GenSigTimeoutTime" BU_SG_REL_ ECM SG_ 746 SecondThrottle 300;
BA_REL_ "GenSigFirstTimeoutTime" BU_SG_REL_ TCM SG_ 746 CCBTargetSpeedRequest 3000;
BA_REL_ "GenSigTimeoutTime" BU_SG_REL_ TCM SG_ 746 CCBTargetSpeedRequest 300;
BA_REL_ "GenSigFirstTimeoutTime" BU_SG_REL_ ECM SG_ 746 CCBTargetSpeedRequest 3000;
BA_REL_ "GenSigTimeoutTime" BU_SG_REL_ ECM SG_ 746 CCBTargetSpeedRequest 300;
BA_REL_ "GenSigFirstTimeoutTime" BU_SG_REL_ TCM SG_ 746 TransferCaseOrSplitboxPTOMode_IS 3000;
BA_REL_ "GenSigTimeoutTime" BU_SG_REL_ TCM SG_ 746 TransferCaseOrSplitboxPTOMode_IS 300;
BA_REL_ "GenSigFirstTimeoutTime" BU_SG_REL_ ECM SG_ 746 PtosStatus_ISig_2 3000;
BA_REL_ "GenSigTimeoutTime" BU_SG_REL_ ECM SG_ 746 PtosStatus_ISig_2 300;
BA_REL_ "GenSigFirstTimeoutTime" BU_SG_REL_ TCM SG_ 746 ConstructionSwitch_stat 3000;
BA_REL_ "GenSigTimeoutTime" BU_SG_REL_ TCM SG_ 746 ConstructionSwitch_stat 300;
BA_REL_ "GenSigFirstTimeoutTime" BU_SG_REL_ ECM SG_ 746 RegenInhibitVehicleHeight_ISig_2 3000;
BA_REL_ "GenSigTimeoutTime" BU_SG_REL_ ECM SG_ 746 RegenInhibitVehicleHeight_ISig_2 300;
BA_REL_ "GenSigFirstTimeoutTime" BU_SG_REL_ ECM SG_ 746 PtoRequest 3000;
BA_REL_ "GenSigTimeoutTime" BU_SG_REL_ ECM SG_ 746 PtoRequest 300;
BA_REL_ "GenSigFirstTimeoutTime" BU_SG_REL_ TCM SG_ 746 Pto2Status_ISig_2 3000;
BA_REL_ "GenSigTimeoutTime" BU_SG_REL_ TCM SG_ 746 Pto2Status_ISig_2 300;
BA_REL_ "GenSigFirstTimeoutTime" BU_SG_REL_ ECM SG_ 746 TrailerConnected_ISig_2 3000;
BA_REL_ "GenSigTimeoutTime" BU_SG_REL_ ECM SG_ 746 TrailerConnected_ISig_2 300;
BA_REL_ "GenSigFirstTimeoutTime" BU_SG_REL_ TCM SG_ 746 TrailerConnected_ISig_2 3000;
BA_REL_ "GenSigTimeoutTime" BU_SG_REL_ TCM SG_ 746 TrailerConnected_ISig_2 300;
BA_REL_ "GenSigFirstTimeoutTime" BU_SG_REL_ ECM SG_ 746 WarmUp_Request 3000;
BA_REL_ "GenSigTimeoutTime" BU_SG_REL_ ECM SG_ 746 WarmUp_Request 300;
BA_REL_ "GenSigFirstTimeoutTime" BU_SG_REL_ TCM SG_ 746 ParkBrakeReleasePossible_stat_IS 3000;
BA_REL_ "GenSigTimeoutTime" BU_SG_REL_ TCM SG_ 746 ParkBrakeReleasePossible_stat_IS 300;
BA_REL_ "GenSigFirstTimeoutTime" BU_SG_REL_ ECM SG_ 746 AC_CompressorClutchCmd_ISig_2 3000;
BA_REL_ "GenSigTimeoutTime" BU_SG_REL_ ECM SG_ 746 AC_CompressorClutchCmd_ISig_2 300;
BA_REL_ "GenSigFirstTimeoutTime" BU_SG_REL_ TCM SG_ 746 CCSetSpeed_ISig_2 3000;
BA_REL_ "GenSigTimeoutTime" BU_SG_REL_ TCM SG_ 746 CCSetSpeed_ISig_2 300;
BA_REL_ "GenSigFirstTimeoutTime" BU_SG_REL_ ECM SG_ 746 ESCReqEMS_CtrlTrimReq 3000;
BA_REL_ "GenSigTimeoutTime" BU_SG_REL_ ECM SG_ 746 ESCReqEMS_CtrlTrimReq 300;
BA_REL_ "GenSigFirstTimeoutTime" BU_SG_REL_ TCM SG_ 746 ESCReqEMS_CtrlTrimReq 3000;
BA_REL_ "GenSigTimeoutTime" BU_SG_REL_ TCM SG_ 746 ESCReqEMS_CtrlTrimReq 300;
BA_REL_ "GenSigFirstTimeoutTime" BU_SG_REL_ ECM SG_ 746 ESCReqEMS_CtrlTrimValue 3000;
BA_REL_ "GenSigTimeoutTime" BU_SG_REL_ ECM SG_ 746 ESCReqEMS_CtrlTrimValue 300;
BA_REL_ "GenSigFirstTimeoutTime" BU_SG_REL_ TCM SG_ 746 ESCReqEMS_CtrlTrimValue 3000;
BA_REL_ "GenSigTimeoutTime" BU_SG_REL_ TCM SG_ 746 ESCReqEMS_CtrlTrimValue 300;
BA_REL_ "GenSigFirstTimeoutTime" BU_SG_REL_ TCM SG_ 746 Pto1Status_ISig_2 3000;
BA_REL_ "GenSigTimeoutTime" BU_SG_REL_ TCM SG_ 746 Pto1Status_ISig_2 300;
BA_REL_ "GenSigFirstTimeoutTime" BU_SG_REL_ ECM SG_ 746 ESCReqEMS_CtrlTrimStat 3000;
BA_REL_ "GenSigTimeoutTime" BU_SG_REL_ ECM SG_ 746 ESCReqEMS_CtrlTrimStat 300;
BA_REL_ "GenSigFirstTimeoutTime" BU_SG_REL_ TCM SG_ 746 ESCReqEMS_CtrlTrimStat 3000;
BA_REL_ "GenSigTimeoutTime" BU_SG_REL_ TCM SG_ 746 ESCReqEMS_CtrlTrimStat 300;
BA_REL_ "GenSigFirstTimeoutTime" BU_SG_REL_ ECM SG_ 746 XRSLTargetSpeedRequest 3000;
BA_REL_ "GenSigTimeoutTime" BU_SG_REL_ ECM SG_ 746 XRSLTargetSpeedRequest 300;
BA_REL_ "GenSigFirstTimeoutTime" BU_SG_REL_ TCM SG_ 746 CtaGcAlternativeGearStarter 3000;
BA_REL_ "GenSigTimeoutTime" BU_SG_REL_ TCM SG_ 746 CtaGcAlternativeGearStarter 300;
BA_REL_ "GenSigFirstTimeoutTime" BU_SG_REL_ TCM SG_ 746 XRSLBTargetSpeedRequest 3000;
BA_REL_ "GenSigTimeoutTime" BU_SG_REL_ TCM SG_ 746 XRSLBTargetSpeedRequest 300;
BA_REL_ "GenSigFirstTimeoutTime" BU_SG_REL_ ECM SG_ 746 XRSLBTargetSpeedRequest 3000;
BA_REL_ "GenSigTimeoutTime" BU_SG_REL_ ECM SG_ 746 XRSLBTargetSpeedRequest 300;
BA_REL_ "GenSigFirstTimeoutTime" BU_SG_REL_ TCM SG_ 746 Pto2ConsentRequest 3000;
BA_REL_ "GenSigTimeoutTime" BU_SG_REL_ TCM SG_ 746 Pto2ConsentRequest 300;
BA_REL_ "GenSigFirstTimeoutTime" BU_SG_REL_ TCM SG_ 746 EngPtoConsumesTorque 3000;
BA_REL_ "GenSigTimeoutTime" BU_SG_REL_ TCM SG_ 746 EngPtoConsumesTorque 300;
BA_REL_ "GenSigFirstTimeoutTime" BU_SG_REL_ TCM SG_ 746 ESCReqEMS_CtrlTrimMode 3000;
BA_REL_ "GenSigTimeoutTime" BU_SG_REL_ TCM SG_ 746 ESCReqEMS_CtrlTrimMode 300;
BA_REL_ "GenSigFirstTimeoutTime" BU_SG_REL_ ECM SG_ 746 ESCReqEMS_CtrlTrimMode 3000;
BA_REL_ "GenSigTimeoutTime" BU_SG_REL_ ECM SG_ 746 ESCReqEMS_CtrlTrimMode 300;
BA_REL_ "GenSigFirstTimeoutTime" BU_SG_REL_ ECM SG_ 746 TrailerABSStatus_ISig_2 3000;
BA_REL_ "GenSigTimeoutTime" BU_SG_REL_ ECM SG_ 746 TrailerABSStatus_ISig_2 300;
BA_REL_ "GenSigFirstTimeoutTime" BU_SG_REL_ TCM SG_ 746 TrailerABSStatus_ISig_2 3000;
BA_REL_ "GenSigTimeoutTime" BU_SG_REL_ TCM SG_ 746 TrailerABSStatus_ISig_2 300;
BA_REL_ "GenSigFirstTimeoutTime" BU_SG_REL_ TCM SG_ 746 CtaGcInhibitGearEngaged 3000;
BA_REL_ "GenSigTimeoutTime" BU_SG_REL_ TCM SG_ 746 CtaGcInhibitGearEngaged 300;
BA_REL_ "GenSigFirstTimeoutTime" BU_SG_REL_ TCM SG_ 746 RearEndPositionStatus_ISig_2 3000;
BA_REL_ "GenSigTimeoutTime" BU_SG_REL_ TCM SG_ 746 RearEndPositionStatus_ISig_2 300;
BA_REL_ "GenSigFirstTimeoutTime" BU_SG_REL_ ECM SG_ 746 StoreIdleValue_ISig_2 3000;
BA_REL_ "GenSigTimeoutTime" BU_SG_REL_ ECM SG_ 746 StoreIdleValue_ISig_2 300;
BA_REL_ "GenSigFirstTimeoutTime" BU_SG_REL_ TCM SG_ 746 CtaGcReverseInhibit 3000;
BA_REL_ "GenSigTimeoutTime" BU_SG_REL_ TCM SG_ 746 CtaGcReverseInhibit 300;
BA_REL_ "GenSigFirstTimeoutTime" BU_SG_REL_ TCM SG_ 746 CCTargetSpeedRequest 3000;
BA_REL_ "GenSigTimeoutTime" BU_SG_REL_ TCM SG_ 746 CCTargetSpeedRequest 300;
BA_REL_ "GenSigFirstTimeoutTime" BU_SG_REL_ ECM SG_ 746 CCTargetSpeedRequest 3000;
BA_REL_ "GenSigTimeoutTime" BU_SG_REL_ ECM SG_ 746 CCTargetSpeedRequest 300;
BA_REL_ "GenSigFirstTimeoutTime" BU_SG_REL_ ECM SG_ 746 AirCompressorStatus_ISig_2 3000;
BA_REL_ "GenSigTimeoutTime" BU_SG_REL_ ECM SG_ 746 AirCompressorStatus_ISig_2 300;
BA_REL_ "GenSigFirstTimeoutTime" BU_SG_REL_ TCM SG_ 391 ReqdLongDist_AllwdBndUppr 3000;
BA_REL_ "GenSigTimeoutTime" BU_SG_REL_ TCM SG_ 391 ReqdLongDist_AllwdBndUppr 120;
BA_REL_ "GenSigFirstTimeoutTime" BU_SG_REL_ TCM SG_ 391 ParkingBrake_stat_ISig_2 3000;
BA_REL_ "GenSigTimeoutTime" BU_SG_REL_ TCM SG_ 391 ParkingBrake_stat_ISig_2 120;
BA_REL_ "GenSigFirstTimeoutTime" BU_SG_REL_ ECM SG_ 391 ParkingBrake_stat_ISig_2 3000;
BA_REL_ "GenSigTimeoutTime" BU_SG_REL_ ECM SG_ 391 ParkingBrake_stat_ISig_2 120;
BA_REL_ "GenSigFirstTimeoutTime" BU_SG_REL_ TCM SG_ 391 ReqdLongSpd_CRC 3000;
BA_REL_ "GenSigTimeoutTime" BU_SG_REL_ TCM SG_ 391 ReqdLongSpd_CRC 120;
BA_REL_ "GenSigFirstTimeoutTime" BU_SG_REL_ ECM SG_ 391 ReqdLongSpd_CRC 3000;
BA_REL_ "GenSigTimeoutTime" BU_SG_REL_ ECM SG_ 391 ReqdLongSpd_CRC 120;
BA_REL_ "GenSigFirstTimeoutTime" BU_SG_REL_ TCM SG_ 391 RequestedUpshiftDownshiftSteps 3000;
BA_REL_ "GenSigTimeoutTime" BU_SG_REL_ TCM SG_ 391 RequestedUpshiftDownshiftSteps 120;
BA_REL_ "GenSigFirstTimeoutTime" BU_SG_REL_ TCM SG_ 391 LiftAxle1PositionStatus_ISig_2 3000;
BA_REL_ "GenSigTimeoutTime" BU_SG_REL_ TCM SG_ 391 LiftAxle1PositionStatus_ISig_2 120;
BA_REL_ "GenSigFirstTimeoutTime" BU_SG_REL_ ECM SG_ 391 EngineSystemPowerDownRequest 3000;
BA_REL_ "GenSigTimeoutTime" BU_SG_REL_ ECM SG_ 391 EngineSystemPowerDownRequest 120;
BA_REL_ "GenSigFirstTimeoutTime" BU_SG_REL_ TCM SG_ 391 LimpHomeSwitch_stat 3000;
BA_REL_ "GenSigTimeoutTime" BU_SG_REL_ TCM SG_ 391 LimpHomeSwitch_stat 120;
BA_REL_ "GenSigFirstTimeoutTime" BU_SG_REL_ TCM SG_ 391 ReqdLongSpd_SqC 3000;
BA_REL_ "GenSigTimeoutTime" BU_SG_REL_ TCM SG_ 391 ReqdLongSpd_SqC 120;
BA_REL_ "GenSigFirstTimeoutTime" BU_SG_REL_ ECM SG_ 391 ReqdLongSpd_SqC 3000;
BA_REL_ "GenSigTimeoutTime" BU_SG_REL_ ECM SG_ 391 ReqdLongSpd_SqC 120;
BA_REL_ "GenSigFirstTimeoutTime" BU_SG_REL_ TCM SG_ 391 ReqdLongDist_Distance 3000;
BA_REL_ "GenSigTimeoutTime" BU_SG_REL_ TCM SG_ 391 ReqdLongDist_Distance 120;
BA_REL_ "GenSigFirstTimeoutTime" BU_SG_REL_ TCM SG_ 391 EconomyPowerSwitch_stat 3000;
BA_REL_ "GenSigTimeoutTime" BU_SG_REL_ TCM SG_ 391 EconomyPowerSwitch_stat 120;
BA_REL_ "GenSigFirstTimeoutTime" BU_SG_REL_ TCM SG_ 391 AcceleratorPedalPositionBackup 3000;
BA_REL_ "GenSigTimeoutTime" BU_SG_REL_ TCM SG_ 391 AcceleratorPedalPositionBackup 120;
BA_REL_ "GenSigFirstTimeoutTime" BU_SG_REL_ ECM SG_ 391 AcceleratorPedalPositionBackup 3000;
BA_REL_ "GenSigTimeoutTime" BU_SG_REL_ ECM SG_ 391 AcceleratorPedalPositionBackup 120;
BA_REL_ "GenSigFirstTimeoutTime" BU_SG_REL_ ECM SG_ 391 UpShiftRequest 3000;
BA_REL_ "GenSigTimeoutTime" BU_SG_REL_ ECM SG_ 391 UpShiftRequest 120;
BA_REL_ "GenSigFirstTimeoutTime" BU_SG_REL_ TCM SG_ 391 UpShiftRequest 3000;
BA_REL_ "GenSigTimeoutTime" BU_SG_REL_ TCM SG_ 391 UpShiftRequest 120;
BA_REL_ "GenSigFirstTimeoutTime" BU_SG_REL_ TCM SG_ 391 ACCForwardVehicleDistance 3000;
BA_REL_ "GenSigTimeoutTime" BU_SG_REL_ TCM SG_ 391 ACCForwardVehicleDistance 120;
BA_REL_ "GenSigFirstTimeoutTime" BU_SG_REL_ ECM SG_ 391 EngineStopRequest 3000;
BA_REL_ "GenSigTimeoutTime" BU_SG_REL_ ECM SG_ 391 EngineStopRequest 120;
BA_REL_ "GenSigFirstTimeoutTime" BU_SG_REL_ TCM SG_ 391 EngineOperationCtrl 3000;
BA_REL_ "GenSigTimeoutTime" BU_SG_REL_ TCM SG_ 391 EngineOperationCtrl 120;
BA_REL_ "GenSigFirstTimeoutTime" BU_SG_REL_ ECM SG_ 391 EngineOperationCtrl 3000;
BA_REL_ "GenSigTimeoutTime" BU_SG_REL_ ECM SG_ 391 EngineOperationCtrl 120;
BA_REL_ "GenSigFirstTimeoutTime" BU_SG_REL_ ECM SG_ 391 DownShiftRequest 3000;
BA_REL_ "GenSigTimeoutTime" BU_SG_REL_ ECM SG_ 391 DownShiftRequest 120;
BA_REL_ "GenSigFirstTimeoutTime" BU_SG_REL_ TCM SG_ 391 DownShiftRequest 3000;
BA_REL_ "GenSigTimeoutTime" BU_SG_REL_ TCM SG_ 391 DownShiftRequest 120;
BA_REL_ "GenSigFirstTimeoutTime" BU_SG_REL_ TCM SG_ 391 CM_DisengageDrivelineRequest 3000;
BA_REL_ "GenSigTimeoutTime" BU_SG_REL_ TCM SG_ 391 CM_DisengageDrivelineRequest 120;
BA_REL_ "GenSigFirstTimeoutTime" BU_SG_REL_ TCM SG_ 391 ReqdLongAccel_SqC 3000;
BA_REL_ "GenSigTimeoutTime" BU_SG_REL_ TCM SG_ 391 ReqdLongAccel_SqC 120;
BA_REL_ "GenSigFirstTimeoutTime" BU_SG_REL_ ECM SG_ 391 ReqdLongAccel_SqC 3000;
BA_REL_ "GenSigTimeoutTime" BU_SG_REL_ ECM SG_ 391 ReqdLongAccel_SqC 120;
BA_REL_ "GenSigFirstTimeoutTime" BU_SG_REL_ ECM SG_ 391 ReqdLongAccel_CRC 3000;
BA_REL_ "GenSigTimeoutTime" BU_SG_REL_ ECM SG_ 391 ReqdLongAccel_CRC 120;
BA_REL_ "GenSigFirstTimeoutTime" BU_SG_REL_ TCM SG_ 391 ReqdLongAccel_CRC 3000;
BA_REL_ "GenSigTimeoutTime" BU_SG_REL_ TCM SG_ 391 ReqdLongAccel_CRC 120;
BA_REL_ "GenSigFirstTimeoutTime" BU_SG_REL_ TCM SG_ 391 TransmSystemPowerDown_rqst 3000;
BA_REL_ "GenSigTimeoutTime" BU_SG_REL_ TCM SG_ 391 TransmSystemPowerDown_rqst 120;
BA_REL_ "GenSigFirstTimeoutTime" BU_SG_REL_ TCM SG_ 391 ReqdLongDist_CRC 3000;
BA_REL_ "GenSigTimeoutTime" BU_SG_REL_ TCM SG_ 391 ReqdLongDist_CRC 120;
BA_REL_ "GenSigFirstTimeoutTime" BU_SG_REL_ TCM SG_ 391 ACC_Status_ISig_2 3000;
BA_REL_ "GenSigTimeoutTime" BU_SG_REL_ TCM SG_ 391 ACC_Status_ISig_2 120;
BA_REL_ "GenSigFirstTimeoutTime" BU_SG_REL_ ECM SG_ 391 ReqdLongSpd_AllwdBndUppr 3000;
BA_REL_ "GenSigTimeoutTime" BU_SG_REL_ ECM SG_ 391 ReqdLongSpd_AllwdBndUppr 120;
BA_REL_ "GenSigFirstTimeoutTime" BU_SG_REL_ TCM SG_ 391 ReqdLongSpd_AllwdBndUppr 3000;
BA_REL_ "GenSigTimeoutTime" BU_SG_REL_ TCM SG_ 391 ReqdLongSpd_AllwdBndUppr 120;
BA_REL_ "GenSigFirstTimeoutTime" BU_SG_REL_ ECM SG_ 391 XARDACU_AccelDemand 3000;
BA_REL_ "GenSigTimeoutTime" BU_SG_REL_ ECM SG_ 391 XARDACU_AccelDemand 120;
BA_REL_ "GenSigFirstTimeoutTime" BU_SG_REL_ TCM SG_ 391 XARDACU_AccelDemand 3000;
BA_REL_ "GenSigTimeoutTime" BU_SG_REL_ TCM SG_ 391 XARDACU_AccelDemand 120;
BA_REL_ "GenSigFirstTimeoutTime" BU_SG_REL_ ECM SG_ 391 SteeringValvePositionSetPoint 3000;
BA_REL_ "GenSigTimeoutTime" BU_SG_REL_ ECM SG_ 391 SteeringValvePositionSetPoint 120;
BA_REL_ "GenSigFirstTimeoutTime" BU_SG_REL_ TCM SG_ 391 ParkBrakeActuationStatus_ISig_2 3000;
BA_REL_ "GenSigTimeoutTime" BU_SG_REL_ TCM SG_ 391 ParkBrakeActuationStatus_ISig_2 120;
BA_REL_ "GenSigFirstTimeoutTime" BU_SG_REL_ ECM SG_ 391 GearLeverPosition_ISig_2 3000;
BA_REL_ "GenSigTimeoutTime" BU_SG_REL_ ECM SG_ 391 GearLeverPosition_ISig_2 500;
BA_REL_ "GenSigFirstTimeoutTime" BU_SG_REL_ TCM SG_ 391 GearLeverPosition_ISig_2 3000;
BA_REL_ "GenSigTimeoutTime" BU_SG_REL_ TCM SG_ 391 GearLeverPosition_ISig_2 120;
BA_REL_ "GenSigFirstTimeoutTime" BU_SG_REL_ ECM SG_ 391 EngineCrankRequest 3000;
BA_REL_ "GenSigTimeoutTime" BU_SG_REL_ ECM SG_ 391 EngineCrankRequest 120;
BA_REL_ "GenSigFirstTimeoutTime" BU_SG_REL_ TCM SG_ 391 RequestForHighestGearRatio 3000;
BA_REL_ "GenSigTimeoutTime" BU_SG_REL_ TCM SG_ 391 RequestForHighestGearRatio 120;
BA_REL_ "GenSigFirstTimeoutTime" BU_SG_REL_ ECM SG_ 391 XARDACU_ControlMode 3000;
BA_REL_ "GenSigTimeoutTime" BU_SG_REL_ ECM SG_ 391 XARDACU_ControlMode 120;
BA_REL_ "GenSigFirstTimeoutTime" BU_SG_REL_ TCM SG_ 391 XARDACU_ControlMode 3000;
BA_REL_ "GenSigTimeoutTime" BU_SG_REL_ TCM SG_ 391 XARDACU_ControlMode 120;
BA_REL_ "GenSigFirstTimeoutTime" BU_SG_REL_ ECM SG_ 391 EnginePreheat_rqst 3000;
BA_REL_ "GenSigTimeoutTime" BU_SG_REL_ ECM SG_ 391 EnginePreheat_rqst 120;
BA_REL_ "GenSigFirstTimeoutTime" BU_SG_REL_ TCM SG_ 391 ReqdLongAccel_CtrlMode 3000;
BA_REL_ "GenSigTimeoutTime" BU_SG_REL_ TCM SG_ 391 ReqdLongAccel_CtrlMode 120;
BA_REL_ "GenSigFirstTimeoutTime" BU_SG_REL_ ECM SG_ 391 ReqdLongAccel_CtrlMode 3000;
BA_REL_ "GenSigTimeoutTime" BU_SG_REL_ ECM SG_ 391 ReqdLongAccel_CtrlMode 120;
BA_REL_ "GenSigFirstTimeoutTime" BU_SG_REL_ TCM SG_ 391 ReqdLongDist_AllwdBndLowr 3000;
BA_REL_ "GenSigTimeoutTime" BU_SG_REL_ TCM SG_ 391 ReqdLongDist_AllwdBndLowr 120;
BA_REL_ "GenSigFirstTimeoutTime" BU_SG_REL_ TCM SG_ 391 ReqdLongSpd_Spd 3000;
BA_REL_ "GenSigTimeoutTime" BU_SG_REL_ TCM SG_ 391 ReqdLongSpd_Spd 120;
BA_REL_ "GenSigFirstTimeoutTime" BU_SG_REL_ ECM SG_ 391 ReqdLongSpd_Spd 3000;
BA_REL_ "GenSigTimeoutTime" BU_SG_REL_ ECM SG_ 391 ReqdLongSpd_Spd 120;
BA_REL_ "GenSigFirstTimeoutTime" BU_SG_REL_ TCM SG_ 391 ReqdLongSpd_AllwdBndLowr 3000;
BA_REL_ "GenSigTimeoutTime" BU_SG_REL_ TCM SG_ 391 ReqdLongSpd_AllwdBndLowr 120;
BA_REL_ "GenSigFirstTimeoutTime" BU_SG_REL_ ECM SG_ 391 ReqdLongSpd_AllwdBndLowr 3000;
BA_REL_ "GenSigTimeoutTime" BU_SG_REL_ ECM SG_ 391 ReqdLongSpd_AllwdBndLowr 120;
BA_REL_ "GenSigFirstTimeoutTime" BU_SG_REL_ TCM SG_ 391 ACCForwardVehicleSpeed 3000;
BA_REL_ "GenSigTimeoutTime" BU_SG_REL_ TCM SG_ 391 ACCForwardVehicleSpeed 120;
BA_REL_ "GenSigFirstTimeoutTime" BU_SG_REL_ TCM SG_ 391 ReqdLongDist_SqC 3000;
BA_REL_ "GenSigTimeoutTime" BU_SG_REL_ TCM SG_ 391 ReqdLongDist_SqC 120;
BA_REL_ "GenSigFirstTimeoutTime" BU_SG_REL_ ECM SG_ 391 ReqdLongAccel_Accel 3000;
BA_REL_ "GenSigTimeoutTime" BU_SG_REL_ ECM SG_ 391 ReqdLongAccel_Accel 120;
BA_REL_ "GenSigFirstTimeoutTime" BU_SG_REL_ TCM SG_ 391 ReqdLongAccel_Accel 3000;
BA_REL_ "GenSigTimeoutTime" BU_SG_REL_ TCM SG_ 391 ReqdLongAccel_Accel 120;
VAL_ 298 ReqTSC_CtrlMode 3 "TSC1EngOverrideCtrlMode_SpeedTorqueLimitControl" 2 "TSC1EngOverrideCtrlMode_TorqueControl" 1 "TSC1EngOverrideCtrlMode_SpeedControl" 0 "TSC1EngOverrideCtrlMode_OverrideDisabled" ;
VAL_ 568 EngSystPwrDwn_Rqst 3 "InactiveActive_NotAvailable" 2 "InactiveActive_Error" 1 "InactiveActive_Active" 0 "InactiveActive_Inactive" ;
VAL_ 568 EngCrnk_Rqst 3 "EngineCrankRequest_NotAvailable" 2 "EngineCrankRequest_Error" 1 "EngineCrankRequest_StartRequest" 0 "EngineCrankRequest_NoRequest" ;
VAL_ 568 SecuredNeutralPosition_ISig_2 3 "SecuredNeutralPosition_NotAvailable" 2 "SecuredNeutralPosition_Error" 1 "SecuredNeutralPosition_SecuredNeutralPosition" 0 "SecuredNeutralPosition_NotInSecuredNeutralPosition" ;
VAL_ 568 TransmLowRangeSenseSwitch_ISig_2 3 "OffOn_NotAvailable" 2 "OffOn_Error" 1 "OffOn_On" 0 "OffOn_Off" ;
VAL_ 568 TrnsmSystPwrDwn_Rqst 3 "TransmSystemPowerDown_rqst_DontCare" 2 "TransmSystemPowerDown_rqst_NotDefined" 1 "TransmSystemPowerDown_rqst_PowerDownRequestActive" 0 "TransmSystemPowerDown_rqst_PowerDownRequestInactive" ;
VAL_ 568 FrontAxleInBumperRange_ISig_2 3 "AxleInBumperRange_NotAvailable" 2 "AxleInBumperRange_ErrorIndicator" 1 "AxleInBumperRange_ActualLevelWithinBumperRange" 0 "AxleInBumperRange_ActualLevelOutOfBumperRange" ;
VAL_ 568 RollerBenchModeRequest_ISig_2 3 "OffOn_NotAvailable" 2 "OffOn_Error" 1 "OffOn_On" 0 "OffOn_Off" ;
VAL_ 568 EcnmyPwrSwt_Sts 3 "OffOn_NotAvailable" 2 "OffOn_Error" 1 "OffOn_On" 0 "OffOn_Off" ;
VAL_ 568 RearAxleInBumperRange_ISig_2 3 "AxleInBumperRange_NotAvailable" 2 "AxleInBumperRange_ErrorIndicator" 1 "AxleInBumperRange_ActualLevelWithinBumperRange" 0 "AxleInBumperRange_ActualLevelOutOfBumperRange" ;
VAL_ 568 TractionControlDriverRqst_ISig_2 7 "TractionControlDriverRqst_NotAvailable" 6 "TractionControlDriverRqst_Error" 5 "TractionControlDriverRqst_Spare_01" 4 "TractionControlDriverRqst_Spare" 3 "TractionControlDriverRqst_TractionOFFROAD" 2 "TractionControlDriverRqst_TractionOFF" 1 "TractionControlDriverRqst_TractionON" 0 "TractionControlDriverRqst_NoAction" ;
VAL_ 568 TransmissionNeutralSwitch 3 "TransmissionNeutralSwitch_NotAvailable" 2 "TransmissionNeutralSwitch_Error" 1 "TransmissionNeutralSwitch_TransmissionInNeutral" 0 "TransmissionNeutralSwitch_TransmissionNotInNeutral" ;
VAL_ 568 ReverseGearEngaged_ISig_2 3 "ReverseGearEngaged_NotAvailable" 2 "ReverseGearEngaged_Error" 1 "ReverseGearEngaged_ReverseGearEngaged" 0 "ReverseGearEngaged_ReverseGearNotEngaged" ;
VAL_ 568 GearLeverPosition2_Rqst 15 "GearLeverPosition_NotAvailable" 14 "GearLeverPosition_Error" 13 "GearLeverPosition_SpareValue_06" 12 "GearLeverPosition_SpareValue_05" 11 "GearLeverPosition_SpareValue_04" 10 "GearLeverPosition_SpareValue_03" 9 "GearLeverPosition_SpareValue_02" 8 "GearLeverPosition_SpareValue_01" 7 "GearLeverPosition_SpareValue" 6 "GearLeverPosition_SEG6" 5 "GearLeverPosition_LowGear" 4 "GearLeverPosition_Manual" 3 "GearLeverPosition_Automatic" 2 "GearLeverPosition_Neutral" 1 "GearLeverPosition_Reverse" 0 "GearLeverPosition_GearFoldedAway" ;
VAL_ 568 UpDownShiftRqst_Rqst 15 "UpDownShiftRequest_NotAvailable" 14 "UpDownShiftRequest_Error" 13 "UpDownShiftRequest_Spare7" 12 "UpDownShiftRequest_Spare6" 11 "UpDownShiftRequest_Spare5" 10 "UpDownShiftRequest_Spare4" 9 "UpDownShiftRequest_Spare3" 8 "UpDownShiftRequest_Spare2" 7 "UpDownShiftRequest_Spare1" 6 "UpDownShiftRequest_DownShiftThreeSteps" 5 "UpDownShiftRequest_DownShiftTwoSteps" 4 "UpDownShiftRequest_DownShiftOneStep" 3 "UpDownShiftRequest_UpShiftThreeSteps" 2 "UpDownShiftRequest_UpShiftTwoSteps" 1 "UpDownShiftRequest_UpShiftOneStep" 0 "UpDownShiftRequest_NoRequest" ;
VAL_ 568 LevelControlInformation_ISig_2 15 "LevelControlInformation_NotAvailable" 14 "LevelControlInformation_Error" 13 "LevelControlInformation_Reserved_06" 12 "LevelControlInformation_Reserved_05" 11 "LevelControlInformation_Reserved_04" 10 "LevelControlInformation_Reserved_03" 9 "LevelControlInformation_Reserved_02" 8 "LevelControlInformation_Reserved_01" 7 "LevelControlInformation_Reserved" 6 "LevelControlInformation_LimpHome" 5 "LevelControlInformation_FerryFunction" 4 "LevelControlInformation_KneelingHeight" 3 "LevelControlInformation_DriveHeight" 2 "LevelControlInformation_DockingHeight" 1 "LevelControlInformation_HeightAdjustment" 0 "LevelControlInformation_Prohibit" ;
VAL_ 568 DriveModeSwitchStat_Rqst 3 "OffOn_NotAvailable" 2 "OffOn_Error" 1 "OffOn_On" 0 "OffOn_Off" ;
VAL_ 1563 MIStatusExtVMCU 3 "MIStatusExt_NotAvailable" 2 "MIStatusExt_Error" 1 "MIStatusExt_Ready" 0 "MIStatusExt_NotReady5Flash" ;
VAL_ 1563 MIStatusVMCU 3 "OffOn_NotAvailable" 2 "OffOn_Error" 1 "OffOn_On" 0 "OffOn_Off" ;
VAL_ 1563 MIDistinctWarningExtVMCU 15 "MIDistinctWarningExt_NotAvailable" 14 "MIDistinctWarningExt_Error" 3 "MIDistinctWarningExt_ContinuousMISteady" 2 "MIDistinctWarningExt_ShortMI3Flash" 1 "MIDistinctWarningExt_OnDemandMI2Flash" 0 "MIDistinctWarningExt_Off1Flash" ;
VAL_ 1563 MIDistinctWarningVMCU 3 "OffOn_NotAvailable" 2 "OffOn_Error" 1 "OffOn_On" 0 "OffOn_Off" ;
VAL_ 1308 DPF_ManualRegenerateRequest_ISig 3 "Request_NotAvailable" 2 "Request_Error" 1 "Request_RequestActive" 0 "Request_NotRequested" ;
VAL_ 1308 DPF_ManualRegenerateInhibit_ISig 3 "InactiveActive_NotAvailable" 2 "InactiveActive_Error" 1 "InactiveActive_Active" 0 "InactiveActive_Inactive" ;
VAL_ 1308 WaterInFuelDrainRequest_ISig_2 3 "Request_NotAvailable" 2 "Request_Error" 1 "Request_RequestActive" 0 "Request_NotRequested" ;
VAL_ 1308 HillDataCtrlTGW_State 7 "HillDataState_NotAvailable" 6 "HillDataState_Error" 5 "HillDataState_Spare_03" 4 "HillDataState_Spare_02" 3 "HillDataState_Spare_01" 2 "HillDataState_Receive" 1 "HillDataState_Request" 0 "HillDataState_Idle" ;
VAL_ 1308 DPF_ManualRegenerateTimeReq_ISig 3 "NotRequested_NotAvailable" 2 "NotRequested_Error" 1 "NotRequested_Requested" 0 "NotRequested_NotRequested" ;
VAL_ 1185 SavedHeightControlMode_ISig_2 3 "SavedHeightControlMode_NotAvailable" 2 "SavedHeightControlMode_Error" 1 "SavedHeightControlMode_Drive" 0 "SavedHeightControlMode_Manual" ;
VAL_ 1185 SpeedAdaptEnableRqst_SpeedLimit_ 3 "Selected_NotAvailable" 2 "Selected_Error" 1 "Selected_Selected" 0 "Selected_NotSelected" ;
VAL_ 1185 SpeedAdaptEnableRqst_Curve_ISig_ 3 "Selected_NotAvailable" 2 "Selected_Error" 1 "Selected_Selected" 0 "Selected_NotSelected" ;
VAL_ 1185 SpeedAdaptEnableRqst_SlowTraffic 3 "Selected_NotAvailable" 2 "Selected_Error" 1 "Selected_Selected" 0 "Selected_NotSelected" ;
VAL_ 1060 EngOvrrideCtrlStat_FireTruckMode 3 "FireTruckMode_Spare4" 2 "FireTruckMode_Spare3" 1 "FireTruckMode_Spare2" 0 "FireTruckMode_Spare1" ;
VAL_ 1060 EngOvrrideCtrlStat_ProtOvrrMode 3 "InactiveActive_NotAvailable" 2 "InactiveActive_Error" 1 "InactiveActive_Active" 0 "InactiveActive_Inactive" ;
VAL_ 1060 EngOvrrideCtrlStat_StartOvrrMode 3 "InactiveActive_NotAvailable" 2 "InactiveActive_Error" 1 "InactiveActive_Active" 0 "InactiveActive_Inactive" ;
VAL_ 1060 EngineAirShutOffCommandStatus 3 "NotActiveActive_NotAvailable" 2 "NotActiveActive_Error" 1 "NotActiveActive_Active" 0 "NotActiveActive_NotActive" ;
VAL_ 932 SelfStartAssist_stat_ISig_2 3 "SelfStartAssist_stat_NotAvailable" 2 "SelfStartAssist_stat_Requested_Initiated" 1 "SelfStartAssist_stat_Ready" 0 "SelfStartAssist_stat_NotRequested" ;
VAL_ 932 EcoRollEnableRequest_ISig_2 3 "InactiveActive_NotAvailable" 2 "InactiveActive_Error" 1 "InactiveActive_Active" 0 "InactiveActive_Inactive" ;
VAL_ 932 SelectedEcoCruiseLevel 7 "SelectedEcoCruiseLevel_NotAvailable" 6 "SelectedEcoCruiseLevel_Error" 5 "SelectedEcoCruiseLevel_Spare01" 4 "SelectedEcoCruiseLevel_Spare" 3 "SelectedEcoCruiseLevel_Level3" 2 "SelectedEcoCruiseLevel_Level2" 1 "SelectedEcoCruiseLevel_Level1" 0 "SelectedEcoCruiseLevel_Off" ;
VAL_ 932 ACCiRollInhibit 3 "Inhibit_NotAvailable" 2 "Inhibit_Error" 1 "Inhibit_InhibitActive" 0 "Inhibit_NoInhibit" ;
VAL_ 932 ReqdDrvgMode 15 "ReqdDrvgMode_NotAvailable" 14 "ReqdDrvgMode_Error" 13 "ReqdDrvgMode_Spare7" 12 "ReqdDrvgMode_Spare6" 11 "ReqdDrvgMode_Spare5" 10 "ReqdDrvgMode_Spare4" 9 "ReqdDrvgMode_Spare3" 8 "ReqdDrvgMode_Spare2" 7 "ReqdDrvgMode_Spare1" 6 "ReqdDrvgMode_KickDown" 5 "ReqdDrvgMode_HeavyDuty" 4 "ReqdDrvgMode_OffRoad" 3 "ReqdDrvgMode_Performance" 2 "ReqdDrvgMode_Balanced" 1 "ReqdDrvgMode_EconomyExtra" 0 "ReqdDrvgMode_None" ;
VAL_ 932 ParkBrake_OBDState 3 "ParkBrakeState_NotAvailable" 2 "ParkBrakeState_Error" 1 "ParkBrakeState_Parked" 0 "ParkBrakeState_Released" ;
VAL_ 932 AltParallelOperation 3 "DisableEnable_NotAvailable" 2 "DisableEnable_Error" 1 "DisableEnable_Enable" 0 "DisableEnable_Disable" ;
VAL_ 932 AltLR_cut_offSpeed 31 "AltLR_cut_offSpeed5bit_NotAvailable" 30 "AltLR_cut_offSpeed5bit_Error" 29 "AltLR_cut_offSpeed5bit_Spare14" 28 "AltLR_cut_offSpeed5bit_Spare13" 27 "AltLR_cut_offSpeed5bit_Spare12" 26 "AltLR_cut_offSpeed5bit_Spare11" 25 "AltLR_cut_offSpeed5bit_Spare10" 24 "AltLR_cut_offSpeed5bit_Spare09" 23 "AltLR_cut_offSpeed5bit_Spare08" 22 "AltLR_cut_offSpeed5bit_Spare07" 21 "AltLR_cut_offSpeed5bit_Spare06" 20 "AltLR_cut_offSpeed5bit_Spare05" 19 "AltLR_cut_offSpeed5bit_Spare04" 18 "AltLR_cut_offSpeed5bit_Spare03" 17 "AltLR_cut_offSpeed5bit_Spare02" 16 "AltLR_cut_offSpeed5bit_Spare01" 15 "AltLR_cut_offSpeed5bit_AlwaysActive" 14 "AltLR_cut_offSpeed5bit_6000rpm" 13 "AltLR_cut_offSpeed5bit_4800rpm" 12 "AltLR_cut_offSpeed5bit_4000rpm" 11 "AltLR_cut_offSpeed5bit_3690rpm" 10 "AltLR_cut_offSpeed5bit_3430rpm" 9 "AltLR_cut_offSpeed5bit_3200rpm" 8 "AltLR_cut_offSpeed5bit_3000rpm" 7 "AltLR_cut_offSpeed5bit_2820rpm" 6 "AltLR_cut_offSpeed5bit_2670rpm" 5 "AltLR_cut_offSpeed5bit_2530rpm" 4 "AltLR_cut_offSpeed5bit_2400rpm" 3 "AltLR_cut_offSpeed5bit_2290rpm" 2 "AltLR_cut_offSpeed5bit_2180rpm" 1 "AltLR_cut_offSpeed5bit_2090rpm" 0 "AltLR_cut_offSpeed5bit_2000rpm" ;
VAL_ 932 MaintOilQuality 7 "OilQuality_NotAvailable" 6 "OilQuality_Error" 5 "OilQuality_NoSelectionMade" 4 "OilQuality_VDS4" 3 "OilQuality_VDS3" 2 "OilQuality_VDS5" 1 "OilQuality_VDSVDS3WithFixedInterval" 0 "OilQuality_NonVDS_VDS4WithFixedInterval" ;
VAL_ 932 ReqdEcoRoll 3 "OffOn_NotAvailable" 2 "OffOn_Error" 1 "OffOn_On" 0 "OffOn_Off" ;
VAL_ 932 ReqdVehLongCtrlM_Mode 7 "ReqdVehLongCtrlMode_NotAvailable" 6 "ReqdVehLongCtrlMode_Error" 5 "ReqdVehLongCtrlMode_Spare2" 4 "ReqdVehLongCtrlMode_Spare1" 3 "ReqdVehLongCtrlMode_Distance" 2 "ReqdVehLongCtrlMode_Speed" 1 "ReqdVehLongCtrlMode_Acceleration" 0 "ReqdVehLongCtrlMode_Off" ;
VAL_ 932 SpeedAdaptationLevelRqst_ISig_2 7 "LowMidHigh_NotAvailable" 6 "LowMidHigh_Error" 5 "LowMidHigh_Spare3" 4 "LowMidHigh_Spare2" 3 "LowMidHigh_Spare1" 2 "LowMidHigh_High" 1 "LowMidHigh_Mid" 0 "LowMidHigh_Low" ;
VAL_ 932 RSLAssistStatus 7 "RSLAssistStatus_NotAvailable" 6 "RSLAssistStatus_Error" 5 "RSLAssistStatus_Spare2" 4 "RSLAssistStatus_Spare1" 3 "RSLAssistStatus_PreActive" 2 "RSLAssistStatus_Active" 1 "RSLAssistStatus_Enable" 0 "RSLAssistStatus_Disable" ;
VAL_ 932 CruiseControlStates 7 "CruiseControlStates_NotAvailable" 6 "CruiseControlStates_AcceleratorOverride" 5 "CruiseControlStates_Set" 4 "CruiseControlStates_Resume" 3 "CruiseControlStates_Decelerate" 2 "CruiseControlStates_Accelerate" 1 "CruiseControlStates_Hold" 0 "CruiseControlStates_OffDisabled" ;
VAL_ 932 AltDataSelectionWordRx 15 "AltMultiplexSelectedInfo_NotAvailable" 14 "AltMultiplexSelectedInfo_Error" 13 "AltMultiplexSelectedInfo_Spare6" 12 "AltMultiplexSelectedInfo_Spare5" 11 "AltMultiplexSelectedInfo_Spare4" 10 "AltMultiplexSelectedInfo_Spare3" 9 "AltMultiplexSelectedInfo_Spare2" 8 "AltMultiplexSelectedInfo_Spare1" 7 "AltMultiplexSelectedInfo_0x00_3" 6 "AltMultiplexSelectedInfo_ReservedForManufacturer" 5 "AltMultiplexSelectedInfo_0x00_2" 4 "AltMultiplexSelectedInfo_NGen" 3 "AltMultiplexSelectedInfo_IC_temperature" 2 "AltMultiplexSelectedInfo_VoltageMeasured" 1 "AltMultiplexSelectedInfo_VoltageSet" 0 "AltMultiplexSelectedInfo_0x00_1" ;
VAL_ 932 ClutchSwitch_ISig_2 3 "ClutchSwitch_NotAvailable" 2 "ClutchSwitch_Error" 1 "ClutchSwitch_ClutchPedalDepressed" 0 "ClutchSwitch_ClutchPedalReleased" ;
VAL_ 932 ReqdSGoMode_Mode 15 "ACC_SGO_Status_NotAvailable" 14 "ACC_SGO_Status_Error" 13 "ACC_SGO_Status_Spare7" 12 "ACC_SGO_Status_Spare6" 11 "ACC_SGO_Status_Spare5" 10 "ACC_SGO_Status_Spare4" 9 "ACC_SGO_Status_Spare3" 8 "ACC_SGO_Status_Spare2" 7 "ACC_SGO_Status_Spare1" 6 "ACC_SGO_Status_ACC_SGO_Active_TakeOffRequest" 5 "ACC_SGO_Status_ACC_SGO_Active_Hold" 4 "ACC_SGO_Status_ACC_SGO_Active_Stationary" 3 "ACC_SGO_Status_ACC_SGO_Stopping" 2 "ACC_SGO_Status_ACC_SGO_Active_Driving" 1 "ACC_SGO_Status_ACC_SGO_Inactive" 0 "ACC_SGO_Status_ACC_SGO_OFF" ;
VAL_ 932 MaintOilReset 3 "Request_NotAvailable" 2 "Request_Error" 1 "Request_RequestActive" 0 "Request_NotRequested" ;
VAL_ 932 AltLR_RampTime 31 "AltLR_RampTime5bit_NotAvailable" 30 "AltLR_RampTime5bit_Error" 29 "AltLR_RampTime5bit_Spare14" 28 "AltLR_RampTime5bit_Spare13" 27 "AltLR_RampTime5bit_Spare12" 26 "AltLR_RampTime5bit_Spare11" 25 "AltLR_RampTime5bit_Spare10" 24 "AltLR_RampTime5bit_Spare09" 23 "AltLR_RampTime5bit_Spare08" 22 "AltLR_RampTime5bit_Spare07" 21 "AltLR_RampTime5bit_Spare06" 20 "AltLR_RampTime5bit_Spare05" 19 "AltLR_RampTime5bit_Spare04" 18 "AltLR_RampTime5bit_Spare03" 17 "AltLR_RampTime5bit_Spare02" 16 "AltLR_RampTime5bit_Spare01" 15 "AltLR_RampTime5bit_15s" 14 "AltLR_RampTime5bit_12s" 13 "AltLR_RampTime5bit_10s" 12 "AltLR_RampTime5bit_9s" 11 "AltLR_RampTime5bit_8s" 10 "AltLR_RampTime5bit_7s" 9 "AltLR_RampTime5bit_6s" 8 "AltLR_RampTime5bit_5s" 7 "AltLR_RampTime5bit_4s" 6 "AltLR_RampTime5bit_3s" 5 "AltLR_RampTime5bit_2s" 4 "AltLR_RampTime5bit_1s" 3 "AltLR_RampTime5bit_0_75s" 2 "AltLR_RampTime5bit_0_5s" 1 "AltLR_RampTime5bit_0_25s" 0 "AltLR_RampTime5bit_Off_0" ;
VAL_ 932 ReqdDrvgDir_Direction 7 "RequestedDrivingDirection_NotAvailable" 6 "RequestedDrivingDirection_Error" 5 "RequestedDrivingDirection_Spare2" 4 "RequestedDrivingDirection_Spare1" 3 "RequestedDrivingDirection_Forward" 2 "RequestedDrivingDirection_Neutral" 1 "RequestedDrivingDirection_Reverse" 0 "RequestedDrivingDirection_Parked" ;
VAL_ 932 CACCStatus_ISig_2 7 "CACCStatus_NotAvailable" 6 "CACCStatus_Error" 5 "CACCStatus_Spare3" 4 "CACCStatus_Spare2" 3 "CACCStatus_Spare1" 2 "CACCStatus_Active" 1 "CACCStatus_Available" 0 "CACCStatus_Unavailable" ;
VAL_ 1066 TrafficSitSpdProfile_PathIndex 63 "PathIndex_Index63" 62 "PathIndex_Index62" 61 "PathIndex_Index61" 60 "PathIndex_Index60" 59 "PathIndex_Index59" 58 "PathIndex_Index58" 57 "PathIndex_Index57" 56 "PathIndex_Index56" 55 "PathIndex_Index55" 54 "PathIndex_Index54" 53 "PathIndex_Index53" 52 "PathIndex_Index52" 51 "PathIndex_Index51" 50 "PathIndex_Index50" 49 "PathIndex_Index49" 48 "PathIndex_Index48" 47 "PathIndex_Index47" 46 "PathIndex_Index46" 45 "PathIndex_Index45" 44 "PathIndex_Index44" 43 "PathIndex_Index43" 42 "PathIndex_Index42" 41 "PathIndex_Index41" 40 "PathIndex_Index40" 39 "PathIndex_Index39" 38 "PathIndex_Index38" 37 "PathIndex_Index37" 36 "PathIndex_Index36" 35 "PathIndex_Index35" 34 "PathIndex_Index34" 33 "PathIndex_Index33" 32 "PathIndex_Index32" 31 "PathIndex_Index31" 30 "PathIndex_Index30" 29 "PathIndex_Index29" 28 "PathIndex_Index28" 27 "PathIndex_Index27" 26 "PathIndex_Index26" 25 "PathIndex_Index25" 24 "PathIndex_Index24" 23 "PathIndex_Index23" 22 "PathIndex_Index22" 21 "PathIndex_Index21" 20 "PathIndex_Index20" 19 "PathIndex_Index19" 18 "PathIndex_Index18" 17 "PathIndex_Index17" 16 "PathIndex_Index16" 15 "PathIndex_Index15" 14 "PathIndex_Index14" 13 "PathIndex_Index13" 12 "PathIndex_Index12" 11 "PathIndex_Index11" 10 "PathIndex_Index10" 9 "PathIndex_Index9" 8 "PathIndex_Index8" 7 "PathIndex_DoNotUse4" 6 "PathIndex_DoNotUse3" 5 "PathIndex_DoNotUse2" 4 "PathIndex_DoNotUse1" 3 "PathIndex_PositionSignalInvalid" 2 "PathIndex_NotOnRoad" 1 "PathIndex_NoMapDataOnBoard" 0 "PathIndex_DoNotUse" ;
VAL_ 1066 TrafficSitSpdProfile_Type 255 "TrafficSitEventType_NotAvailable" 254 "TrafficSitEventType_Error" 253 "TrafficSitEventType_NotUsed3" 252 "TrafficSitEventType_NotUsed2" 251 "TrafficSitEventType_NotUsed1" 250 "TrafficSitEventType_GeneralEvent" 249 "TrafficSitEventType_spare242" 248 "TrafficSitEventType_spare241" 247 "TrafficSitEventType_spare240" 246 "TrafficSitEventType_spare239" 245 "TrafficSitEventType_spare238" 244 "TrafficSitEventType_spare237" 243 "TrafficSitEventType_spare236" 242 "TrafficSitEventType_spare235" 241 "TrafficSitEventType_spare234" 240 "TrafficSitEventType_spare233" 239 "TrafficSitEventType_spare232" 238 "TrafficSitEventType_spare231" 237 "TrafficSitEventType_spare230" 236 "TrafficSitEventType_spare229" 235 "TrafficSitEventType_spare228" 234 "TrafficSitEventType_spare227" 233 "TrafficSitEventType_spare226" 232 "TrafficSitEventType_spare225" 231 "TrafficSitEventType_spare224" 230 "TrafficSitEventType_spare223" 229 "TrafficSitEventType_spare222" 228 "TrafficSitEventType_spare221" 227 "TrafficSitEventType_spare220" 226 "TrafficSitEventType_spare219" 225 "TrafficSitEventType_spare218" 224 "TrafficSitEventType_spare217" 223 "TrafficSitEventType_spare216" 222 "TrafficSitEventType_spare215" 221 "TrafficSitEventType_spare214" 220 "TrafficSitEventType_spare213" 219 "TrafficSitEventType_spare212" 218 "TrafficSitEventType_spare211" 217 "TrafficSitEventType_spare210" 216 "TrafficSitEventType_spare209" 215 "TrafficSitEventType_spare208" 214 "TrafficSitEventType_spare207" 213 "TrafficSitEventType_spare206" 212 "TrafficSitEventType_spare205" 211 "TrafficSitEventType_spare204" 210 "TrafficSitEventType_spare203" 209 "TrafficSitEventType_spare202" 208 "TrafficSitEventType_spare201" 207 "TrafficSitEventType_spare200" 206 "TrafficSitEventType_spare199" 205 "TrafficSitEventType_spare198" 204 "TrafficSitEventType_spare197" 203 "TrafficSitEventType_spare196" 202 "TrafficSitEventType_spare195" 201 "TrafficSitEventType_spare194" 200 "TrafficSitEventType_spare193" 199 "TrafficSitEventType_spare192" 198 "TrafficSitEventType_spare191" 197 "TrafficSitEventType_spare190" 196 "TrafficSitEventType_spare189" 195 "TrafficSitEventType_spare188" 194 "TrafficSitEventType_spare187" 193 "TrafficSitEventType_spare186" 192 "TrafficSitEventType_spare185" 191 "TrafficSitEventType_spare184" 190 "TrafficSitEventType_spare183" 189 "TrafficSitEventType_spare182" 188 "TrafficSitEventType_spare181" 187 "TrafficSitEventType_spare180" 186 "TrafficSitEventType_spare179" 185 "TrafficSitEventType_spare178" 184 "TrafficSitEventType_spare177" 183 "TrafficSitEventType_spare176" 182 "TrafficSitEventType_spare175" 181 "TrafficSitEventType_spare174" 180 "TrafficSitEventType_spare173" 179 "TrafficSitEventType_spare172" 178 "TrafficSitEventType_spare171" 177 "TrafficSitEventType_spare170" 176 "TrafficSitEventType_spare169" 175 "TrafficSitEventType_spare168" 174 "TrafficSitEventType_spare167" 173 "TrafficSitEventType_spare166" 172 "TrafficSitEventType_spare165" 171 "TrafficSitEventType_spare164" 170 "TrafficSitEventType_spare163" 169 "TrafficSitEventType_spare162" 168 "TrafficSitEventType_spare161" 167 "TrafficSitEventType_spare160" 166 "TrafficSitEventType_spare159" 165 "TrafficSitEventType_spare158" 164 "TrafficSitEventType_spare157" 163 "TrafficSitEventType_spare156" 162 "TrafficSitEventType_spare155" 161 "TrafficSitEventType_spare154" 160 "TrafficSitEventType_spare153" 159 "TrafficSitEventType_spare152" 158 "TrafficSitEventType_spare151" 157 "TrafficSitEventType_spare150" 156 "TrafficSitEventType_spare149" 155 "TrafficSitEventType_spare148" 154 "TrafficSitEventType_spare147" 153 "TrafficSitEventType_spare146" 152 "TrafficSitEventType_spare145" 151 "TrafficSitEventType_spare144" 150 "TrafficSitEventType_spare143" 149 "TrafficSitEventType_spare142" 148 "TrafficSitEventType_spare141" 147 "TrafficSitEventType_spare140" 146 "TrafficSitEventType_spare139" 145 "TrafficSitEventType_spare138" 144 "TrafficSitEventType_spare137" 143 "TrafficSitEventType_spare136" 142 "TrafficSitEventType_spare135" 141 "TrafficSitEventType_spare134" 140 "TrafficSitEventType_spare133" 139 "TrafficSitEventType_spare132" 138 "TrafficSitEventType_spare131" 137 "TrafficSitEventType_spare130" 136 "TrafficSitEventType_spare129" 135 "TrafficSitEventType_spare128" 134 "TrafficSitEventType_spare127" 133 "TrafficSitEventType_spare126" 132 "TrafficSitEventType_spare125" 131 "TrafficSitEventType_spare124" 130 "TrafficSitEventType_spare123" 129 "TrafficSitEventType_spare122" 128 "TrafficSitEventType_spare121" 127 "TrafficSitEventType_spare120" 126 "TrafficSitEventType_spare119" 125 "TrafficSitEventType_spare118" 124 "TrafficSitEventType_spare117" 123 "TrafficSitEventType_spare116" 122 "TrafficSitEventType_spare115" 121 "TrafficSitEventType_spare114" 120 "TrafficSitEventType_spare113" 119 "TrafficSitEventType_spare112" 118 "TrafficSitEventType_spare111" 117 "TrafficSitEventType_spare110" 116 "TrafficSitEventType_spare109" 115 "TrafficSitEventType_spare108" 114 "TrafficSitEventType_spare107" 113 "TrafficSitEventType_spare106" 112 "TrafficSitEventType_spare105" 111 "TrafficSitEventType_spare104" 110 "TrafficSitEventType_spare103" 109 "TrafficSitEventType_spare102" 108 "TrafficSitEventType_spare101" 107 "TrafficSitEventType_spare100" 106 "TrafficSitEventType_spare99" 105 "TrafficSitEventType_spare98" 104 "TrafficSitEventType_spare97" 103 "TrafficSitEventType_spare96" 102 "TrafficSitEventType_spare95" 101 "TrafficSitEventType_spare94" 100 "TrafficSitEventType_spare93" 99 "TrafficSitEventType_spare92" 98 "TrafficSitEventType_spare91" 97 "TrafficSitEventType_spare90" 96 "TrafficSitEventType_spare89" 95 "TrafficSitEventType_spare88" 94 "TrafficSitEventType_spare87" 93 "TrafficSitEventType_spare86" 92 "TrafficSitEventType_spare85" 91 "TrafficSitEventType_spare84" 90 "TrafficSitEventType_spare83" 89 "TrafficSitEventType_spare82" 88 "TrafficSitEventType_spare81" 87 "TrafficSitEventType_spare80" 86 "TrafficSitEventType_spare79" 85 "TrafficSitEventType_spare78" 84 "TrafficSitEventType_spare77" 83 "TrafficSitEventType_spare76" 82 "TrafficSitEventType_spare75" 81 "TrafficSitEventType_spare74" 80 "TrafficSitEventType_spare73" 79 "TrafficSitEventType_spare72" 78 "TrafficSitEventType_spare71" 77 "TrafficSitEventType_spare70" 76 "TrafficSitEventType_spare69" 75 "TrafficSitEventType_spare68" 74 "TrafficSitEventType_spare67" 73 "TrafficSitEventType_spare66" 72 "TrafficSitEventType_spare65" 71 "TrafficSitEventType_spare64" 70 "TrafficSitEventType_spare63" 69 "TrafficSitEventType_spare62" 68 "TrafficSitEventType_spare61" 67 "TrafficSitEventType_spare60" 66 "TrafficSitEventType_spare59" 65 "TrafficSitEventType_spare58" 64 "TrafficSitEventType_spare57" 63 "TrafficSitEventType_spare56" 62 "TrafficSitEventType_spare55" 61 "TrafficSitEventType_spare54" 60 "TrafficSitEventType_spare53" 59 "TrafficSitEventType_spare52" 58 "TrafficSitEventType_spare51" 57 "TrafficSitEventType_spare50" 56 "TrafficSitEventType_spare49" 55 "TrafficSitEventType_spare48" 54 "TrafficSitEventType_spare47" 53 "TrafficSitEventType_spare46" 52 "TrafficSitEventType_spare45" 51 "TrafficSitEventType_spare44" 50 "TrafficSitEventType_spare43" 49 "TrafficSitEventType_spare42" 48 "TrafficSitEventType_spare41" 47 "TrafficSitEventType_spare40" 46 "TrafficSitEventType_spare39" 45 "TrafficSitEventType_spare38" 44 "TrafficSitEventType_spare37" 43 "TrafficSitEventType_spare36" 42 "TrafficSitEventType_spare35" 41 "TrafficSitEventType_spare34" 40 "TrafficSitEventType_spare33" 39 "TrafficSitEventType_spare32" 38 "TrafficSitEventType_spare31" 37 "TrafficSitEventType_spare30" 36 "TrafficSitEventType_spare29" 35 "TrafficSitEventType_spare28" 34 "TrafficSitEventType_spare27" 33 "TrafficSitEventType_spare26" 32 "TrafficSitEventType_spare25" 31 "TrafficSitEventType_spare24" 30 "TrafficSitEventType_spare23" 29 "TrafficSitEventType_spare22" 28 "TrafficSitEventType_spare21" 27 "TrafficSitEventType_spare20" 26 "TrafficSitEventType_spare19" 25 "TrafficSitEventType_spare18" 24 "TrafficSitEventType_spare17" 23 "TrafficSitEventType_spare16" 22 "TrafficSitEventType_spare15" 21 "TrafficSitEventType_spare14" 20 "TrafficSitEventType_spare13" 19 "TrafficSitEventType_spare12" 18 "TrafficSitEventType_spare11" 17 "TrafficSitEventType_spare10" 16 "TrafficSitEventType_spare9" 15 "TrafficSitEventType_spare8" 14 "TrafficSitEventType_spare7" 13 "TrafficSitEventType_spare6" 12 "TrafficSitEventType_spare5" 11 "TrafficSitEventType_spare4" 10 "TrafficSitEventType_spare3" 9 "TrafficSitEventType_spare2" 8 "TrafficSitEventType_spare1" 7 "TrafficSitEventType_NarrowRoad" 6 "TrafficSitEventType_TrafficJam_OR_SlowTraffic" 5 "TrafficSitEventType_Crossing" 4 "TrafficSitEventType_Roundabout" 3 "TrafficSitEventType_CurveRight" 2 "TrafficSitEventType_CurveLeft" 1 "TrafficSitEventType_SpeedLimit" 0 "TrafficSitEventType_NoEvent" ;
VAL_ 300 AccPedal_Qlty 3 "PrimaryAcceleratorPedalQuality_NotAvailable" 2 "PrimaryAcceleratorPedalQuality_ErrorMode" 1 "PrimaryAcceleratorPedalQuality_DowngradedMode" 0 "PrimaryAcceleratorPedalQuality_NormalMode" ;
VAL_ 1246 StarterMotorReset_rqst 3 "Request_NotAvailable" 2 "Request_Error" 1 "Request_RequestActive" 0 "Request_NotRequested" ;
VAL_ 746 Pto1ConsentRequest 3 "PtoConsentRequest_NotAvailable" 2 "PtoConsentRequest_Error" 1 "PtoConsentRequest_PTOOperationDesired" 0 "PtoConsentRequest_PTOOperationNotDesired" ;
VAL_ 746 SecondThrottle 3 "InactiveActive_NotAvailable" 2 "InactiveActive_Error" 1 "InactiveActive_Active" 0 "InactiveActive_Inactive" ;
VAL_ 746 TransferCaseOrSplitboxPTOMode_IS 3 "InactiveActive_NotAvailable" 2 "InactiveActive_Error" 1 "InactiveActive_Active" 0 "InactiveActive_Inactive" ;
VAL_ 746 PtosStatus_ISig_2 3 "PtosStatus_NotAvailable" 2 "PtosStatus_Error" 1 "PtosStatus_OneOrMorePTOEngaged" 0 "PtosStatus_NoPTOEngaged" ;
VAL_ 746 ConstructionSwitch_stat 3 "OffOn_NotAvailable" 2 "OffOn_Error" 1 "OffOn_On" 0 "OffOn_Off" ;
VAL_ 746 RegenInhibitVehicleHeight_ISig_2 3 "ActiveStatus_NotAvailable" 2 "ActiveStatus_Error" 1 "ActiveStatus_Active" 0 "ActiveStatus_NotActive" ;
VAL_ 746 PtoRequest 3 "InactiveActive_NotAvailable" 2 "InactiveActive_Error" 1 "InactiveActive_Active" 0 "InactiveActive_Inactive" ;
VAL_ 746 Pto2Status_ISig_2 3 "InactiveActive_NotAvailable" 2 "InactiveActive_Error" 1 "InactiveActive_Active" 0 "InactiveActive_Inactive" ;
VAL_ 746 TrailerConnected_ISig_2 3 "NoYes_NotAvailable" 2 "NoYes_Error" 1 "NoYes_Yes" 0 "NoYes_No" ;
VAL_ 746 WarmUp_Request 3 "DisableEnable_NotAvailable" 2 "DisableEnable_Error" 1 "DisableEnable_Enable" 0 "DisableEnable_Disable" ;
VAL_ 746 ParkBrakeReleasePossible_stat_IS 3 "ParkBrakeReleasePossible_stat_NotAvailable" 2 "ParkBrakeReleasePossible_stat_Error" 1 "ParkBrakeReleasePossible_stat_Possible_PressureOK" 0 "ParkBrakeReleasePossible_stat_NotPossible_LowerPressure" ;
VAL_ 746 AC_CompressorClutchCmd_ISig_2 3 "DisengageEngage_NotAvailable" 2 "DisengageEngage_Error" 1 "DisengageEngage_Engage" 0 "DisengageEngage_Disengage" ;
VAL_ 746 ESCReqEMS_CtrlTrimReq 7 "CtrlTrimReq_NotAvailable" 6 "CtrlTrimReq_Error" 5 "CtrlTrimReq_Spare_02" 4 "CtrlTrimReq_Spare_01" 3 "CtrlTrimReq_Spare" 2 "CtrlTrimReq_TrimRampDown" 1 "CtrlTrimReq_TrimRampUp" 0 "CtrlTrimReq_NoRamp" ;
VAL_ 746 Pto1Status_ISig_2 3 "InactiveActive_NotAvailable" 2 "InactiveActive_Error" 1 "InactiveActive_Active" 0 "InactiveActive_Inactive" ;
VAL_ 746 ESCReqEMS_CtrlTrimStat 7 "CtrlTrimStat_NotAvailable" 6 "CtrlTrimStat_Error" 5 "CtrlTrimStat_Spare_02" 4 "CtrlTrimStat_Spare_01" 3 "CtrlTrimStat_Spare" 2 "CtrlTrimStat_TrimActive" 1 "CtrlTrimStat_ControlActive" 0 "CtrlTrimStat_NoRequestActive" ;
VAL_ 746 CtaGcAlternativeGearStarter 3 "Request_NotAvailable" 2 "Request_Error" 1 "Request_RequestActive" 0 "Request_NotRequested" ;
VAL_ 746 Pto2ConsentRequest 3 "PtoConsentRequest_NotAvailable" 2 "PtoConsentRequest_Error" 1 "PtoConsentRequest_PTOOperationDesired" 0 "PtoConsentRequest_PTOOperationNotDesired" ;
VAL_ 746 EngPtoConsumesTorque 3 "PtoTorqueRequest_NotAvailable" 2 "PtoTorqueRequest_Error" 1 "PtoTorqueRequest_PtoIsRequestingHighTorque" 0 "PtoTorqueRequest_PtoIsNotRequestingHighTorque" ;
VAL_ 746 ESCReqEMS_CtrlTrimMode 15 "CtrlTrimMode_NotAvailable" 14 "CtrlTrimMode_Error" 13 "CtrlTrimMode_Spare_08" 12 "CtrlTrimMode_Spare_07" 11 "CtrlTrimMode_Spare_06" 10 "CtrlTrimMode_Spare_05" 9 "CtrlTrimMode_Spare_04" 8 "CtrlTrimMode_Spare_03" 7 "CtrlTrimMode_Spare_02" 6 "CtrlTrimMode_Spare_01" 5 "CtrlTrimMode_Spare" 4 "CtrlTrimMode_MuddySiteEngineSpeedControl" 3 "CtrlTrimMode_AirManagementEngineSpeedControl" 2 "CtrlTrimMode_IdleAdjust" 1 "CtrlTrimMode_PTOEngineSpeedControl" 0 "CtrlTrimMode_NoRequest" ;
VAL_ 746 TrailerABSStatus_ISig_2 3 "TrailerABSStatus_NotAvailable" 2 "TrailerABSStatus_ErrorIndicator" 1 "TrailerABSStatus_OK" 0 "TrailerABSStatus_Error" ;
VAL_ 746 CtaGcInhibitGearEngaged 3 "Inhibit_NotAvailable" 2 "Inhibit_Error" 1 "Inhibit_InhibitActive" 0 "Inhibit_NoInhibit" ;
VAL_ 746 RearEndPositionStatus_ISig_2 7 "EndPositionStatus_NotAvailable" 6 "EndPositionStatus_Error" 5 "EndPositionStatus_Reserved_01" 4 "EndPositionStatus_Reserved" 3 "EndPositionStatus_LiftingAndLoweringNotAllowed" 2 "EndPositionStatus_MinEndLevelReached" 1 "EndPositionStatus_MaxEndLevelReached" 0 "EndPositionStatus_NoEndLevelReached" ;
VAL_ 746 StoreIdleValue_ISig_2 3 "StoreIdleValue_NotAvailable" 2 "StoreIdleValue_Error" 1 "StoreIdleValue_StoreSetValue" 0 "StoreIdleValue_DoNOTStoreValue" ;
VAL_ 746 CtaGcReverseInhibit 3 "Inhibit_NotAvailable" 2 "Inhibit_Error" 1 "Inhibit_InhibitActive" 0 "Inhibit_NoInhibit" ;
VAL_ 746 AirCompressorStatus_ISig_2 3 "InactiveActive_NotAvailable" 2 "InactiveActive_Error" 1 "InactiveActive_Active" 0 "InactiveActive_Inactive" ;
VAL_ 391 ParkingBrake_stat_ISig_2 3 "ParkingBrake_stat_NotAvailable" 2 "ParkingBrake_stat_Error" 1 "ParkingBrake_stat_ParkingBrakeActivated" 0 "ParkingBrake_stat_ParkingBrakeReleased" ;
VAL_ 391 RequestedUpshiftDownshiftSteps 7 "RequestedUpshiftDownshiftSteps_NotAvailable" 6 "RequestedUpshiftDownshiftSteps_Error" 5 "RequestedUpshiftDownshiftSteps_NotDefined_01" 4 "RequestedUpshiftDownshiftSteps_NotDefined" 3 "RequestedUpshiftDownshiftSteps_ThreeSteps" 2 "RequestedUpshiftDownshiftSteps_TwoSteps" 1 "RequestedUpshiftDownshiftSteps_OneStep" 0 "RequestedUpshiftDownshiftSteps_NoRequest" ;
VAL_ 391 LiftAxle1PositionStatus_ISig_2 7 "LiftAxlePositionStatus_NotAvailable" 6 "LiftAxlePositionStatus_Error" 5 "LiftAxlePositionStatus_Reserved_01" 4 "LiftAxlePositionStatus_Reserved" 3 "LiftAxlePositionStatus_Lifting" 2 "LiftAxlePositionStatus_Lowering" 1 "LiftAxlePositionStatus_Lifted" 0 "LiftAxlePositionStatus_Lowered" ;
VAL_ 391 EngineSystemPowerDownRequest 3 "Request_NotAvailable" 2 "Request_Error" 1 "Request_RequestActive" 0 "Request_NotRequested" ;
VAL_ 391 LimpHomeSwitch_stat 3 "OffOn_NotAvailable" 2 "OffOn_Error" 1 "OffOn_On" 0 "OffOn_Off" ;
VAL_ 391 EconomyPowerSwitch_stat 3 "OffOn_NotAvailable" 2 "OffOn_Error" 1 "OffOn_On" 0 "OffOn_Off" ;
VAL_ 391 UpShiftRequest 3 "UpShiftRequest_NotAvailable" 2 "UpShiftRequest_Error" 1 "UpShiftRequest_RequestToDoUpshiftOneStep" 0 "UpShiftRequest_NoRequest" ;
VAL_ 391 EngineStopRequest 3 "Request_NotAvailable" 2 "Request_Error" 1 "Request_RequestActive" 0 "Request_NotRequested" ;
VAL_ 391 EngineOperationCtrl 7 "EngineOperationCtrl_NotAvailable" 6 "EngineOperationCtrl_Error" 5 "EngineOperationCtrl_Spare3" 4 "EngineOperationCtrl_Spare2" 3 "EngineOperationCtrl_Okwithpreparation" 2 "EngineOperationCtrl_DoNotCare" 1 "EngineOperationCtrl_RqstTempEngStopAtStandstill" 0 "EngineOperationCtrl_InhibitTempEngineStop" ;
VAL_ 391 DownShiftRequest 3 "DownShiftRequest_NotAvailable" 2 "DownShiftRequest_Error" 1 "DownShiftRequest_RequestToDownshiftOneGear" 0 "DownShiftRequest_NoRequest" ;
VAL_ 391 CM_DisengageDrivelineRequest 3 "CM_DisengageDrivelineRequest_TakeNoAction" 2 "CM_DisengageDrivelineRequest_Reserved" 1 "CM_DisengageDrivelineRequest_DisengageDriveline" 0 "CM_DisengageDrivelineRequest_AllowDrivelineEngagement" ;
VAL_ 391 TransmSystemPowerDown_rqst 3 "TransmSystemPowerDown_rqst_DontCare" 2 "TransmSystemPowerDown_rqst_NotDefined" 1 "TransmSystemPowerDown_rqst_PowerDownRequestActive" 0 "TransmSystemPowerDown_rqst_PowerDownRequestInactive" ;
VAL_ 391 ACC_Status_ISig_2 7 "ACC_Status_NotAvailable" 6 "ACC_Status_Error" 5 "ACC_Status_ACCFailureAndInactive" 4 "ACC_Status_Reserved" 3 "ACC_Status_ActiveWithLimitedBrakeCapacity" 2 "ACC_Status_ActiveECONOMYMODE" 1 "ACC_Status_ActiveSTANDARDMODE" 0 "ACC_Status_Inactive" ;
VAL_ 391 ParkBrakeActuationStatus_ISig_2 7 "ParkBrakeActuationStatus_NotAvailable" 6 "ParkBrakeActuationStatus_Error" 5 "ParkBrakeActuationStatus_SpareValue_01" 4 "ParkBrakeActuationStatus_SpareValue" 3 "ParkBrakeActuationStatus_AntiCompound" 2 "ParkBrakeActuationStatus_Parked" 1 "ParkBrakeActuationStatus_PartiallyParked" 0 "ParkBrakeActuationStatus_Released" ;
VAL_ 391 GearLeverPosition_ISig_2 15 "GearLeverPosition_NotAvailable" 14 "GearLeverPosition_Error" 13 "GearLeverPosition_SpareValue_06" 12 "GearLeverPosition_SpareValue_05" 11 "GearLeverPosition_SpareValue_04" 10 "GearLeverPosition_SpareValue_03" 9 "GearLeverPosition_SpareValue_02" 8 "GearLeverPosition_SpareValue_01" 7 "GearLeverPosition_SpareValue" 6 "GearLeverPosition_SEG6" 5 "GearLeverPosition_LowGear" 4 "GearLeverPosition_Manual" 3 "GearLeverPosition_Automatic" 2 "GearLeverPosition_Neutral" 1 "GearLeverPosition_Reverse" 0 "GearLeverPosition_GearFoldedAway" ;
VAL_ 391 EngineCrankRequest 3 "Request_NotAvailable" 2 "Request_Error" 1 "Request_RequestActive" 0 "Request_NotRequested" ;
VAL_ 391 RequestForHighestGearRatio 3 "Request_NotAvailable" 2 "Request_Error" 1 "Request_RequestActive" 0 "Request_NotRequested" ;
VAL_ 391 XARDACU_ControlMode 3 "XARControlMode_NotDefined" 2 "XARControlMode_CoastingModeRequest" 1 "XARControlMode_AccelerationControlWithMaximumMode" 0 "XARControlMode_OverrideDisabled" ;
VAL_ 391 EnginePreheat_rqst 3 "Request_NotAvailable" 2 "Request_Error" 1 "Request_RequestActive" 0 "Request_NotRequested" ;
VAL_ 391 ReqdLongAccel_CtrlMode 3 "XARControlMode_NotDefined" 2 "XARControlMode_CoastingModeRequest" 1 "XARControlMode_AccelerationControlWithMaximumMode" 0 "XARControlMode_OverrideDisabled" ;
SIG_GROUP_ 298 ReqTSC_sg 1 : ReqTSC_Tq ReqTSC_CtrlMode ReqTSC_CRC ReqTSC_SqC ReqTSC_Spd;
SIG_GROUP_ 568 EngSystPwrDwn_sg 1 : EngSystPwrDwn_Rqst EngSystPwrDwn_CRC EngSystPwrDwn_SqC;
SIG_GROUP_ 568 DriveModeSwitchStat_sg 1 : DriveModeSwitchStat_CRC DriveModeSwitchStat_SqC DriveModeSwitchStat_Rqst;
SIG_GROUP_ 568 TrnsmSystPwrDwn_sg 1 : TrnsmSystPwrDwn_SqC TrnsmSystPwrDwn_Rqst TrnsmSystPwrDwn_CRC;
SIG_GROUP_ 568 EcnmyPwrSwt_sg 1 : EcnmyPwrSwt_Sts EcnmyPwrSwt_CRC EcnmyPwrSwt_SqC;
SIG_GROUP_ 568 GearLeverPosition2_sg 1 : GearLeverPosition2_SqC GearLeverPosition2_Rqst GearLeverPosition2_CRC;
SIG_GROUP_ 568 EngCrnk_sg 1 : EngCrnk_Rqst EngCrnk_SqC EngCrnk_CRC;
SIG_GROUP_ 568 UpDownShiftRqst_sg 1 : UpDownShiftRqst_CRC UpDownShiftRqst_Rqst UpDownShiftRqst_SqC;
SIG_GROUP_ 1308 HillDataCtrlTGW_sg 1 : HillDataCtrlTGW_AckCnt HillDataCtrlTGW_State;
SIG_GROUP_ 1185 SpeedAdaptEnableRqst_sg_ISig_2 1 : SpeedAdaptEnableRqst_SpeedLimit_ SpeedAdaptEnableRqst_Curve_ISig_ SpeedAdaptEnableRqst_SlowTraffic;
SIG_GROUP_ 1060 EngOvrrideCtrlStat_sg 1 : EngOvrrideCtrlStat_FireTruckMode EngOvrrideCtrlStat_ProtOvrrMode EngOvrrideCtrlStat_StartOvrrMode;
SIG_GROUP_ 932 ReqdDrvgDir_sg 1 : ReqdDrvgDir_CRC ReqdDrvgDir_Direction ReqdDrvgDir_SqC;
SIG_GROUP_ 932 CCTrgtSpd_sg 1 : CCTrgtSpd_CRC CCTrgtSpd_Rqst CCTrgtSpd_SqC;
SIG_GROUP_ 932 CCBTrgtSpd_sg 1 : CCBTrgtSpd_CRC CCBTrgtSpd_Rqst CCBTrgtSpd_SqC;
SIG_GROUP_ 932 ReqdSGoMode_sg 1 : ReqdSGoMode_SqC ReqdSGoMode_CRC ReqdSGoMode_Mode;
SIG_GROUP_ 932 ReqdVehLongCtrlM_sg 1 : ReqdVehLongCtrlM_CRC ReqdVehLongCtrlM_SqC ReqdVehLongCtrlM_Mode;
SIG_GROUP_ 1066 TrafficSitSpdProfile_sg 1 : TrafficSitSpdProfile_MinSpd TrafficSitSpdProfile_Speed TrafficSitSpdProfile_Offset TrafficSitSpdProfile_PathIndex TrafficSitSpdProfile_MaxSpd TrafficSitSpdProfile_Type;
SIG_GROUP_ 300 XRSLTrgtSpd_sg 1 : XRSLTrgtSpd_CRC XRSLTrgtSpd_SqC XRSLTrgtSpd_Rqst;
SIG_GROUP_ 300 XRSLBTrgtSpd_sg 1 : XRSLBTrgtSpd_CRC XRSLBTrgtSpd_SqC XRSLBTrgtSpd_Rqst;
SIG_GROUP_ 300 AccPedal_sg 1 : AccPedal_Pos AccPedal_Qlty AccPedal_SqC AccPedal_CRC;
SIG_GROUP_ 746 ESCReqEMS_sg 1 : ESCReqEMS_CtrlTrimReq ESCReqEMS_CtrlTrimValue ESCReqEMS_CtrlTrimStat ESCReqEMS_CtrlTrimMode;
SIG_GROUP_ 391 XARDACU_sg 1 : XARDACU_AccelDemand XARDACU_ControlMode;
SIG_GROUP_ 391 ReqdLongAccel_sg 1 : ReqdLongAccel_SqC ReqdLongAccel_CRC ReqdLongAccel_CtrlMode ReqdLongAccel_Accel;
SIG_GROUP_ 391 ReqdLongDist_sg 1 : ReqdLongDist_AllwdBndUppr ReqdLongDist_Distance ReqdLongDist_CRC ReqdLongDist_AllwdBndLowr ReqdLongDist_SqC;
SIG_GROUP_ 391 ReqdLongSpd_sg 1 : ReqdLongSpd_CRC ReqdLongSpd_SqC ReqdLongSpd_AllwdBndUppr ReqdLongSpd_Spd ReqdLongSpd_AllwdBndLowr;
